VERSION ""

NS_ :

BS_:

BU_: CVC_I MHU TBOX FCAM_I MRR SRR_RL SRR_RR SRR_FL SRR_FR DUMMY_ECU ADCU_I AMP HUD

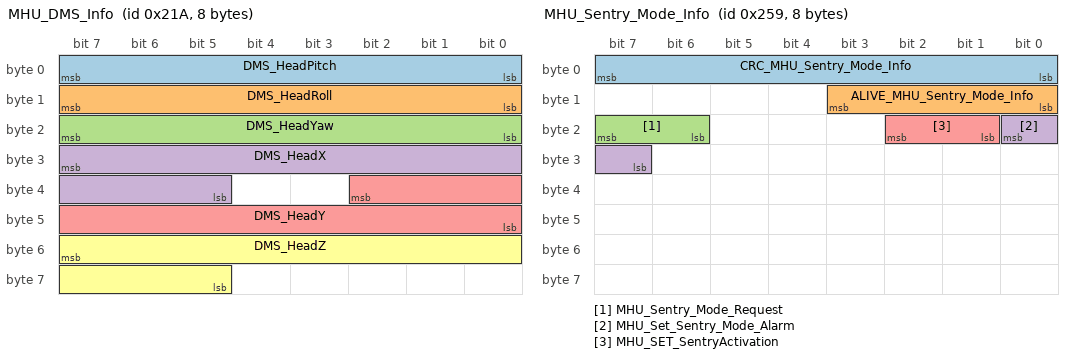
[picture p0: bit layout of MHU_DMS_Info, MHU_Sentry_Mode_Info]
BO_ 538 MHU_DMS_Info: 8 MHU
 SG_ DMS_HeadPitch : 7|8@0+ (1,-45) [-45|45] "degree"  CVC_I
 SG_ DMS_HeadRoll : 15|8@0+ (1,-45) [-45|45] "degree"  CVC_I
 SG_ DMS_HeadYaw : 23|8@0+ (1,-75) [-75|180] "degree"  CVC_I
 SG_ DMS_HeadX : 31|11@0+ (1,-500) [-500|1547] "mm"  CVC_I
 SG_ DMS_HeadY : 34|11@0+ (1,-500) [-500|1547] "mm"  CVC_I
 SG_ DMS_HeadZ : 55|11@0+ (1,-500) [-500|1547] "mm"  CVC_I

BO_ 599 MHU_RVC_Info: 8 MHU
 SG_ MHU_RVC_Request : 23|2@0+ (1,0) [0|3] ""  ADCU_I

BO_ 601 MHU_Sentry_Mode_Info: 8 MHU
 SG_ CRC_MHU_Sentry_Mode_Info : 7|8@0+ (1,0) [0|255] ""  ADCU_I
 SG_ ALIVE_MHU_Sentry_Mode_Info : 11|4@0+ (1,0) [0|15] ""  ADCU_I
 SG_ MHU_Sentry_Mode_Request : 23|2@0+ (1,0) [0|3] ""  ADCU_I
 SG_ MHU_Set_Sentry_Mode_Alarm : 16|2@0+ (1,0) [0|3] ""  ADCU_I
 SG_ MHU_SET_SentryActivation : 18|2@0+ (1,0) [0|3] ""  ADCU_I

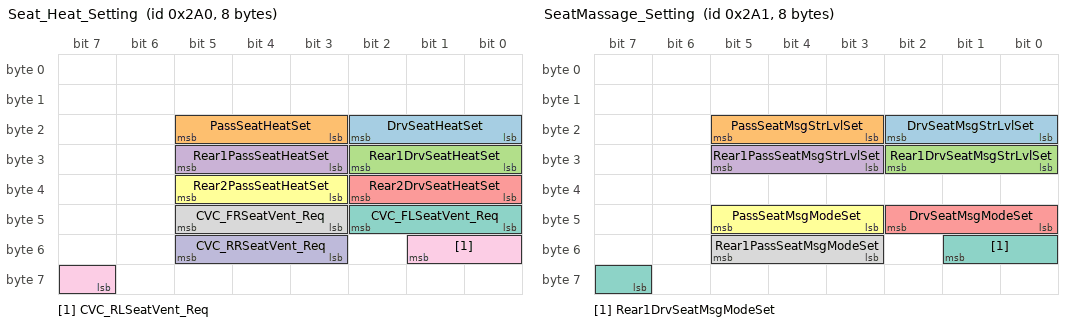
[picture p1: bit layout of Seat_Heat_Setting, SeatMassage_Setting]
BO_ 672 Seat_Heat_Setting: 8 MHU
 SG_ DrvSeatHeatSet : 18|3@0+ (1,0) [0|7] ""  CVC_I
 SG_ PassSeatHeatSet : 21|3@0+ (1,0) [0|7] ""  CVC_I
 SG_ Rear1DrvSeatHeatSet : 26|3@0+ (1,0) [0|7] "-"  CVC_I
 SG_ Rear1PassSeatHeatSet : 29|3@0+ (1,0) [0|7] ""  CVC_I
 SG_ Rear2DrvSeatHeatSet : 34|3@0+ (1,0) [0|7] ""  CVC_I
 SG_ Rear2PassSeatHeatSet : 37|3@0+ (1,0) [0|7] ""  CVC_I
 SG_ CVC_FLSeatVent_Req : 42|3@0+ (1,0) [0|7] ""  CVC_I
 SG_ CVC_FRSeatVent_Req : 45|3@0+ (1,0) [0|7] ""  CVC_I
 SG_ CVC_RLSeatVent_Req : 49|3@0+ (1,0) [0|7] ""  CVC_I
 SG_ CVC_RRSeatVent_Req : 53|3@0+ (1,0) [0|7] ""  CVC_I

BO_ 673 SeatMassage_Setting: 8 MHU
 SG_ DrvSeatMsgStrLvlSet : 18|3@0+ (1,0) [0|7] ""  CVC_I
 SG_ PassSeatMsgStrLvlSet : 21|3@0+ (1,0) [0|7] ""  CVC_I
 SG_ Rear1DrvSeatMsgStrLvlSet : 26|3@0+ (1,0) [0|7] ""  CVC_I
 SG_ Rear1PassSeatMsgStrLvlSet : 29|3@0+ (1,0) [0|7] ""  CVC_I
 SG_ DrvSeatMsgModeSet : 42|3@0+ (1,0) [0|7] ""  CVC_I
 SG_ PassSeatMsgModeSet : 45|3@0+ (1,0) [0|7] ""  CVC_I
 SG_ Rear1DrvSeatMsgModeSet : 49|3@0+ (1,0) [0|7] ""  CVC_I
 SG_ Rear1PassSeatMsgModeSet : 53|3@0+ (1,0) [0|7] ""  CVC_I

BO_ 753 MHU_IC_STAT_AIRBAG: 1 MHU
 SG_ MHU_STAT_AirbagWarnLamp : 1|2@0+ (1,0) [0|3] ""  CVC_I

BO_ 717 MHU_ADASISv2_Message_Container: 8 MHU
 SG_ MHU_ADASISv2_Container : 7|64@0+ (1,0) [0|1.84467440737096E+019] ""  FCAM_I,ADCU_I

BO_ 762 MHU_GPS_Time_UTC: 8 MHU
 SG_ MHU_GPS_Time_UTC : 7|64@0+ (1,0) [0|1.84467440737095E+019] "s"  CVC_I

BO_ 776 MHU_CPD_Confirm: 8 MHU
 SG_ MHU_CPD_Setting : 4|3@0+ (1,0) [0|7] ""  CVC_I
 SG_ MHU_CPD_Confirmation_On_HMI : 7|3@0+ (1,0) [0|7] ""  CVC_I

BO_ 788 MHU_RAEB: 24 MHU
 SG_ CRC_MHU_RAEB : 7|8@0+ (1,0) [0|255] ""  CVC_I,FCAM_I,ADCU_I
 SG_ ALIVE_MHU_RAEB : 11|4@0+ (1,0) [0|15] ""  CVC_I,FCAM_I,ADCU_I
 SG_ MHU_RAEB_check : 15|3@0+ (1,0) [0|7] ""  CVC_I,FCAM_I,ADCU_I
 SG_ MHU_RAEB_Warning : 30|3@0+ (1,0) [0|7] ""  CVC_I,FCAM_I,ADCU_I
 SG_ MHU_RAEB_State : 27|4@0+ (1,0) [0|15] ""  CVC_I,FCAM_I,ADCU_I
 SG_ MHU_RAEB_BrakeCommand : 23|3@0+ (1,0) [0|3] ""  CVC_I,FCAM_I,ADCU_I
 SG_ MHU_RAEB_Available : 17|2@0+ (1,0) [0|3] ""  CVC_I,FCAM_I,ADCU_I
 SG_ MHU_RAEB_FuncActive : 20|1@0+ (1,0) [0|1] ""  CVC_I,FCAM_I,ADCU_I
 SG_ MHU_RAEB_Mode_Feed : 19|2@0+ (1,0) [0|3] ""  CVC_I,FCAM_I,ADCU_I
 SG_ MHU_RAEB_BrakeType : 33|2@0+ (1,0) [0|3] ""  CVC_I,FCAM_I,ADCU_I
 SG_ MHU_RAEB_PullEPBOpt : 31|1@0+ (1,0) [0|1] ""  CVC_I,FCAM_I,ADCU_I
 SG_ Secure_ResetCnt_0x314 : 135|16@0+ (1,0) [0|65535] ""  CVC_I,FCAM_I,ADCU_I
 SG_ Secure_MsgCnt_0x314 : 151|16@0+ (1,0) [0|65535] ""  CVC_I,FCAM_I,ADCU_I
 SG_ Secure_MAC_0x314 : 167|32@0+ (1,0) [0|4294967295] ""  CVC_I,FCAM_I,ADCU_I
 SG_ MHU_RAEB_BrakeReq_Source : 36|3@0+ (1,0) [0|7] ""  CVC_I,FCAM_I

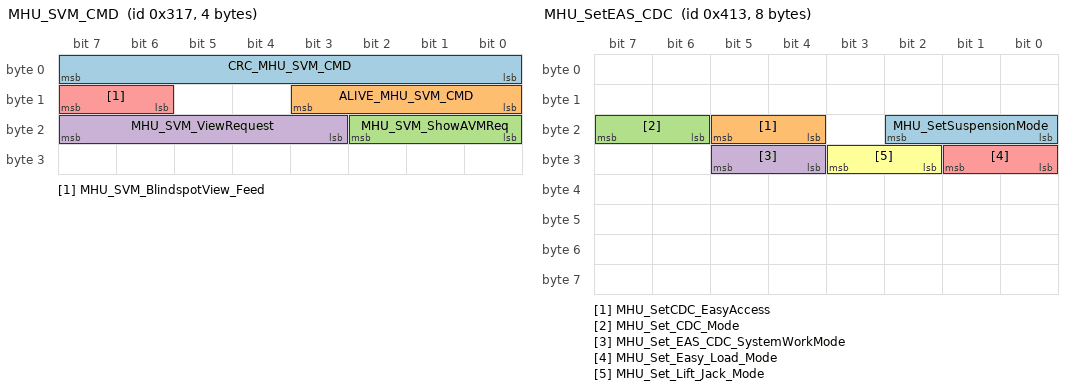
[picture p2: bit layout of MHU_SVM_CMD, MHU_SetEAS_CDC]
BO_ 791 MHU_SVM_CMD: 4 MHU
 SG_ CRC_MHU_SVM_CMD : 7|8@0+ (1,0) [0|255] ""  ADCU_I
 SG_ ALIVE_MHU_SVM_CMD : 11|4@0+ (1,0) [0|15] ""  ADCU_I
 SG_ MHU_SVM_ShowAVMReq : 18|3@0+ (1,0) [0|7] ""  ADCU_I
 SG_ MHU_SVM_ViewRequest : 23|5@0+ (1,0) [0|31] ""  ADCU_I
 SG_ MHU_SVM_BlindspotView_Feed : 15|2@0+ (1,0) [0|3] ""  ADCU_I

BO_ 800 MHU_GPS_Position_Info: 16 MHU
 SG_ Latitude : 7|32@0+ (1E-007,-180) [-180|180] "deg"  ADCU_I
 SG_ Longitude : 39|32@0+ (1E-007,-180) [-180|180] "deg"  ADCU_I
 SG_ Altitude : 71|16@0+ (0.1,-3276.7) [-3276.7|3276.7] "m"  ADCU_I
 SG_ Speed : 87|16@0+ (0.01,0) [0|655.35] "km/h"  ADCU_I
 SG_ Vertical_Speed : 103|16@0+ (0.01,-327.67) [-327.67|327.67] "m/s"  ADCU_I
 SG_ Heading : 119|16@0+ (0.010986,-360) [-180|179.995] "deg"  ADCU_I

BO_ 801 MHU_GPS_Position_DR: 20 MHU
 SG_ Latitude_DR : 7|32@0+ (1E-007,-180) [-180|180] "deg"  ADCU_I
 SG_ Longitude_DR : 39|32@0+ (1E-007,-180) [-180|180] "deg"  ADCU_I
 SG_ Course_DR : 71|16@0+ (0.01,0) [0|360] "deg"  ADCU_I
 SG_ Heading_DR : 87|16@0+ (0.010986,-360) [-180|179.995] "deg"  ADCU_I
 SG_ Heading_Std : 103|16@0+ (0.01,0) [0|655.35] "deg"  ADCU_I
 SG_ Roll : 119|16@0+ (0.010986,-360) [-180|179.995] "deg"  ADCU_I
 SG_ Pitch : 135|16@0+ (0.010986,-360) [-90.0081|89.9975] "deg"  ADCU_I
 SG_ DeadReckoning_Status : 151|8@0+ (1,0) [0|3] ""  ADCU_I

BO_ 802 MHU_GPS_Status: 20 MHU
 SG_ Unix_Timestamp : 7|32@0+ (1,0) [0|4294967295] "s"  ADCU_I
 SG_ GPS_Week : 39|16@0+ (1,0) [0|65535] "week"  ADCU_I
 SG_ Fix_Type : 55|8@0+ (1,0) [0|5] ""  ADCU_I
 SG_ Satellites_Used : 63|8@0+ (1,0) [0|255] ""  ADCU_I
 SG_ Satellites_Visible : 71|8@0+ (1,0) [0|255] ""  ADCU_I
 SG_ Fix_Quality : 79|8@0+ (1,0) [0|9] ""  ADCU_I
 SG_ HDOP : 87|16@0+ (0.01,0) [0|655.35] ""  ADCU_I
 SG_ VDOP : 103|16@0+ (0.01,0) [0|655.35] ""  ADCU_I
 SG_ PDOP : 119|16@0+ (0.01,0) [0|655.35] ""  ADCU_I
 SG_ Satellites_GPS : 135|8@0+ (1,0) [0|255] ""  ADCU_I
 SG_ Satellites_GLONASS : 143|8@0+ (1,0) [0|255] ""  ADCU_I
 SG_ Satellites_Galileo : 151|8@0+ (1,0) [0|255] ""  ADCU_I
 SG_ Satellites_BeiDou : 159|8@0+ (1,0) [0|255] ""  ADCU_I

BO_ 806 MHU_GPS_ECEF_Position: 16 MHU
 SG_ ECEF_X : 7|32@0+ (0.01,-21474836.47) [-21474836.47|21474836.47] "m"  ADCU_I
 SG_ ECEF_Y : 39|32@0+ (0.01,-21474836.47) [-21474836.47|21474836.47] "m"  ADCU_I
 SG_ ECEF_Z : 71|32@0+ (0.01,-21474836.47) [-21474836.47|21474836.47] "m"  ADCU_I
 SG_ ECEF_Std : 103|16@0+ (0.01,0) [0|655.35] "m"  ADCU_I

BO_ 804 MHU_HOD_Heating: 2 MHU
 SG_ Steering_HeatingControl : 7|2@0+ (1,0) [0|3] ""  CVC_I

BO_ 1043 MHU_SetEAS_CDC: 8 MHU
 SG_ MHU_SetSuspensionMode : 18|3@0+ (1,0) [0|7] ""  CVC_I,FCAM_I,ADCU_I
 SG_ MHU_SetCDC_EasyAccess : 21|2@0+ (1,0) [0|3] ""  CVC_I,FCAM_I,ADCU_I
 SG_ MHU_Set_CDC_Mode : 23|2@0+ (1,0) [0|3] ""  CVC_I,FCAM_I,ADCU_I
 SG_ MHU_Set_EAS_CDC_SystemWorkMode : 29|2@0+ (1,0) [0|3] ""  CVC_I,FCAM_I,ADCU_I
 SG_ MHU_Set_Easy_Load_Mode : 25|2@0+ (1,0) [0|3] ""  CVC_I,FCAM_I,ADCU_I
 SG_ MHU_Set_Lift_Jack_Mode : 27|2@0+ (1,0) [0|3] ""  CVC_I,FCAM_I,ADCU_I

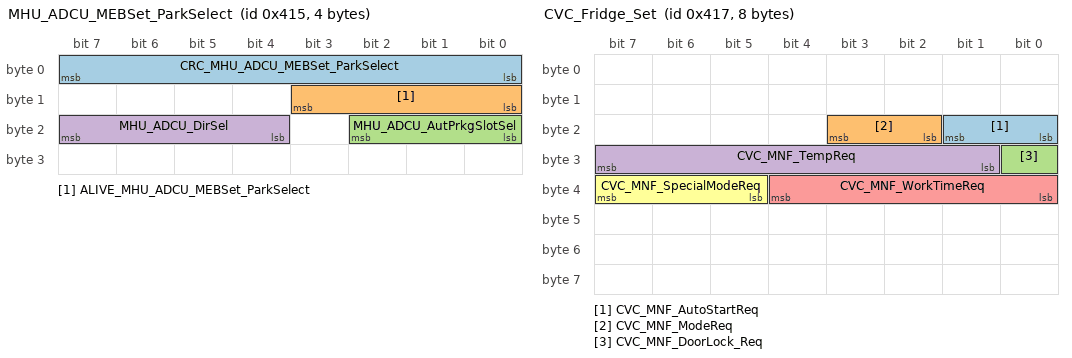
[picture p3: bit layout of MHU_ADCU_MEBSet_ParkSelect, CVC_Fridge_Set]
BO_ 1045 MHU_ADCU_MEBSet_ParkSelect: 4 MHU
 SG_ CRC_MHU_ADCU_MEBSet_ParkSelect : 7|8@0+ (1,0) [0|255] ""  ADCU_I
 SG_ ALIVE_MHU_ADCU_MEBSet_ParkSelect : 11|4@0+ (1,0) [0|15] ""  ADCU_I
 SG_ MHU_ADCU_AutPrkgSlotSel : 18|3@0+ (1,0) [0|7] ""  ADCU_I
 SG_ MHU_ADCU_DirSel : 23|4@0+ (1,0) [0|15] ""  ADCU_I

BO_ 1047 CVC_Fridge_Set: 8 CVC_I
 SG_ CVC_MNF_AutoStartReq : 17|2@0+ (1,0) [0|3] ""  MHU
 SG_ CVC_MNF_ModeReq : 19|2@0+ (1,0) [0|3] ""  MHU
 SG_ CVC_MNF_DoorLock_Req : 24|1@0+ (1,0) [0|1] ""  MHU
 SG_ CVC_MNF_TempReq : 31|7@0+ (1,-10) [-10|116] "Degree C"  MHU
 SG_ CVC_MNF_WorkTimeReq : 36|5@0+ (1,0) [0|24] "h"  MHU
 SG_ CVC_MNF_SpecialModeReq : 39|3@0+ (1,0) [0|7] ""  MHU

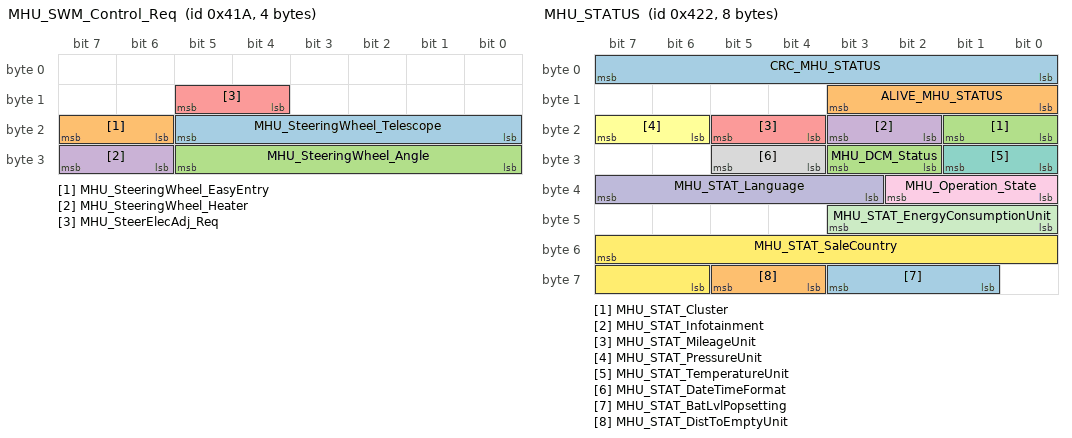
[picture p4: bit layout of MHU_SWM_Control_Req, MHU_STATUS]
BO_ 1050 MHU_SWM_Control_Req: 4 MHU
 SG_ MHU_SteeringWheel_Telescope : 21|6@0+ (1,-20) [-20|20] "mm"  CVC_I
 SG_ MHU_SteeringWheel_EasyEntry : 23|2@0+ (1,0) [0|3] ""  CVC_I
 SG_ MHU_SteeringWheel_Angle : 29|6@0+ (0.1,-2.1) [-2.1|2.1] "Degree"  CVC_I
 SG_ MHU_SteeringWheel_Heater : 31|2@0+ (1,0) [0|3] ""  CVC_I
 SG_ MHU_SteerElecAdj_Req : 13|2@0+ (1,0) [0|3] ""  CVC_I

BO_ 1058 MHU_STATUS: 8 MHU
 SG_ CRC_MHU_STATUS : 7|8@0+ (1,0) [0|255] ""  CVC_I,FCAM_I,SRR_RR,ADCU_I
 SG_ ALIVE_MHU_STATUS : 11|4@0+ (1,0) [0|15] ""  CVC_I,FCAM_I,SRR_RR,ADCU_I
 SG_ MHU_STAT_Cluster : 17|2@0+ (1,0) [0|3] ""  CVC_I,FCAM_I,SRR_RR,ADCU_I
 SG_ MHU_STAT_Infotainment : 19|2@0+ (1,0) [0|3] ""  CVC_I,FCAM_I,SRR_RR,ADCU_I
 SG_ MHU_STAT_MileageUnit : 21|2@0+ (1,0) [0|3] ""  CVC_I,FCAM_I,SRR_RR,ADCU_I
 SG_ MHU_STAT_PressureUnit : 23|2@0+ (1,0) [0|3] ""  CVC_I,ADCU_I
 SG_ MHU_STAT_TemperatureUnit : 25|2@0+ (1,0) [0|3] ""  CVC_I,ADCU_I
 SG_ MHU_STAT_DateTimeFormat : 29|2@0+ (1,0) [0|3] ""  CVC_I,ADCU_I
 SG_ MHU_Operation_State : 34|3@0+ (1,0) [0|7] ""  CVC_I,FCAM_I,SRR_RR,ADCU_I
 SG_ MHU_STAT_Language : 39|5@0+ (1,0) [0|31] ""  CVC_I,ADCU_I
 SG_ MHU_STAT_EnergyConsumptionUnit : 43|4@0+ (1,0) [0|15] ""  CVC_I,FCAM_I,SRR_RR,ADCU_I
 SG_ MHU_STAT_SaleCountry : 55|10@0+ (1,0) [0|1023] ""  CVC_I,FCAM_I,SRR_RR,ADCU_I
 SG_ MHU_STAT_BatLvlPopsetting : 59|3@0+ (1,0) [0|7] ""  CVC_I,ADCU_I
 SG_ MHU_STAT_DistToEmptyUnit : 61|2@0+ (1,0) [0|3] ""  CVC_I,ADCU_I
 SG_ MHU_DCM_Status : 27|2@0+ (1,0) [0|3] ""  CVC_I,ADCU_I

BO_ 1092 MHU_FCAM_RP_Ctrl: 24 MHU
 SG_ CRC_MHU_FCAM_RP_Ctrl : 7|8@0+ (1,0) [0|255] ""  CVC_I,FCAM_I,ADCU_I
 SG_ ALIVE_MHU_FCAM_RP_Ctrl : 11|4@0+ (1,0) [0|15] ""  CVC_I,FCAM_I,ADCU_I
 SG_ MHU_RPParkingstartReq : 15|1@0+ (1,0) [0|1] ""  CVC_I,FCAM_I,ADCU_I
 SG_ MHU_RP_ParkOutModeConfirm : 17|2@0+ (1,0) [0|3] ""  CVC_I,FCAM_I,ADCU_I
 SG_ MHU_RP_ParkOutDircnConfirm : 19|2@0+ (1,0) [0|3] ""  CVC_I,FCAM_I,ADCU_I
 SG_ MHU_RemoteconnectionSts : 23|2@0+ (1,0) [0|3] ""  CVC_I,FCAM_I,ADCU_I
 SG_ MHU_RP_FuncMode : 26|3@0+ (1,0) [0|7] ""  CVC_I,FCAM_I,ADCU_I
 SG_ MHU_SMParkingstartReq : 27|1@0+ (1,0) [0|1] ""  CVC_I,FCAM_I,ADCU_I
 SG_ MHU_SMParkingControlReq : 28|1@0+ (1,0) [0|1] ""  CVC_I,FCAM_I,ADCU_I
 SG_ MHU_RP_RecoverParking : 29|1@0+ (1,0) [0|1] ""  CVC_I,FCAM_I,ADCU_I
 SG_ MHU_RPStraightParkingDir : 31|2@0+ (1,0) [0|3] ""  CVC_I,FCAM_I,ADCU_I
 SG_ MHU_SM_global_path_Status : 33|2@0+ (1,0) [0|3] ""  CVC_I,FCAM_I,ADCU_I
 SG_ MHU_SM_QuitReq : 39|2@0+ (1,0) [0|3] ""  CVC_I,FCAM_I,ADCU_I
 SG_ MHU_RPParkingControlReq : 44|1@0+ (1,0) [0|1] ""  CVC_I,FCAM_I,ADCU_I
 SG_ MHU_RP_QuitReq : 52|2@0+ (1,0) [0|3] ""  CVC_I,FCAM_I,ADCU_I
 SG_ Secure_ResetCnt_0x444 : 135|16@0+ (1,0) [0|65535] ""  CVC_I,FCAM_I,ADCU_I
 SG_ Secure_MsgCnt_0x444 : 151|16@0+ (1,0) [0|65535] ""  CVC_I,FCAM_I,ADCU_I
 SG_ Secure_MAC_0x444 : 167|32@0+ (1,0) [0|4294967295] ""  CVC_I,FCAM_I,ADCU_I

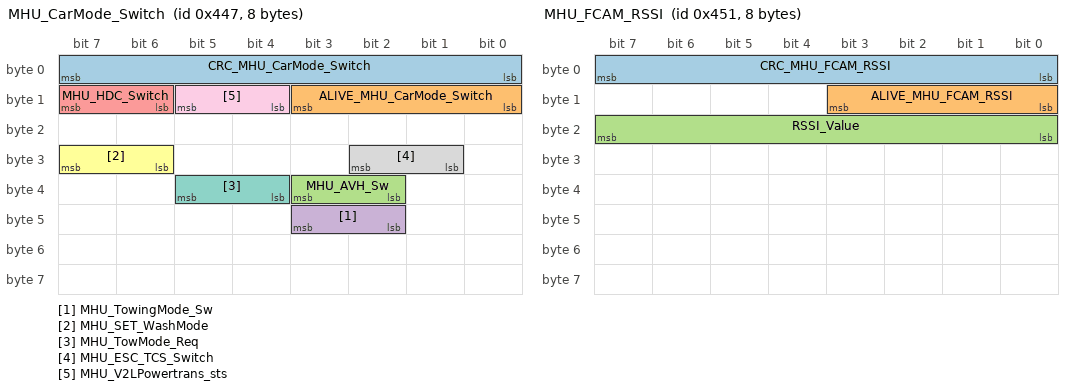
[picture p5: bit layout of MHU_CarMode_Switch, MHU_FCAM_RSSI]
BO_ 1095 MHU_CarMode_Switch: 8 MHU
 SG_ CRC_MHU_CarMode_Switch : 7|8@0+ (1,0) [0|255] ""  CVC_I
 SG_ ALIVE_MHU_CarMode_Switch : 11|4@0+ (1,0) [0|15] ""  CVC_I
 SG_ MHU_AVH_Sw : 35|2@0+ (1,0) [0|3] ""  CVC_I
 SG_ MHU_TowingMode_Sw : 43|2@0+ (1,0) [0|3] ""  CVC_I
 SG_ MHU_HDC_Switch : 15|2@0+ (1,0) [0|3] ""  CVC_I
 SG_ MHU_SET_WashMode : 31|2@0+ (1,0) [0|3] ""  CVC_I
 SG_ MHU_TowMode_Req : 37|2@0+ (1,0) [0|3] ""  CVC_I
 SG_ MHU_ESC_TCS_Switch : 26|2@0+ (1,0) [0|3] ""  CVC_I
 SG_ MHU_V2LPowertrans_sts : 13|2@0+ (1,0) [0|3] ""  CVC_I

BO_ 1105 MHU_FCAM_RSSI: 8 MHU
 SG_ CRC_MHU_FCAM_RSSI : 7|8@0+ (1,0) [0|255] ""  FCAM_I,ADCU_I
 SG_ ALIVE_MHU_FCAM_RSSI : 11|4@0+ (1,0) [0|15] ""  FCAM_I,ADCU_I
 SG_ RSSI_Value : 23|8@0+ (1,0) [0|255] ""  FCAM_I,ADCU_I

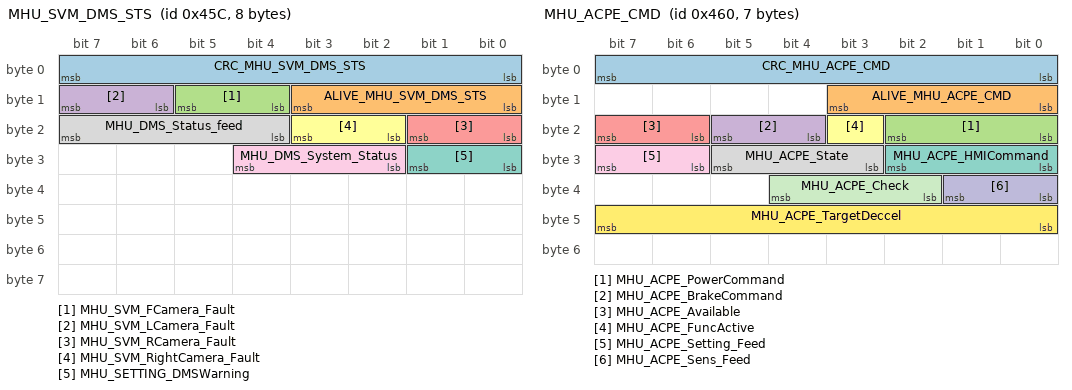
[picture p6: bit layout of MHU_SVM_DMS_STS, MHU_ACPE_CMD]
BO_ 1116 MHU_SVM_DMS_STS: 8 MHU
 SG_ CRC_MHU_SVM_DMS_STS : 7|8@0+ (1,0) [0|255] ""  CVC_I
 SG_ ALIVE_MHU_SVM_DMS_STS : 11|4@0+ (1,0) [0|15] ""  CVC_I
 SG_ MHU_SVM_FCamera_Fault : 13|2@0+ (1,0) [0|3] ""  CVC_I
 SG_ MHU_SVM_LCamera_Fault : 15|2@0+ (1,0) [0|3] ""  CVC_I
 SG_ MHU_SVM_RCamera_Fault : 17|2@0+ (1,0) [0|3] ""  CVC_I
 SG_ MHU_SVM_RightCamera_Fault : 19|2@0+ (1,0) [0|3] ""  CVC_I
 SG_ MHU_SETTING_DMSWarning : 25|2@0+ (1,0) [0|3] ""  CVC_I
 SG_ MHU_DMS_Status_feed : 23|4@0+ (1,0) [0|15] ""  CVC_I
 SG_ MHU_DMS_System_Status : 28|3@0+ (1,0) [0|7] ""  CVC_I

BO_ 1120 MHU_ACPE_CMD: 7 MHU
 SG_ CRC_MHU_ACPE_CMD : 7|8@0+ (1,0) [0|255] ""  CVC_I,FCAM_I
 SG_ ALIVE_MHU_ACPE_CMD : 11|4@0+ (1,0) [0|15] ""  CVC_I,FCAM_I
 SG_ MHU_ACPE_PowerCommand : 18|3@0+ (1,0) [0|7] ""  CVC_I
 SG_ MHU_ACPE_BrakeCommand : 21|2@0+ (1,0) [0|3] ""  CVC_I,FCAM_I
 SG_ MHU_ACPE_Available : 23|2@0+ (1,0) [0|3] ""  CVC_I,FCAM_I
 SG_ MHU_ACPE_FuncActive : 19|1@0+ (1,0) [0|1] ""  CVC_I,FCAM_I
 SG_ MHU_ACPE_HMICommand : 26|3@0+ (1,0) [0|7] ""  CVC_I
 SG_ MHU_ACPE_State : 29|3@0+ (1,0) [0|7] ""  CVC_I,FCAM_I
 SG_ MHU_ACPE_Setting_Feed : 31|2@0+ (1,0) [0|3] ""  CVC_I
 SG_ MHU_ACPE_Sens_Feed : 33|2@0+ (1,0) [0|3] ""  CVC_I
 SG_ MHU_ACPE_Check : 36|3@0+ (1,0) [0|7] ""  CVC_I,FCAM_I
 SG_ MHU_ACPE_TargetDeccel : 47|8@0+ (0.1,-6.5) [-6.5|6.5] "m/s2"  CVC_I,FCAM_I

BO_ 1969 MHU_Synchronization_Req: 8 MHU
 SG_ MHU_Req_RandomData : 7|24@0+ (1,0) [0|16777215] ""  CVC_I
 SG_ MHU_Req_MAC : 31|40@0+ (1,0) [0|1099511627775] ""  CVC_I

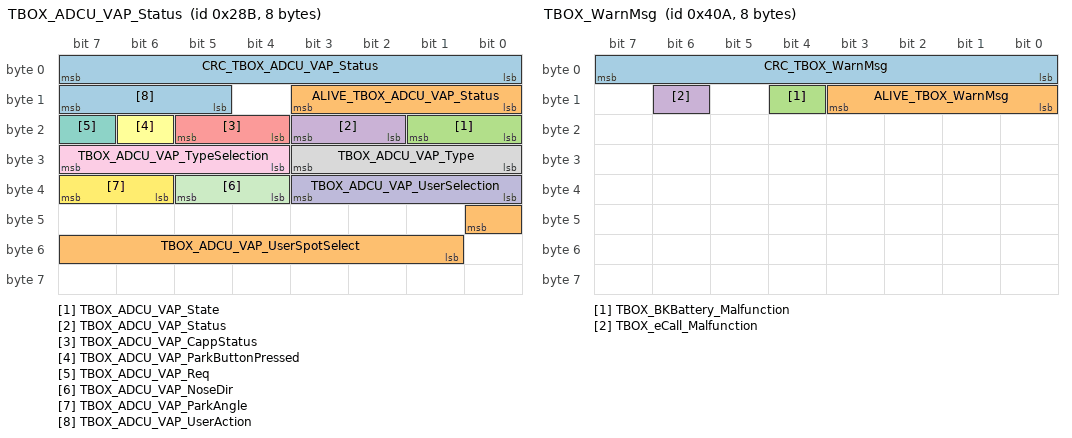
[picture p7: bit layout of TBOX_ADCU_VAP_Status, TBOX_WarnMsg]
BO_ 651 TBOX_ADCU_VAP_Status: 8 TBOX
 SG_ CRC_TBOX_ADCU_VAP_Status : 7|8@0+ (1,0) [0|255] ""  ADCU_I
 SG_ ALIVE_TBOX_ADCU_VAP_Status : 11|4@0+ (1,0) [0|15] ""  ADCU_I
 SG_ TBOX_ADCU_VAP_State : 17|2@0+ (1,0) [0|3] ""  ADCU_I
 SG_ TBOX_ADCU_VAP_Status : 19|2@0+ (1,0) [0|3] ""  ADCU_I
 SG_ TBOX_ADCU_VAP_CappStatus : 21|2@0+ (1,0) [0|3] ""  ADCU_I
 SG_ TBOX_ADCU_VAP_ParkButtonPressed : 22|1@0+ (1,0) [0|1] ""  ADCU_I
 SG_ TBOX_ADCU_VAP_Req : 23|1@0+ (1,0) [0|1] ""  ADCU_I
 SG_ TBOX_ADCU_VAP_Type : 27|4@0+ (1,0) [0|15] ""  ADCU_I
 SG_ TBOX_ADCU_VAP_TypeSelection : 31|4@0+ (1,0) [0|15] ""  ADCU_I
 SG_ TBOX_ADCU_VAP_UserSelection : 35|4@0+ (1,0) [0|15] ""  ADCU_I
 SG_ TBOX_ADCU_VAP_NoseDir : 37|2@0+ (1,0) [0|3] ""  ADCU_I
 SG_ TBOX_ADCU_VAP_ParkAngle : 39|2@0+ (1,0) [0|3] ""  ADCU_I
 SG_ TBOX_ADCU_VAP_UserAction : 15|3@0+ (1,0) [0|7] ""  ADCU_I
 SG_ TBOX_ADCU_VAP_UserSpotSelect : 40|8@0+ (1,0) [0|255] ""  ADCU_I

BO_ 761 TBOX_GPS_Time_UTC: 8 TBOX
 SG_ TBOX_GPS_Time_UTC : 7|64@0+ (1,0) [0|1.84467440737095E+019] "s"  CVC_I,MHU

BO_ 1033 TBOX_IntrusionAlertStatus: 8 TBOX
 SG_ TBOX_IntrusionAlertStatus : 31|2@0+ (1,0) [0|3] ""  CVC_I

BO_ 1034 TBOX_WarnMsg: 8 TBOX
 SG_ CRC_TBOX_WarnMsg : 7|8@0+ (1,0) [0|255] ""  MHU
 SG_ ALIVE_TBOX_WarnMsg : 11|4@0+ (1,0) [0|15] ""  MHU
 SG_ TBOX_BKBattery_Malfunction : 12|1@0+ (1,0) [0|1] ""  MHU
 SG_ TBOX_eCall_Malfunction : 14|1@0+ (1,0) [0|1] ""  MHU

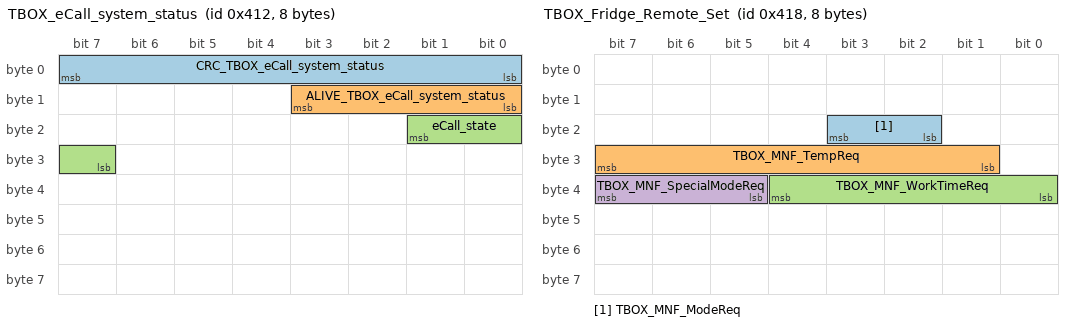
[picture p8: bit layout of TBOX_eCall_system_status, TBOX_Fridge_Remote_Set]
BO_ 1042 TBOX_eCall_system_status: 8 TBOX
 SG_ CRC_TBOX_eCall_system_status : 7|8@0+ (1,0) [0|255] ""  CVC_I,MHU,FCAM_I,SRR_RR,ADCU_I
 SG_ ALIVE_TBOX_eCall_system_status : 11|4@0+ (1,0) [0|15] ""  CVC_I,MHU,FCAM_I,SRR_RR,ADCU_I
 SG_ eCall_state : 17|3@0+ (1,0) [0|7] ""  CVC_I,MHU,FCAM_I,SRR_RR,ADCU_I

BO_ 1046 TBOX_GPS_ALTITUDE: 8 TBOX
 SG_ TBOX_GPS_ALTITUDE : 23|17@0+ (0.1,-4000) [-4000|9000] "m"  CVC_I,MHU,FCAM_I

BO_ 1048 TBOX_Fridge_Remote_Set: 8 TBOX
 SG_ TBOX_MNF_ModeReq : 19|2@0+ (1,0) [0|3] ""  CVC_I
 SG_ TBOX_MNF_TempReq : 31|7@0+ (1,-10) [-10|116] "Degree C"  CVC_I
 SG_ TBOX_MNF_WorkTimeReq : 36|5@0+ (1,0) [0|24] "h"  CVC_I
 SG_ TBOX_MNF_SpecialModeReq : 39|3@0+ (1,0) [0|7] ""  CVC_I

BO_ 128 FCAM_TSR_STATUS: 12 FCAM_I
 SG_ CRC_FCAM_TSR_STATUS : 7|8@0+ (1,0) [0|255] ""  CVC_I,MHU,ADCU_I
 SG_ ALIVE_FCAM_TSR_STATUS : 11|4@0+ (1,0) [0|15] ""  CVC_I,MHU,ADCU_I
 SG_ FCAM_TSR_PopUp_Feed : 15|4@0+ (1,0) [0|15] ""  CVC_I,MHU,ADCU_I
 SG_ FCAM_TSR_SLAert_Feed : 18|2@0+ (1,0) [0|3] ""  CVC_I,MHU,ADCU_I
 SG_ FCAM_TSR_Typ2_value : 23|5@0+ (1,0) [0|31] ""  CVC_I,MHU,ADCU_I
 SG_ FCAM_TSR_Typ1 : 26|3@0+ (1,0) [0|7] ""  CVC_I,MHU,ADCU_I
 SG_ FCAM_TSR_Typ1_value : 31|5@0+ (1,0) [0|31] ""  CVC_I,MHU,ADCU_I
 SG_ FCAM_TSR_Warning_audible : 16|1@0+ (1,0) [0|1] ""  CVC_I,MHU,ADCU_I
 SG_ FCAM_TSR_Typ2_Flashing_Warning : 34|1@0+ (1,0) [0|1] ""  CVC_I,MHU,ADCU_I
 SG_ FCAM_TSR_Mode_Feed : 36|2@0+ (1,0) [0|3] ""  CVC_I,MHU,ADCU_I
 SG_ FCAM_TSR_AudWarning_Feed : 39|3@0+ (1,0) [0|1] ""  CVC_I,MHU,ADCU_I
 SG_ FCAM_TSR_Typ1_Flashing_Warning : 33|1@0+ (1,0) [0|1] ""  CVC_I,MHU,ADCU_I
 SG_ FCAM_TSR_Typ3 : 52|9@0+ (1,0) [0|511] ""  CVC_I,MHU,ADCU_I
 SG_ FCAM_TSR_Typ2 : 45|9@0+ (1,0) [0|511] ""  CVC_I,MHU,ADCU_I
 SG_ FCAM_TSR_State : 32|3@0+ (1,0) [0|7] ""  CVC_I,MHU,ADCU_I
 SG_ FCAM_TSR_Haptic_Mode_Feed : 59|1@0+ (1,0) [0|1] ""  CVC_I,MHU,ADCU_I
 SG_ FCAM_SLW_Mode_Feed : 58|1@0+ (1,0) [0|1] ""  CVC_I,MHU,ADCU_I
 SG_ FCAM_DNS_Popup_Feed : 57|2@0+ (1,0) [0|3] ""  CVC_I,MHU,ADCU_I
 SG_ FCAM_TSR_Typ1_Distance : 71|20@0+ (1,0) [0|1048575] "m"  ADCU_I

BO_ 295 FCAM_LDW_LKA_ELK: 8 FCAM_I
 SG_ CRC_FCAM_LDW_LKA_ELK : 7|8@0+ (1,0) [0|255] ""  CVC_I,MHU,ADCU_I
 SG_ ALIVE_FCAM_LDW_LKA_ELK : 11|4@0+ (1,0) [0|15] ""  CVC_I,MHU,ADCU_I
 SG_ FCAM_ELKA_ON_feed : 12|1@0+ (1,0) [0|1] ""  CVC_I,MHU
 SG_ FCAM_LKA_HOD_state : 32|1@0+ (1,0) [0|1] ""  CVC_I,MHU
 SG_ FCAM_ECU_check : 19|2@0+ (1,0) [0|3] ""  CVC_I,MHU,ADCU_I
 SG_ FCAM_LA_sens_Feed : 21|2@0+ (1,0) [0|3] ""  CVC_I,MHU
 SG_ FCAM_LKA_ICON_Feed : 29|3@0+ (1,0) [0|7] ""  CVC_I,MHU
 SG_ FCAM_LDW_check : 17|2@0+ (1,0) [0|3] ""  CVC_I,MHU,ADCU_I
 SG_ FCAM_LKA_check : 31|2@0+ (1,0) [0|3] ""  CVC_I,MHU,ADCU_I
 SG_ FCAM_LA_popup : 39|3@0+ (1,0) [0|7] ""  CVC_I,MHU
 SG_ FCAM_LA_Mode_Feed : 44|3@0+ (1,0) [0|7] ""  CVC_I,MHU
 SG_ FCAM_LA_LeftLaneColor_Feed : 26|3@0+ (1,0) [0|7] ""  CVC_I,MHU
 SG_ FCAM_LA_RightLaneColor_Feed : 15|3@0+ (1,0) [0|7] ""  CVC_I,MHU
 SG_ FCAM_ELK_check : 23|2@0+ (1,0) [0|3] ""  CVC_I,MHU,ADCU_I
 SG_ FCAM_ELK_State : 47|3@0+ (1,0) [0|7] ""  CVC_I,MHU
 SG_ FCAM_LKA_State : 60|3@0+ (1,0) [0|7] ""  CVC_I,MHU
 SG_ FCAM_LDW_State : 51|3@0+ (1,0) [0|7] ""  CVC_I,MHU
 SG_ FCAM_ELK_Warning : 55|4@0+ (1,0) [0|15] ""  CVC_I,MHU
 SG_ FCAM_LDW_Warning : 41|2@0+ (1,0) [0|3] ""  CVC_I,MHU
 SG_ FCAM_handsoff_Warning_Mode_2 : 63|3@0+ (1,0) [0|7] ""  CVC_I,MHU
 SG_ FCAM_LKA_LDW_Haptic_Mode_Feed : 34|1@0+ (1,0) [0|3] ""  CVC_I,MHU
 SG_ FCAM_ELK_Haptic_Mode_Feed : 33|1@0+ (1,0) [0|3] ""  CVC_I,MHU
 SG_ FCAM_LKA_Warning : 36|2@0+ (1,0) [0|3] ""  CVC_I,MHU

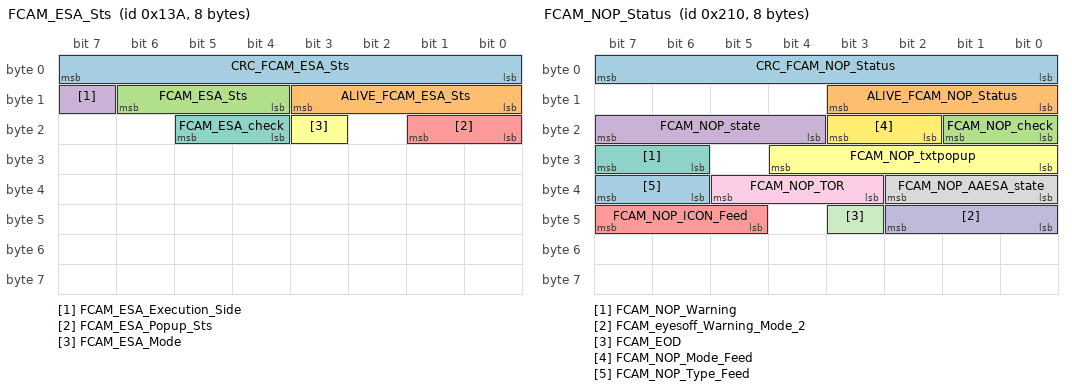
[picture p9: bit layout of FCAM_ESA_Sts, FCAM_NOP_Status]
BO_ 314 FCAM_ESA_Sts: 8 FCAM_I
 SG_ CRC_FCAM_ESA_Sts : 7|8@0+ (1,0) [0|255] ""  CVC_I,MHU,ADCU_I
 SG_ ALIVE_FCAM_ESA_Sts : 11|4@0+ (1,0) [0|15] ""  CVC_I,MHU,ADCU_I
 SG_ FCAM_ESA_Sts : 14|3@0+ (1,0) [0|7] ""  CVC_I,MHU
 SG_ FCAM_ESA_Execution_Side : 15|1@0+ (1,0) [0|1] ""  CVC_I,MHU
 SG_ FCAM_ESA_Popup_Sts : 17|2@0+ (1,0) [0|3] ""  CVC_I,MHU
 SG_ FCAM_ESA_Mode : 19|1@0+ (1,0) [0|1] ""  CVC_I,MHU
 SG_ FCAM_ESA_check : 21|2@0+ (1,0) [0|3] ""  CVC_I,MHU,ADCU_I

BO_ 515 FCAM_Display_Info: 16 FCAM_I
 SG_ CRC_FCAM_Display_Info : 7|8@0+ (1,0) [0|255] ""  CVC_I,MHU,ADCU_I
 SG_ ALIVE_FCAM_Display_Info : 11|4@0+ (1,0) [0|15] ""  CVC_I,MHU,ADCU_I
 SG_ R1_LINE_TYPE : 13|2@0+ (1,0) [0|3] ""  CVC_I,MHU
 SG_ R0_LINE_TYPE : 15|2@0+ (1,0) [0|3] ""  CVC_I,MHU
 SG_ FCAM_CIPV_RelLgtVel : 23|16@0+ (1,-32768) [-32768|32767] "MPS"  CVC_I,MHU
 SG_ FCAM_CIPV_OffsetEgoLane : 39|16@0+ (1,-32768) [-32768|32767] "M"  CVC_I,MHU
 SG_ FCAM_CIPV_OffseLaneLine : 55|16@0+ (1,-32768) [-32768|32767] "M"  CVC_I,MHU
 SG_ FCAM_Camera_R1_Line_Type : 71|2@0+ (1,0) [0|3] ""  CVC_I,MHU
 SG_ FCAM_Camera_L1_Line_Type : 69|2@0+ (1,0) [0|3] ""  CVC_I,MHU
 SG_ FCAM_R0_ExistProbability : 67|4@0+ (0.1,0) [0|1] ""  CVC_I,MHU
 SG_ FCAM_L0_ExistProbability : 79|4@0+ (0.1,0) [0|1] ""  CVC_I,MHU
 SG_ FCAM_L1_ExistProbability : 75|4@0+ (0.1,0) [0|1] ""  CVC_I,MHU
 SG_ FCAM_R1_ExistProbability : 87|4@0+ (0.1,0) [0|1] ""  CVC_I,MHU
 SG_ FCAM_ISA_SpeedLimitCnt_Spd_Feed : 83|4@0+ (1,0) [0|15] ""  CVC_I,MHU
 SG_ FCAM_ISA_SpeedLimitCnt_Per_Feed : 95|3@0+ (1,0) [0|7] ""  CVC_I,MHU
 SG_ L1_LINE_TYPE : 90|2@0+ (1,0) [0|3] ""  CVC_I,MHU
 SG_ L0_LINE_TYPE : 103|2@0+ (1,0) [0|3] ""  CVC_I,MHU
 SG_ FCAM_SCAM_Fault : 101|2@0+ (1,0) [0|3] ""  CVC_I,MHU,ADCU_I
 SG_ FCAM_MRR_Fault : 99|2@0+ (1,0) [0|3] ""  CVC_I,MHU,ADCU_I
 SG_ FCAM_Collision_Obj_ID : 111|8@0+ (1,0) [0|255] ""  MHU

BO_ 518 FCAM_HWA_ALC: 12 FCAM_I
 SG_ CRC_FCAM_HWA_ALC : 7|8@0+ (1,0) [0|255] ""  CVC_I,MHU,ADCU_I
 SG_ ALIVE_FCAM_HWA_ALC : 11|4@0+ (1,0) [0|15] ""  CVC_I,MHU,ADCU_I
 SG_ FCAM_HWA_Fautlstate : 13|2@0+ (1,0) [0|3] ""  CVC_I,MHU,ADCU_I
 SG_ FCAM_ALC_Mode_feed : 15|2@0+ (1,0) [0|3] ""  CVC_I,MHU,ADCU_I
 SG_ FCAM_HWA_txtpopup : 23|4@0+ (1,0) [0|15] ""  CVC_I,MHU,ADCU_I
 SG_ FCAM_HWA_state : 19|4@0+ (1,0) [0|15] ""  CVC_I,MHU,ADCU_I
 SG_ FCAM_ALC_txtpopup : 39|4@0+ (1,0) [0|15] ""  CVC_I,MHU,ADCU_I
 SG_ FCAM_ALC_state : 26|3@0+ (1,0) [0|7] ""  CVC_I,MHU,ADCU_I
 SG_ FCAM_AESA_DoorUnlock_Req : 32|1@0+ (1,0) [0|1] ""  CVC_I,MHU,ADCU_I
 SG_ FCAM_AESA_ECALL_Req : 33|1@0+ (1,0) [0|1] ""  CVC_I,MHU,TBOX,ADCU_I
 SG_ FCAM_AESA_Status : 35|2@0+ (1,0) [0|3] ""  CVC_I,MHU,ADCU_I
 SG_ FCAM_AESA_popup : 55|8@0+ (1,0) [0|6] ""  CVC_I,MHU,ADCU_I
 SG_ FCAM_TakeOver_Request : 31|5@0+ (1,0) [0|31] ""  CVC_I,MHU,ADCU_I
 SG_ FCAM_Sounds_Feed : 47|5@0+ (1,0) [0|31] ""  CVC_I,MHU,ADCU_I
 SG_ FCAM_ALC_ICON_Feed : 59|4@0+ (1,0) [0|15] ""  CVC_I,MHU,ADCU_I
 SG_ FCAM_HWA_ICON_Feed : 42|3@0+ (1,0) [0|7] ""  CVC_I,MHU,ADCU_I
 SG_ FCAM_ALC_Mode_Gaze_Feed : 63|2@0+ (1,0) [0|3] ""  CVC_I,MHU,ADCU_I
 SG_ FCAM_ALC_Mode_Recommend_Feed : 61|2@0+ (1,0) [0|3] ""  CVC_I,MHU,ADCU_I
 SG_ FCAM_HWA_check : 65|2@0+ (1,0) [0|3] ""  CVC_I,MHU,ADCU_I
 SG_ FCAM_MHU_ALC_Option_feed : 67|2@0+ (1,0) [0|3] ""  CVC_I,MHU,ADCU_I
 SG_ FCAM_EOR_warning : 70|3@0+ (1,0) [0|7] ""  CVC_I,MHU,ADCU_I
 SG_ FCAM_HWA_Mode_Feed : 71|1@0+ (1,0) [0|1] ""  CVC_I,MHU,ADCU_I

BO_ 527 FCAM_LKA_ELK: 24 FCAM_I
 SG_ CRC_FCAM_LKA_ELK : 7|8@0+ (1,0) [0|255] ""  CVC_I,MHU
 SG_ ALIVE_FCAM_LKA_ELK : 11|4@0+ (1,0) [0|15] ""  CVC_I,MHU
 SG_ FCAM_ELK_ONCM_VEH : 14|1@0+ (1,0) [0|1] ""  CVC_I,MHU
 SG_ FCAM_ELK_ONCM_TTC : 71|16@0+ (1,0) [0|65535] ""  CVC_I,MHU
 SG_ FCAM_ELK_OVTVEH_L : 13|1@0+ (1,0) [0|1] ""  CVC_I,MHU
 SG_ FCAM_ELK_OVTVEH_R : 12|1@0+ (1,0) [0|1] ""  CVC_I,MHU
 SG_ FCAM_ELK_OVTVEHLEFT_TTC : 55|16@0+ (1,0) [0|65535] ""  CVC_I,MHU
 SG_ FCAM_ELK_OVTVEHRIGHT_TTC : 167|16@0+ (1,0) [0|65535] ""  CVC_I,MHU
 SG_ FCAM_LKA_LATDIS_LEFT : 143|8@0+ (0.1,-12.7) [-12.7|12.8] ""  CVC_I,MHU
 SG_ FCAM_LKA_LATDIS_RIGHT : 119|8@0+ (0.1,-12.7) [-12.7|12.8] ""  CVC_I,MHU
 SG_ FCAM_LKA_LATVEL_LEFT : 87|16@0+ (1,-32768) [-32768|32767] ""  CVC_I,MHU
 SG_ FCAM_LKA_LATVEL_RIGHT : 39|16@0+ (1,-32768) [-32768|32767] ""  CVC_I,MHU
 SG_ FCAM_ALCA_REAROBJLEFT_TTC : 183|16@0+ (1,0) [0|65535] ""  CVC_I,MHU
 SG_ FCAM_ALCA_REAROBJRIGHT_TTC : 151|16@0+ (1,0) [0|65535] ""  CVC_I,MHU
 SG_ FCAM_LATERACC_Filtered : 127|16@0+ (0.002,-65.532) [-65.532|65.532] ""  CVC_I,MHU
 SG_ FCAM_ADAS_HOD : 23|8@0+ (1,0) [0|7] ""  CVC_I,MHU

BO_ 528 FCAM_NOP_Status: 8 FCAM_I
 SG_ CRC_FCAM_NOP_Status : 7|8@0+ (1,0) [0|255] ""  CVC_I,MHU,ADCU_I
 SG_ ALIVE_FCAM_NOP_Status : 11|4@0+ (1,0) [0|15] ""  CVC_I,MHU,ADCU_I
 SG_ FCAM_NOP_check : 17|2@0+ (1,0) [0|3] ""  CVC_I,MHU,ADCU_I
 SG_ FCAM_NOP_state : 23|4@0+ (1,0) [0|15] ""  CVC_I,MHU,ADCU_I
 SG_ FCAM_NOP_ICON_Feed : 47|3@0+ (1,0) [0|7] ""  CVC_I,MHU,ADCU_I
 SG_ FCAM_NOP_txtpopup : 28|5@0+ (1,0) [0|31] ""  CVC_I,MHU,ADCU_I
 SG_ FCAM_NOP_Warning : 31|2@0+ (1,0) [0|3] ""  CVC_I,MHU,ADCU_I
 SG_ FCAM_NOP_AAESA_state : 34|3@0+ (1,0) [0|7] ""  CVC_I,MHU,ADCU_I
 SG_ FCAM_NOP_TOR : 37|3@0+ (1,0) [0|7] ""  CVC_I,MHU,ADCU_I
 SG_ FCAM_eyesoff_Warning_Mode_2 : 42|3@0+ (1,0) [0|7] ""  CVC_I,MHU,ADCU_I
 SG_ FCAM_EOD : 43|1@0+ (1,0) [0|1] ""  CVC_I,MHU,ADCU_I
 SG_ FCAM_NOP_Mode_Feed : 19|2@0+ (1,0) [0|3] ""  CVC_I,MHU,ADCU_I
 SG_ FCAM_NOP_Type_Feed : 39|2@0+ (1,0) [0|3] ""  CVC_I,MHU,ADCU_I

BO_ 540 FCAM_AEB_FCW: 12 FCAM_I
 SG_ CRC_FCAM_AEB_FCW : 7|8@0+ (1,0) [0|255] ""  CVC_I,MHU,ADCU_I
 SG_ ALIVE_FCAM_AEB_FCW : 11|4@0+ (1,0) [0|15] ""  CVC_I,MHU,ADCU_I
 SG_ FCAM_AEB_Warning : 13|2@0+ (1,0) [0|3] ""  CVC_I,MHU,ADCU_I
 SG_ FCAM_AEB_State : 16|3@0+ (1,0) [0|7] ""  CVC_I,MHU,ADCU_I
 SG_ FCAM_AEB_Mode_Feed : 23|2@0+ (1,0) [0|3] ""  CVC_I,MHU,ADCU_I
 SG_ FCAM_AEB_check : 15|2@0+ (1,0) [0|3] ""  CVC_I,MHU,ADCU_I
 SG_ FCAM_FCW_Mode_Feed : 21|1@0+ (1,0) [0|1] ""  CVC_I,MHU,ADCU_I
 SG_ FCAM_FCW_Sens_Feed : 20|2@0+ (1,0) [0|3] ""  CVC_I,MHU,ADCU_I
 SG_ FCAM_FCW_state : 18|2@0+ (1,0) [0|3] ""  CVC_I,MHU,ADCU_I
 SG_ FCAM_FCW_check : 41|2@0+ (1,0) [0|3] ""  CVC_I,MHU,ADCU_I
 SG_ FCAM_FCW_warning : 43|2@0+ (1,0) [0|3] ""  CVC_I,MHU,ADCU_I
 SG_ FCAM_CV_AEB_Alert : 28|1@0+ (1,0) [0|1] ""  CVC_I,MHU,ADCU_I
 SG_ FCAM_CV_FCW_Alert : 27|1@0+ (1,0) [0|1] ""  CVC_I,MHU,ADCU_I
 SG_ FCAM_CV_PartialAEB_Alert : 26|1@0+ (1,0) [0|1] ""  CVC_I,MHU,ADCU_I
 SG_ FCAM_CV_PreFill_Alert : 25|1@0+ (1,0) [0|1] ""  CVC_I,MHU,ADCU_I
 SG_ FCAM_VD_AEB_Alert : 32|1@0+ (1,0) [0|1] ""  CVC_I,MHU,ADCU_I
 SG_ FCAM_VD_DBS_Alert : 33|1@0+ (1,0) [0|1] ""  CVC_I,MHU,ADCU_I
 SG_ FCAM_VD_EGOTAP_AEB_Alert : 34|1@0+ (1,0) [0|1] ""  CVC_I,MHU,ADCU_I
 SG_ FCAM_VD_FCW_Alert : 35|1@0+ (1,0) [0|1] ""  CVC_I,MHU,ADCU_I
 SG_ FCAM_VD_HeadOn_AEB_Alert : 36|1@0+ (1,0) [0|1] ""  CVC_I,MHU,ADCU_I
 SG_ FCAM_VD_PartialAEB_Alert : 37|1@0+ (1,0) [0|1] ""  CVC_I,MHU,ADCU_I
 SG_ FCAM_VD_Prefill_Alert : 38|1@0+ (1,0) [0|1] ""  CVC_I,MHU,ADCU_I
 SG_ FCAM_VRU_AEB_Alert : 24|1@0+ (1,0) [0|1] ""  CVC_I,MHU,ADCU_I
 SG_ FCAM_VRU_FCW_Alert : 39|1@0+ (1,0) [0|1] ""  CVC_I,MHU,ADCU_I
 SG_ FCAM_VRU_PreFill_Alert : 29|1@0+ (1,0) [0|1] ""  CVC_I,MHU,ADCU_I
 SG_ FCAM_Fusion_TTC : 55|16@0+ (1,0) [0|65535] "ms"  CVC_I,MHU,ADCU_I
 SG_ FCAM_AB_TTC : 71|16@0+ (1,0) [0|65535] "ms"  CVC_I,MHU,ADCU_I
 SG_ FCAM_AEB_Trigger_Source : 45|2@0+ (1,0) [0|3] ""  CVC_I,MHU,ADCU_I
 SG_ FCAM_FCW_Trigger_Source : 47|2@0+ (1,0) [0|3] ""  CVC_I,MHU,ADCU_I
 SG_ FCAM_AEB_BrakeReq_Source : 87|3@0+ (1,0) [0|7] ""  CVC_I,MHU,ADCU_I

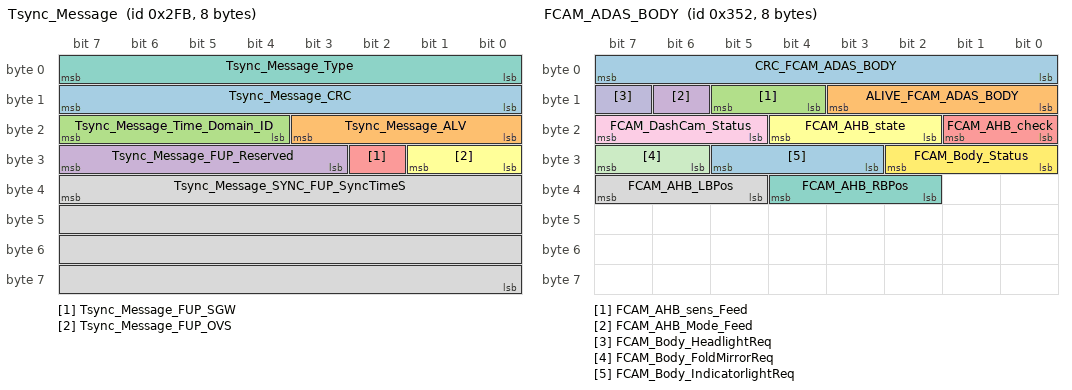
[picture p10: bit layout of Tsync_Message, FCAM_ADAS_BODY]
BO_ 763 Tsync_Message: 8 FCAM_I
 SG_ Tsync_Message_CRC : 15|8@0+ (1,0) [0|255] ""  MRR,SRR_RL,SRR_RR,SRR_FL,SRR_FR,ADCU_I
 SG_ Tsync_Message_ALV : 19|4@0+ (1,0) [0|15] ""  MRR,SRR_RL,SRR_RR,SRR_FL,SRR_FR,ADCU_I
 SG_ Tsync_Message_Time_Domain_ID : 23|4@0+ (1,0) [0|15] ""  MRR,SRR_RL,SRR_RR,SRR_FL,SRR_FR,ADCU_I
 SG_ Tsync_Message_FUP_Reserved : 31|5@0+ (1,0) [0|32] ""  MRR,SRR_RL,SRR_RR,SRR_FL,SRR_FR,ADCU_I
 SG_ Tsync_Message_FUP_SGW : 26|1@0+ (1,0) [0|1] ""  MRR,SRR_RL,SRR_RR,SRR_FL,SRR_FR,ADCU_I
 SG_ Tsync_Message_FUP_OVS : 25|2@0+ (1,0) [0|3] ""  MRR,SRR_RL,SRR_RR,SRR_FL,SRR_FR,ADCU_I
 SG_ Tsync_Message_Type : 7|8@0+ (1,0) [0|255] ""  MRR,SRR_RL,SRR_RR,SRR_FL,SRR_FR,ADCU_I
 SG_ Tsync_Message_SYNC_FUP_SyncTimeS : 39|32@0+ (1,0) [0|4290000000] "s"  MRR,SRR_RL,SRR_RR,SRR_FL,SRR_FR,ADCU_I

BO_ 833 FCAM_Camera_Perception: 64 FCAM_I
 SG_ CRC_FCAM_Camera_Perception : 7|8@0+ (1,0) [0|255] ""  MHU
 SG_ ALIVE_FCAM_Camera_Perception : 11|4@0+ (1,0) [0|15] ""  MHU
 SG_ FCAM_OBJ01_Class : 23|4@0+ (1,0) [0|12] ""  MHU
 SG_ FCAM_OBJ01_LgtDis : 107|14@0+ (0.025,-10) [-10|399.575] ""  MHU
 SG_ FCAM_OBJ01_ID : 199|8@0+ (1,0) [0|255] ""  MHU
 SG_ FCAM_OBJ01_LatDis : 55|10@0+ (0.0293,-15.0146) [-15.0146|14.9593] ""  MHU
 SG_ FCAM_OBJ01_ClosestSurface : 390|3@0+ (1,0) [0|7] ""  MHU
 SG_ FCAM_OBJ02_Class : 19|4@0+ (1,0) [0|12] ""  MHU
 SG_ FCAM_OBJ02_LgtDis : 125|14@0+ (0.025,-10) [-10|399.575] ""  MHU
 SG_ FCAM_OBJ02_ID : 207|8@0+ (1,0) [0|255] ""  MHU
 SG_ FCAM_OBJ02_LatDis : 61|10@0+ (0.0293,-15.0146) [-15.0146|14.9593] ""  MHU
 SG_ FCAM_OBJ02_ClosestSurface : 387|3@0+ (1,0) [0|7] ""  MHU
 SG_ FCAM_OBJ03_Class : 31|4@0+ (1,0) [0|12] ""  MHU
 SG_ FCAM_OBJ03_LgtDis : 143|14@0+ (0.025,-10) [-10|399.575] ""  MHU
 SG_ FCAM_OBJ03_ID : 215|8@0+ (1,0) [0|255] ""  MHU
 SG_ FCAM_OBJ03_LatDis : 67|10@0+ (0.0293,-15.0146) [-15.0146|14.9593] ""  MHU
 SG_ FCAM_OBJ03_ClosestSurface : 384|3@0+ (1,0) [0|7] ""  MHU
 SG_ FCAM_OBJ04_Class : 35|4@0+ (1,0) [0|12] ""  MHU
 SG_ FCAM_OBJ04_LgtDis : 145|14@0+ (0.025,-10) [-10|399.575] ""  MHU
 SG_ FCAM_OBJ04_ID : 223|8@0+ (1,0) [0|255] ""  MHU
 SG_ FCAM_OBJ04_LatDis : 73|10@0+ (0.0293,-15.0146) [-15.0146|14.9593] ""  MHU
 SG_ FCAM_OBJ04_ClosestSurface : 397|3@0+ (1,0) [0|7] ""  MHU
 SG_ FCAM_OBJ05_Class : 27|4@0+ (1,0) [0|12] ""  MHU
 SG_ FCAM_OBJ05_LgtDis : 163|14@0+ (0.025,-10) [-10|399.575] ""  MHU
 SG_ FCAM_OBJ05_ID : 231|8@0+ (1,0) [0|255] ""  MHU
 SG_ FCAM_OBJ05_LatDis : 95|10@0+ (0.0293,-15.0146) [-15.0146|14.9593] ""  MHU
 SG_ FCAM_OBJ05_ClosestSurface : 394|3@0+ (1,0) [0|7] ""  MHU
 SG_ FCAM_OBJ06_Class : 39|4@0+ (1,0) [0|12] ""  MHU
 SG_ FCAM_OBJ06_LgtDis : 181|14@0+ (0.025,-10) [-10|399.575] ""  MHU
 SG_ FCAM_OBJ06_ID : 239|8@0+ (1,0) [0|255] ""  MHU
 SG_ FCAM_OBJ06_LatDis : 101|10@0+ (0.0293,-15.0146) [-15.0146|14.9593] ""  MHU
 SG_ FCAM_OBJ05_ExistProbability : 381|4@0+ (0.1,0) [0|1] ""  MHU
 SG_ FCAM_OBJ05_TurnSignal : 383|2@0+ (1,0) [0|3] ""  MHU
 SG_ FCAM_OBJ05_Heading : 362|11@0+ (0.001,-1) [-1|1] "rad"  MHU
 SG_ FCAM_OBJ05_BrakeLight : 363|1@0+ (1,0) [0|1] ""  MHU
 SG_ FCAM_OBJ06_ExistProbability : 367|4@0+ (0.1,0) [0|1] ""  MHU
 SG_ FCAM_OBJ06_TurnSignal : 353|2@0+ (1,0) [0|3] ""  MHU
 SG_ FCAM_OBJ06_Heading : 348|11@0+ (0.001,-1) [-1|1] "rad"  MHU
 SG_ FCAM_OBJ06_BrakeLight : 349|1@0+ (1,0) [0|1] ""  MHU
 SG_ FCAM_OBJ06_ClosestSurface : 407|3@0+ (1,0) [0|7] ""  MHU
 SG_ FCAM_OBJ07_Class : 47|4@0+ (1,0) [0|12] ""  MHU
 SG_ FCAM_OBJ07_LgtDis : 332|14@0+ (0.025,-30) [-30|370] "m"  MHU
 SG_ FCAM_OBJ07_ID : 247|8@0+ (1,0) [0|255] ""  MHU
 SG_ FCAM_OBJ07_LatDis : 313|13@0+ (0.025,-100) [-100|100] "m"  MHU
 SG_ FCAM_OBJ07_ExistProbability : 317|4@0+ (0.1,0) [0|1] ""  MHU
 SG_ FCAM_OBJ07_TurnSignal : 319|2@0+ (1,0) [0|3] ""  MHU
 SG_ FCAM_OBJ07_Heading : 298|11@0+ (0.001,-1) [-1|1] "rad"  MHU
 SG_ FCAM_OBJ07_BrakeLight : 299|1@0+ (1,0) [0|1] ""  MHU
 SG_ FCAM_OBJ07_ClosestSurface : 404|3@0+ (1,0) [0|7] ""  MHU
 SG_ FCAM_OBJ08_ClosestSurface : 377|3@0+ (1,0) [0|7] ""  MHU
 SG_ FCAM_OBJ08_Class : 43|4@0+ (1,0) [0|12] ""  MHU
 SG_ FCAM_OBJ08_LgtDis : 281|14@0+ (0.025,-30) [-30|370] "m"  MHU
 SG_ FCAM_OBJ08_ID : 255|8@0+ (1,0) [0|255] ""  MHU
 SG_ FCAM_OBJ08_LatDis : 278|13@0+ (0.025,-100) [-100|100] "m"  MHU
 SG_ FCAM_OBJ08_ExistProbability : 266|4@0+ (0.1,0) [0|1] ""  MHU
 SG_ FCAM_OBJ08_TurnSignal : 268|2@0+ (1,0) [0|3] ""  MHU
 SG_ FCAM_OBJ08_Heading : 263|11@0+ (0.001,-1) [-1|1] "rad"  MHU
 SG_ FCAM_OBJ08_BrakeLight : 350|1@0+ (1,0) [0|1] ""  MHU

BO_ 834 FCAM_Camera_Perception_1: 64 FCAM_I
 SG_ CRC_FCAM_Camera_Perception_1 : 7|8@0+ (1,0) [0|255] ""  MHU
 SG_ ALIVE_FCAM_Camera_Perception_1 : 11|4@0+ (1,0) [0|15] ""  MHU
 SG_ FCAM_StopLine0_Start_Lgt : 39|13@0+ (0.01,-10) [-10|70] "m"  MHU
 SG_ FCAM_StopLine0_Start_Lat : 42|13@0+ (0.01,-10) [-10|70] "m"  MHU
 SG_ FCAM_StopLine0_End_Lgt : 61|13@0+ (0.01,-10) [-10|70] "m"  MHU
 SG_ FCAM_StopLine0_End_Lat : 64|13@0+ (0.01,-10) [-10|70] "m"  MHU
 SG_ FCAM_PedCross0_Start_Lgt : 83|13@0+ (0.01,-10) [-10|70] "m"  MHU
 SG_ FCAM_PedCross0_Start_Lat : 102|13@0+ (0.01,-10) [-10|70] "m"  MHU
 SG_ FCAM_PedCross0_End_Lgt : 105|13@0+ (0.01,-10) [-10|70] "m"  MHU
 SG_ FCAM_PedCross0_End_Lat : 124|13@0+ (0.01,-10) [-10|70] "m"  MHU
 SG_ FCAM_PedCross1_Start_Lgt : 143|13@0+ (0.01,-10) [-10|70] "m"  MHU
 SG_ FCAM_PedCross1_Start_Lat : 146|13@0+ (0.01,-10) [-10|70] "m"  MHU
 SG_ FCAM_PedCross1_End_Lgt : 165|13@0+ (0.01,-10) [-10|70] "m"  MHU
 SG_ FCAM_PedCross1_End_Lat : 168|13@0+ (0.01,-10) [-10|70] "m"  MHU
 SG_ FCAM_Ego_Lane_Width : 187|9@0+ (0.01,0) [0|5] "m"  MHU
 SG_ FCAM_Ego_Lane_RadiusCurvature : 23|16@0+ (1,-32768) [-32768|32767] "m"  MHU
 SG_ FCAM_Ego_Lane_Status : 487|4@0+ (0.1,0) [0|1] ""  MHU
 SG_ FCAM_R0_Line_C0 : 194|11@0+ (0.01,-10) [-10|10] "m"  MHU
 SG_ FCAM_R0_Line_C1 : 215|11@0+ (0.001,-1) [-1|1] "rad"  MHU
 SG_ FCAM_R0_Line_C2 : 220|16@0+ (0.001,-32) [-32|32] "mm"  MHU
 SG_ FCAM_R0_Line_C3 : 236|17@0+ (0.005,-250) [-250|250] "mm^2"  MHU
 SG_ FCAM_R0_Line_Start_Lgt : 251|16@0+ (0.025,-30) [-30|370] "m"  MHU
 SG_ FCAM_R0_Line_End_Lgt : 267|14@0+ (0.025,-30) [-30|370] "m"  MHU
 SG_ FCAM_R0_Line_ExistProbability : 495|4@0+ (0.1,0) [0|1] ""  MHU
 SG_ FCAM_R0_Line_Class : 491|4@0+ (1,0) [0|15] ""  MHU
 SG_ FCAM_R1_Line_C0 : 285|11@0+ (0.01,-10) [-10|10] "m"  MHU
 SG_ FCAM_R1_Line_C1 : 290|11@0+ (0.001,-1) [-1|1] "rad"  MHU
 SG_ FCAM_R1_Line_C2 : 311|16@0+ (0.001,-32) [-32|32] "mm"  MHU
 SG_ FCAM_R1_Line_C3 : 327|17@0+ (0.005,-250) [-250|250] "mm^2"  MHU
 SG_ FCAM_R1_Line_Start_Lgt : 342|16@0+ (0.025,-30) [-30|370] "m"  MHU
 SG_ FCAM_R1_Line_End_Lgt : 358|14@0+ (0.025,-30) [-30|370] "m"  MHU
 SG_ FCAM_R1_Line_ExistProbability : 503|4@0+ (0.1,0) [0|1] ""  MHU
 SG_ FCAM_R1_Line_Class : 499|4@0+ (1,0) [0|15] ""  MHU
 SG_ FCAM_R2_Line_C0 : 360|11@0+ (0.01,-10) [-10|10] "m"  MHU
 SG_ FCAM_R2_Line_C1 : 381|11@0+ (0.001,-1) [-1|1] "rad"  MHU
 SG_ FCAM_R2_Line_C2 : 386|16@0+ (0.001,-32) [-32|32] "mm"  MHU
 SG_ FCAM_R2_Line_C3 : 402|17@0+ (0.005,-250) [-250|250] "mm^2"  MHU
 SG_ FCAM_R2_Line_Start_Lgt : 417|16@0+ (0.025,-30) [-30|370] "m"  MHU
 SG_ FCAM_R2_Line_End_Lgt : 433|14@0+ (0.025,-30) [-30|370] "m"  MHU
 SG_ FCAM_R2_Line_ExistProbability : 511|4@0+ (0.1,0) [0|1] ""  MHU
 SG_ FCAM_R2_Line_Class : 507|4@0+ (1,0) [0|15] ""  MHU
 SG_ FCAM_LA_veh_pos_right : 463|8@0+ (0.1,-12.8) [-12.8|12.7] "m"  MHU
 SG_ FCAM_LA_veh_pos_left : 471|8@0+ (0.1,-12.8) [-12.8|12.7] "m"  MHU

BO_ 835 FCAM_Camera_Perception_2: 64 FCAM_I
 SG_ CRC_FCAM_Camera_Perception_2 : 7|8@0+ (1,0) [0|255] ""  MHU
 SG_ ALIVE_FCAM_Camera_Perception_2 : 11|4@0+ (1,0) [0|15] ""  MHU
 SG_ FCAM_L0_Line_C0 : 31|11@0+ (0.01,-10) [-10|10] "m"  MHU
 SG_ FCAM_L0_Line_C1 : 36|11@0+ (0.001,-1) [-1|1] "rad"  MHU
 SG_ FCAM_L0_Line_C2 : 41|16@0+ (0.001,-32) [-32|32] "mm"  MHU
 SG_ FCAM_L0_Line_C3 : 57|17@0+ (0.005,-250) [-250|250] "mm^2"  MHU
 SG_ FCAM_L0_Line_Start_Lgt : 72|14@0+ (0.025,-30) [-30|370] "m"  MHU
 SG_ FCAM_L0_Line_End_Lgt : 90|14@0+ (0.025,-30) [-30|370] "m"  MHU
 SG_ FCAM_L0_Line_ExistProbability : 134|4@0+ (0.1,0) [0|1] ""  MHU
 SG_ FCAM_L0_Line_Class : 130|4@0+ (1,0) [0|15] ""  MHU
 SG_ FCAM_L1_Line_C0 : 108|11@0+ (0.01,-10) [-10|10] "m"  MHU
 SG_ FCAM_L1_Line_C1 : 113|11@0+ (0.001,-1) [-1|1] "rad"  MHU
 SG_ FCAM_L1_Line_C2 : 142|16@0+ (0.001,-32) [-32|32] "mm"  MHU
 SG_ FCAM_L1_Line_C3 : 158|17@0+ (0.005,-250) [-250|250] "mm^2"  MHU
 SG_ FCAM_L1_Line_Start_Lgt : 173|14@0+ (0.025,-30) [-30|370] "m"  MHU
 SG_ FCAM_L1_Line_End_Lgt : 191|14@0+ (0.025,-30) [-30|370] "m"  MHU
 SG_ FCAM_L1_Line_ExistProbability : 193|4@0+ (0.1,0) [0|1] ""  MHU
 SG_ FCAM_L1_Line_Class : 205|4@0+ (1,0) [0|15] ""  MHU
 SG_ FCAM_L2_Line_C0 : 201|11@0+ (0.01,-10) [-10|10] "m"  MHU
 SG_ FCAM_L2_Line_C1 : 222|11@0+ (0.001,-1) [-1|1] "rad"  MHU
 SG_ FCAM_L2_Line_C2 : 227|16@0+ (0.001,-32) [-32|32] "mm"  MHU
 SG_ FCAM_L2_Line_C3 : 243|17@0+ (0.005,-250) [-250|250] "mm^2"  MHU
 SG_ FCAM_L2_Line_Start_Lgt : 258|14@0+ (0.025,-30) [-30|370] "m"  MHU
 SG_ FCAM_L2_Line_End_Lgt : 276|14@0+ (0.025,-30) [-30|370] "m"  MHU
 SG_ FCAM_L2_Line_ExistProbability : 19|4@0+ (0.1,0) [0|1] ""  MHU
 SG_ FCAM_L2_Line_Class : 23|4@0+ (1,0) [0|15] ""  MHU
 SG_ FCAM_OBJ01_ExistProbability : 354|4@0+ (0.1,0) [0|1] ""  MHU
 SG_ FCAM_OBJ01_TurnSignal : 336|2@0+ (1,0) [0|3] ""  MHU
 SG_ FCAM_OBJ01_Heading : 350|11@0+ (0.001,-1) [-1|1] "rad"  MHU
 SG_ FCAM_OBJ01_BrakeLight : 355|1@0+ (1,0) [0|1] ""  MHU
 SG_ FCAM_OBJ02_ExistProbability : 340|4@0+ (0.1,0) [0|1] ""  MHU
 SG_ FCAM_OBJ02_TurnSignal : 342|2@0+ (1,0) [0|3] ""  MHU
 SG_ FCAM_OBJ02_Heading : 321|11@0+ (0.001,-1) [-1|1] "rad"  MHU
 SG_ FCAM_OBJ02_BrakeLight : 322|1@0+ (1,0) [0|1] ""  MHU
 SG_ FCAM_OBJ03_ExistProbability : 312|4@0+ (0.1,0) [0|1] ""  MHU
 SG_ FCAM_OBJ03_TurnSignal : 324|2@0+ (1,0) [0|3] ""  MHU
 SG_ FCAM_OBJ03_Heading : 308|11@0+ (0.001,-1) [-1|1] "rad"  MHU
 SG_ FCAM_OBJ03_BrakeLight : 313|1@0+ (1,0) [0|1] ""  MHU
 SG_ FCAM_OBJ04_ExistProbability : 296|4@0+ (0.1,0) [0|1] ""  MHU
 SG_ FCAM_OBJ04_TurnSignal : 293|2@0+ (1,0) [0|3] ""  MHU
 SG_ FCAM_OBJ04_Heading : 291|11@0+ (0.001,-1) [-1|1] "rad"  MHU
 SG_ FCAM_OBJ04_BrakeLight : 294|1@0+ (1,0) [0|1] ""  MHU

BO_ 836 FCAM_Camera_Perception_3: 64 FCAM_I
 SG_ CRC_FCAM_Camera_Perception_3 : 7|8@0+ (1,0) [0|255] ""  MHU
 SG_ ALIVE_FCAM_Camera_Perception_3 : 11|4@0+ (1,0) [0|15] ""  MHU
 SG_ FCAM_OBJ09_Class : 225|4@0+ (1,0) [0|12] ""  MHU
 SG_ FCAM_OBJ09_LgtDis : 501|14@0+ (0.025,-30) [-30|370] "m"  MHU
 SG_ FCAM_OBJ09_ID : 451|8@0+ (1,0) [0|255] ""  MHU
 SG_ FCAM_OBJ09_ClosestSurface : 219|3@0+ (1,0) [0|7] ""  MHU
 SG_ FCAM_OBJ09_LatDis : 482|13@0+ (0.025,-100) [-100|100] "m"  MHU
 SG_ FCAM_OBJ09_ExistProbability : 216|4@0+ (0.1,0) [0|1] ""  MHU
 SG_ FCAM_OBJ09_TurnSignal : 228|2@0+ (1,0) [0|3] ""  MHU
 SG_ FCAM_OBJ09_Heading : 459|11@0+ (0.001,-1) [-1|1] "rad"  MHU
 SG_ FCAM_OBJ09_BrakeLight : 226|1@0+ (1,0) [0|1] ""  MHU
 SG_ FCAM_OBJ10_Class : 215|4@0+ (1,0) [0|12] ""  MHU
 SG_ FCAM_OBJ10_LgtDis : 464|14@0+ (0.025,-30) [-30|370] "m"  MHU
 SG_ FCAM_OBJ10_ID : 443|8@0+ (1,0) [0|255] ""  MHU
 SG_ FCAM_OBJ10_ClosestSurface : 222|3@0+ (1,0) [0|7] ""  MHU
 SG_ FCAM_OBJ10_LatDis : 424|13@0+ (0.025,-100) [-100|100] "m"  MHU
 SG_ FCAM_OBJ10_ExistProbability : 203|4@0+ (0.1,0) [0|1] ""  MHU
 SG_ FCAM_OBJ10_TurnSignal : 211|2@0+ (1,0) [0|3] ""  MHU
 SG_ FCAM_OBJ10_Heading : 419|11@0+ (0.001,-1) [-1|1] "rad"  MHU
 SG_ FCAM_OBJ10_BrakeLight : 223|1@0+ (1,0) [0|1] ""  MHU
 SG_ FCAM_OBJ11_Class : 207|4@0+ (1,0) [0|12] ""  MHU
 SG_ FCAM_OBJ11_LgtDis : 401|14@0+ (0.025,-30) [-30|370] "m"  MHU
 SG_ FCAM_OBJ11_ID : 393|8@0+ (1,0) [0|255] ""  MHU
 SG_ FCAM_OBJ11_ClosestSurface : 191|3@0+ (1,0) [0|7] ""  MHU
 SG_ FCAM_OBJ11_LatDis : 390|13@0+ (0.025,-100) [-100|100] "m"  MHU
 SG_ FCAM_OBJ11_ExistProbability : 199|4@0+ (0.1,0) [0|1] ""  MHU
 SG_ FCAM_OBJ11_TurnSignal : 188|2@0+ (1,0) [0|3] ""  MHU
 SG_ FCAM_OBJ11_Heading : 369|11@0+ (0.001,-1) [-1|1] "rad"  MHU
 SG_ FCAM_OBJ11_BrakeLight : 209|1@0+ (1,0) [0|1] ""  MHU
 SG_ FCAM_OBJ12_Class : 183|4@0+ (1,0) [0|12] ""  MHU
 SG_ FCAM_OBJ12_LgtDis : 367|14@0+ (0.025,-30) [-30|370] "m"  MHU
 SG_ FCAM_OBJ12_ID : 359|8@0+ (1,0) [0|255] ""  MHU
 SG_ FCAM_OBJ12_ClosestSurface : 186|3@0+ (1,0) [0|7] ""  MHU
 SG_ FCAM_OBJ12_LatDis : 340|13@0+ (0.025,-100) [-100|100] "m"  MHU
 SG_ FCAM_OBJ12_ExistProbability : 195|4@0+ (0.1,0) [0|1] ""  MHU
 SG_ FCAM_OBJ12_TurnSignal : 242|2@0+ (1,0) [0|3] ""  MHU
 SG_ FCAM_OBJ12_Heading : 335|11@0+ (0.001,-1) [-1|1] "rad"  MHU
 SG_ FCAM_OBJ12_BrakeLight : 208|1@0+ (1,0) [0|1] ""  MHU
 SG_ FCAM_OBJ13_Class : 179|4@0+ (1,0) [0|12] ""  MHU
 SG_ FCAM_OBJ13_LgtDis : 317|14@0+ (0.025,-30) [-30|370] "m"  MHU
 SG_ FCAM_OBJ13_ID : 291|8@0+ (1,0) [0|255] ""  MHU
 SG_ FCAM_OBJ13_ClosestSurface : 172|3@0+ (1,0) [0|7] ""  MHU
 SG_ FCAM_OBJ13_LatDis : 272|13@0+ (0.025,-100) [-100|100] "m"  MHU
 SG_ FCAM_OBJ13_ExistProbability : 167|4@0+ (0.1,0) [0|1] ""  MHU
 SG_ FCAM_OBJ13_TurnSignal : 169|2@0+ (1,0) [0|3] ""  MHU
 SG_ FCAM_OBJ13_Heading : 267|11@0+ (0.001,-1) [-1|1] "rad"  MHU
 SG_ FCAM_OBJ13_BrakeLight : 152|1@0+ (1,0) [0|1] ""  MHU
 SG_ FCAM_OBJ14_Class : 163|4@0+ (1,0) [0|12] ""  MHU
 SG_ FCAM_OBJ14_LgtDis : 299|14@0+ (0.025,-30) [-30|370] "m"  MHU
 SG_ FCAM_OBJ14_ID : 259|8@0+ (1,0) [0|255] ""  MHU
 SG_ FCAM_OBJ14_ClosestSurface : 175|3@0+ (1,0) [0|7] ""  MHU
 SG_ FCAM_OBJ14_LatDis : 240|13@0+ (0.025,-100) [-100|100] "m"  MHU
 SG_ FCAM_OBJ14_ExistProbability : 159|4@0+ (0.1,0) [0|1] ""  MHU
 SG_ FCAM_OBJ14_TurnSignal : 155|2@0+ (1,0) [0|3] ""  MHU
 SG_ FCAM_OBJ14_Heading : 237|11@0+ (0.001,-1) [-1|1] "rad"  MHU
 SG_ FCAM_OBJ14_BrakeLight : 153|1@0+ (1,0) [0|1] ""  MHU

BO_ 837 FCAM_Camera_Perception_4: 64 FCAM_I
 SG_ CRC_FCAM_Camera_Perception_4 : 7|8@0+ (1,0) [0|255] ""  MHU
 SG_ ALIVE_FCAM_Camera_Perception_4 : 11|4@0+ (1,0) [0|15] ""  MHU
 SG_ FCAM_OBJ15_Class : 199|4@0+ (1,0) [0|12] ""  MHU
 SG_ FCAM_OBJ15_LgtDis : 501|14@0+ (0.025,-30) [-30|370] "m"  MHU
 SG_ FCAM_OBJ15_ID : 443|8@0+ (1,0) [0|255] ""  MHU
 SG_ FCAM_OBJ15_ClosestSurface : 188|3@0+ (1,0) [0|7] ""  MHU
 SG_ FCAM_OBJ15_LatDis : 482|13@0+ (0.025,-100) [-100|100] "m"  MHU
 SG_ FCAM_OBJ15_ExistProbability : 195|4@0+ (0.1,0) [0|1] ""  MHU
 SG_ FCAM_OBJ15_TurnSignal : 185|2@0+ (1,0) [0|3] ""  MHU
 SG_ FCAM_OBJ15_Heading : 459|11@0+ (0.001,-1) [-1|1] "rad"  MHU
 SG_ FCAM_OBJ15_BrakeLight : 207|1@0+ (1,0) [0|1] ""  MHU
 SG_ FCAM_OBJ16_Class : 175|4@0+ (1,0) [0|12] ""  MHU
 SG_ FCAM_OBJ16_LgtDis : 464|14@0+ (0.025,-30) [-30|370] "m"  MHU
 SG_ FCAM_OBJ16_ID : 451|8@0+ (1,0) [0|255] ""  MHU
 SG_ FCAM_OBJ16_ClosestSurface : 164|3@0+ (1,0) [0|7] ""  MHU
 SG_ FCAM_OBJ16_LatDis : 424|13@0+ (0.025,-100) [-100|100] "m"  MHU
 SG_ FCAM_OBJ16_ExistProbability : 183|4@0+ (0.1,0) [0|1] ""  MHU
 SG_ FCAM_OBJ16_TurnSignal : 161|2@0+ (1,0) [0|3] ""  MHU
 SG_ FCAM_OBJ16_Heading : 419|11@0+ (0.001,-1) [-1|1] "rad"  MHU
 SG_ FCAM_OBJ16_BrakeLight : 271|1@0+ (1,0) [0|1] ""  MHU
 SG_ FCAM_OBJ17_Class : 179|4@0+ (1,0) [0|12] ""  MHU
 SG_ FCAM_OBJ17_LgtDis : 401|14@0+ (0.025,-30) [-30|370] "m"  MHU
 SG_ FCAM_OBJ17_ID : 393|8@0+ (1,0) [0|255] ""  MHU
 SG_ FCAM_OBJ17_ClosestSurface : 167|3@0+ (1,0) [0|7] ""  MHU
 SG_ FCAM_OBJ17_LatDis : 390|13@0+ (0.025,-100) [-100|100] "m"  MHU
 SG_ FCAM_OBJ17_ExistProbability : 171|4@0+ (0.1,0) [0|1] ""  MHU
 SG_ FCAM_OBJ17_TurnSignal : 190|2@0+ (1,0) [0|3] ""  MHU
 SG_ FCAM_OBJ17_Heading : 369|11@0+ (0.001,-1) [-1|1] "rad"  MHU
 SG_ FCAM_OBJ17_BrakeLight : 191|1@0+ (1,0) [0|1] ""  MHU
 SG_ FCAM_OBJ18_Class : 323|4@0+ (1,0) [0|12] ""  MHU
 SG_ FCAM_OBJ18_LgtDis : 367|14@0+ (0.025,-30) [-30|370] "m"  MHU
 SG_ FCAM_OBJ18_ID : 359|8@0+ (1,0) [0|255] ""  MHU
 SG_ FCAM_OBJ18_ClosestSurface : 247|3@0+ (1,0) [0|7] ""  MHU
 SG_ FCAM_OBJ18_LatDis : 340|13@0+ (0.025,-100) [-100|100] "m"  MHU
 SG_ FCAM_OBJ18_ExistProbability : 327|4@0+ (0.1,0) [0|1] ""  MHU
 SG_ FCAM_OBJ18_TurnSignal : 244|2@0+ (1,0) [0|3] ""  MHU
 SG_ FCAM_OBJ18_Heading : 335|11@0+ (0.001,-1) [-1|1] "rad"  MHU
 SG_ FCAM_OBJ18_BrakeLight : 256|1@0+ (1,0) [0|1] ""  MHU
 SG_ FCAM_OBJ19_Class : 268|4@0+ (1,0) [0|12] ""  MHU
 SG_ FCAM_OBJ19_LgtDis : 309|14@0+ (0.025,-30) [-30|370] "m"  MHU
 SG_ FCAM_OBJ19_ID : 283|8@0+ (1,0) [0|255] ""  MHU
 SG_ FCAM_OBJ19_ClosestSurface : 223|3@0+ (1,0) [0|7] ""  MHU
 SG_ FCAM_OBJ19_LatDis : 264|13@0+ (0.025,-100) [-100|100] "m"  MHU
 SG_ FCAM_OBJ19_ExistProbability : 211|4@0+ (0.1,0) [0|1] ""  MHU
 SG_ FCAM_OBJ19_TurnSignal : 270|2@0+ (1,0) [0|3] ""  MHU
 SG_ FCAM_OBJ19_Heading : 242|11@0+ (0.001,-1) [-1|1] "rad"  MHU
 SG_ FCAM_OBJ19_BrakeLight : 257|1@0+ (1,0) [0|1] ""  MHU
 SG_ FCAM_OBJ20_Class : 155|4@0+ (1,0) [0|12] ""  MHU
 SG_ FCAM_OBJ20_LgtDis : 291|14@0+ (0.025,-30) [-30|370] "m"  MHU
 SG_ FCAM_OBJ20_ID : 239|8@0+ (1,0) [0|255] ""  MHU
 SG_ FCAM_OBJ20_ClosestSurface : 262|3@0+ (1,0) [0|7] ""  MHU
 SG_ FCAM_OBJ20_LatDis : 220|13@0+ (0.025,-100) [-100|100] "m"  MHU
 SG_ FCAM_OBJ20_ExistProbability : 159|4@0+ (0.1,0) [0|1] ""  MHU
 SG_ FCAM_OBJ20_TurnSignal : 259|2@0+ (1,0) [0|3] ""  MHU
 SG_ FCAM_OBJ20_Heading : 206|11@0+ (0.001,-1) [-1|1] "rad"  MHU
 SG_ FCAM_OBJ20_BrakeLight : 263|1@0+ (1,0) [0|1] ""  MHU

BO_ 839 FCAM_Camera_Perception_5: 64 FCAM_I
 SG_ CRC_FCAM_Camera_Perception_5 : 7|8@0+ (1,0) [0|255] ""  MHU
 SG_ ALIVE_FCAM_Camera_Perception_5 : 11|4@0+ (1,0) [0|15] ""  MHU
 SG_ FCAM_OBJ21_Class : 239|4@0+ (1,0) [0|12] ""  MHU
 SG_ FCAM_OBJ21_LgtDis : 501|14@0+ (0.025,-30) [-30|370] "m"  MHU
 SG_ FCAM_OBJ21_ID : 451|8@0+ (1,0) [0|255] ""  MHU
 SG_ FCAM_OBJ21_ClosestSurface : 231|3@0+ (1,0) [0|7] ""  MHU
 SG_ FCAM_OBJ21_LatDis : 482|13@0+ (0.025,-100) [-100|100] "m"  MHU
 SG_ FCAM_OBJ21_ExistProbability : 228|4@0+ (0.1,0) [0|1] ""  MHU
 SG_ FCAM_OBJ21_TurnSignal : 217|2@0+ (1,0) [0|3] ""  MHU
 SG_ FCAM_OBJ21_Heading : 459|11@0+ (0.001,-1) [-1|1] "rad"  MHU
 SG_ FCAM_OBJ21_BrakeLight : 168|1@0+ (1,0) [0|1] ""  MHU
 SG_ FCAM_OBJ22_Class : 213|4@0+ (1,0) [0|12] ""  MHU
 SG_ FCAM_OBJ22_LgtDis : 464|14@0+ (0.025,-30) [-30|370] "m"  MHU
 SG_ FCAM_OBJ22_ID : 443|8@0+ (1,0) [0|255] ""  MHU
 SG_ FCAM_OBJ22_ClosestSurface : 223|3@0+ (1,0) [0|7] ""  MHU
 SG_ FCAM_OBJ22_LatDis : 424|13@0+ (0.025,-100) [-100|100] "m"  MHU
 SG_ FCAM_OBJ22_ExistProbability : 207|4@0+ (0.1,0) [0|1] ""  MHU
 SG_ FCAM_OBJ22_TurnSignal : 209|2@0+ (1,0) [0|3] ""  MHU
 SG_ FCAM_OBJ22_Heading : 419|11@0+ (0.001,-1) [-1|1] "rad"  MHU
 SG_ FCAM_OBJ22_BrakeLight : 224|1@0+ (1,0) [0|1] ""  MHU
 SG_ FCAM_OBJ23_Class : 203|4@0+ (1,0) [0|12] ""  MHU
 SG_ FCAM_OBJ23_LgtDis : 401|14@0+ (0.025,-30) [-30|370] "m"  MHU
 SG_ FCAM_OBJ23_ID : 393|8@0+ (1,0) [0|255] ""  MHU
 SG_ FCAM_OBJ23_ClosestSurface : 167|3@0+ (1,0) [0|7] ""  MHU
 SG_ FCAM_OBJ23_LatDis : 390|13@0+ (0.025,-100) [-100|100] "m"  MHU
 SG_ FCAM_OBJ23_ExistProbability : 199|4@0+ (0.1,0) [0|1] ""  MHU
 SG_ FCAM_OBJ23_TurnSignal : 215|2@0+ (1,0) [0|3] ""  MHU
 SG_ FCAM_OBJ23_Heading : 369|11@0+ (0.001,-1) [-1|1] "rad"  MHU
 SG_ FCAM_OBJ23_BrakeLight : 162|1@0+ (1,0) [0|1] ""  MHU
 SG_ FCAM_OBJ24_Class : 191|4@0+ (1,0) [0|12] ""  MHU
 SG_ FCAM_OBJ24_LgtDis : 367|14@0+ (0.025,-30) [-30|370] "m"  MHU
 SG_ FCAM_OBJ24_ID : 359|8@0+ (1,0) [0|255] ""  MHU
 SG_ FCAM_OBJ24_ClosestSurface : 220|3@0+ (1,0) [0|7] ""  MHU
 SG_ FCAM_OBJ24_LatDis : 340|13@0+ (0.025,-100) [-100|100] "m"  MHU
 SG_ FCAM_OBJ24_ExistProbability : 195|4@0+ (0.1,0) [0|1] ""  MHU
 SG_ FCAM_OBJ24_TurnSignal : 161|2@0+ (1,0) [0|3] ""  MHU
 SG_ FCAM_OBJ24_Heading : 335|11@0+ (0.001,-1) [-1|1] "rad"  MHU
 SG_ FCAM_OBJ24_BrakeLight : 163|1@0+ (1,0) [0|1] ""  MHU
 SG_ FCAM_OBJ25_Class : 187|4@0+ (1,0) [0|12] ""  MHU
 SG_ FCAM_OBJ25_LgtDis : 317|14@0+ (0.025,-30) [-30|370] "m"  MHU
 SG_ FCAM_OBJ25_ID : 291|8@0+ (1,0) [0|255] ""  MHU
 SG_ FCAM_OBJ25_ClosestSurface : 159|3@0+ (1,0) [0|7] ""  MHU
 SG_ FCAM_OBJ25_LatDis : 272|13@0+ (0.025,-100) [-100|100] "m"  MHU
 SG_ FCAM_OBJ25_ExistProbability : 183|4@0+ (0.1,0) [0|1] ""  MHU
 SG_ FCAM_OBJ25_TurnSignal : 173|2@0+ (1,0) [0|3] ""  MHU
 SG_ FCAM_OBJ25_Heading : 267|11@0+ (0.001,-1) [-1|1] "rad"  MHU
 SG_ FCAM_OBJ25_BrakeLight : 156|1@0+ (1,0) [0|1] ""  MHU
 SG_ FCAM_OBJ26_Class : 179|4@0+ (1,0) [0|12] ""  MHU
 SG_ FCAM_OBJ26_LgtDis : 299|14@0+ (0.025,-30) [-30|370] "m"  MHU
 SG_ FCAM_OBJ26_ID : 259|8@0+ (1,0) [0|255] ""  MHU
 SG_ FCAM_OBJ26_ClosestSurface : 171|3@0+ (1,0) [0|7] ""  MHU
 SG_ FCAM_OBJ26_LatDis : 240|13@0+ (0.025,-100) [-100|100] "m"  MHU
 SG_ FCAM_OBJ26_ExistProbability : 155|4@0+ (0.1,0) [0|1] ""  MHU
 SG_ FCAM_OBJ26_TurnSignal : 175|2@0+ (1,0) [0|3] ""  MHU
 SG_ FCAM_OBJ26_Heading : 235|11@0+ (0.001,-1) [-1|1] "rad"  MHU
 SG_ FCAM_OBJ26_BrakeLight : 164|1@0+ (1,0) [0|1] ""  MHU

BO_ 840 FCAM_Camera_Perception_6: 64 FCAM_I
 SG_ CRC_FCAM_Camera_Perception_6 : 7|8@0+ (1,0) [0|255] ""  MHU
 SG_ ALIVE_FCAM_Camera_Perception_6 : 11|4@0+ (1,0) [0|15] ""  MHU
 SG_ FCAM_OBJ27_Class : 239|4@0+ (1,0) [0|12] ""  MHU
 SG_ FCAM_OBJ27_LgtDis : 501|14@0+ (0.025,-30) [-30|370] "m"  MHU
 SG_ FCAM_OBJ27_ID : 451|8@0+ (1,0) [0|255] ""  MHU
 SG_ FCAM_OBJ27_ClosestSurface : 210|3@0+ (1,0) [0|7] ""  MHU
 SG_ FCAM_OBJ27_LatDis : 482|13@0+ (0.025,-100) [-100|100] "m"  MHU
 SG_ FCAM_OBJ27_ExistProbability : 229|4@0+ (0.1,0) [0|1] ""  MHU
 SG_ FCAM_OBJ27_TurnSignal : 225|2@0+ (1,0) [0|3] ""  MHU
 SG_ FCAM_OBJ27_Heading : 459|11@0+ (0.001,-1) [-1|1] "rad"  MHU
 SG_ FCAM_OBJ27_BrakeLight : 215|1@0+ (1,0) [0|1] ""  MHU
 SG_ FCAM_OBJ28_Class : 222|4@0+ (1,0) [0|12] ""  MHU
 SG_ FCAM_OBJ28_LgtDis : 464|14@0+ (0.025,-30) [-30|370] "m"  MHU
 SG_ FCAM_OBJ28_ID : 443|8@0+ (1,0) [0|255] ""  MHU
 SG_ FCAM_OBJ28_ClosestSurface : 218|3@0+ (1,0) [0|7] ""  MHU
 SG_ FCAM_OBJ28_LatDis : 424|13@0+ (0.025,-100) [-100|100] "m"  MHU
 SG_ FCAM_OBJ28_ExistProbability : 214|4@0+ (0.1,0) [0|1] ""  MHU
 SG_ FCAM_OBJ28_TurnSignal : 231|2@0+ (1,0) [0|3] ""  MHU
 SG_ FCAM_OBJ28_Heading : 419|11@0+ (0.001,-1) [-1|1] "rad"  MHU
 SG_ FCAM_OBJ28_BrakeLight : 223|1@0+ (1,0) [0|1] ""  MHU
 SG_ FCAM_OBJ29_Class : 203|4@0+ (1,0) [0|12] ""  MHU
 SG_ FCAM_OBJ29_LgtDis : 401|14@0+ (0.025,-30) [-30|370] "m"  MHU
 SG_ FCAM_OBJ29_ID : 393|8@0+ (1,0) [0|255] ""  MHU
 SG_ FCAM_OBJ29_ClosestSurface : 164|3@0+ (1,0) [0|7] ""  MHU
 SG_ FCAM_OBJ29_LatDis : 390|13@0+ (0.025,-100) [-100|100] "m"  MHU
 SG_ FCAM_OBJ29_ExistProbability : 195|4@0+ (0.1,0) [0|1] ""  MHU
 SG_ FCAM_OBJ29_TurnSignal : 161|2@0+ (1,0) [0|3] ""  MHU
 SG_ FCAM_OBJ29_Heading : 369|11@0+ (0.001,-1) [-1|1] "rad"  MHU
 SG_ FCAM_OBJ29_BrakeLight : 153|1@0+ (1,0) [0|1] ""  MHU
 SG_ FCAM_OBJ30_Class : 199|4@0+ (1,0) [0|12] ""  MHU
 SG_ FCAM_OBJ30_LgtDis : 367|14@0+ (0.025,-30) [-30|370] "m"  MHU
 SG_ FCAM_OBJ30_ID : 359|8@0+ (1,0) [0|255] ""  MHU
 SG_ FCAM_OBJ30_ClosestSurface : 173|3@0+ (1,0) [0|7] ""  MHU
 SG_ FCAM_OBJ30_LatDis : 340|13@0+ (0.025,-100) [-100|100] "m"  MHU
 SG_ FCAM_OBJ30_ExistProbability : 187|4@0+ (0.1,0) [0|1] ""  MHU
 SG_ FCAM_OBJ30_TurnSignal : 156|2@0+ (1,0) [0|3] ""  MHU
 SG_ FCAM_OBJ30_Heading : 335|11@0+ (0.001,-1) [-1|1] "rad"  MHU
 SG_ FCAM_OBJ30_BrakeLight : 154|1@0+ (1,0) [0|1] ""  MHU
 SG_ FCAM_OBJ31_Class : 191|4@0+ (1,0) [0|12] ""  MHU
 SG_ FCAM_OBJ31_LgtDis : 317|14@0+ (0.025,-30) [-30|370] "m"  MHU
 SG_ FCAM_OBJ31_ID : 291|8@0+ (1,0) [0|255] ""  MHU
 SG_ FCAM_OBJ31_ClosestSurface : 159|3@0+ (1,0) [0|7] ""  MHU
 SG_ FCAM_OBJ31_LatDis : 272|13@0+ (0.025,-100) [-100|100] "m"  MHU
 SG_ FCAM_OBJ31_ExistProbability : 207|4@0+ (0.1,0) [0|1] ""  MHU
 SG_ FCAM_OBJ31_TurnSignal : 166|2@0+ (1,0) [0|3] ""  MHU
 SG_ FCAM_OBJ31_Heading : 267|11@0+ (0.001,-1) [-1|1] "rad"  MHU
 SG_ FCAM_OBJ31_BrakeLight : 152|1@0+ (1,0) [0|1] ""  MHU
 SG_ FCAM_OBJ32_Class : 179|4@0+ (1,0) [0|12] ""  MHU
 SG_ FCAM_OBJ32_LgtDis : 299|14@0+ (0.025,-30) [-30|370] "m"  MHU
 SG_ FCAM_OBJ32_ID : 259|8@0+ (1,0) [0|255] ""  MHU
 SG_ FCAM_OBJ32_ClosestSurface : 170|3@0+ (1,0) [0|7] ""  MHU
 SG_ FCAM_OBJ32_LatDis : 240|13@0+ (0.025,-100) [-100|100] "m"  MHU
 SG_ FCAM_OBJ32_ExistProbability : 183|4@0+ (0.1,0) [0|1] ""  MHU
 SG_ FCAM_OBJ32_TurnSignal : 175|2@0+ (1,0) [0|3] ""  MHU
 SG_ FCAM_OBJ32_Heading : 235|11@0+ (0.001,-1) [-1|1] "rad"  MHU
 SG_ FCAM_OBJ32_BrakeLight : 167|1@0+ (1,0) [0|1] ""  MHU

BO_ 850 FCAM_ADAS_BODY: 8 FCAM_I
 SG_ CRC_FCAM_ADAS_BODY : 7|8@0+ (1,0) [0|255] ""  CVC_I,MHU,ADCU_I
 SG_ ALIVE_FCAM_ADAS_BODY : 11|4@0+ (1,0) [0|15] ""  CVC_I,MHU,ADCU_I
 SG_ FCAM_AHB_sens_Feed : 13|2@0+ (1,0) [0|3] ""  CVC_I,MHU
 SG_ FCAM_AHB_Mode_Feed : 14|1@0+ (1,0) [0|1] ""  CVC_I,MHU
 SG_ FCAM_AHB_check : 17|2@0+ (1,0) [0|3] ""  CVC_I,MHU,ADCU_I
 SG_ FCAM_AHB_state : 20|3@0+ (1,0) [0|7] ""  CVC_I,MHU,ADCU_I
 SG_ FCAM_AHB_RBPos : 36|3@0+ (1,0) [0|7] ""  CVC_I,MHU
 SG_ FCAM_AHB_LBPos : 39|3@0+ (1,0) [0|7] ""  CVC_I,MHU
 SG_ FCAM_DashCam_Status : 23|3@0+ (1,0) [0|7] ""  CVC_I,MHU,ADCU_I
 SG_ FCAM_Body_HeadlightReq : 15|1@0+ (1,0) [0|1] ""  CVC_I,MHU
 SG_ FCAM_Body_FoldMirrorReq : 31|2@0+ (1,0) [0|3] ""  CVC_I,MHU
 SG_ FCAM_Body_Status : 26|3@0+ (1,0) [0|7] ""  CVC_I,MHU
 SG_ FCAM_Body_IndicatorlightReq : 29|3@0+ (1,0) [0|7] ""  CVC_I,MHU

BO_ 851 FCAM_CMP_ACC: 8 FCAM_I
 SG_ CRC_FCAM_CMP_ACC : 7|8@0+ (1,0) [0|255] ""  CVC_I,MHU,ADCU_I
 SG_ ALIVE_FCAM_CMP_ACC : 11|4@0+ (1,0) [0|15] ""  CVC_I,MHU,ADCU_I
 SG_ FCAM_ACC_ObjDetec : 29|1@0+ (1,0) [0|1] ""  CVC_I,MHU,ADCU_I
 SG_ FCAM_ISA_check : 13|2@0+ (1,0) [0|3] ""  CVC_I,MHU,ADCU_I
 SG_ FCAM_ISA_Mode_SW_Feed : 15|2@0+ (1,0) [0|3] ""  CVC_I,MHU,ADCU_I
 SG_ FCAM_TagSpeed_ICON_Feed : 18|3@0+ (1,0) [0|7] ""  CVC_I,MHU,ADCU_I
 SG_ FCAM_ISA_PopUp_Feed : 23|4@0+ (1,0) [0|15] ""  CVC_I,MHU
 SG_ FCAM_ISA_Btn_Feed : 24|1@0+ (1,0) [0|1] ""  CVC_I,MHU,ADCU_I
 SG_ FCAM_ACC_DistSet_upper_Feed : 25|1@0+ (1,0) [0|1] ""  CVC_I,MHU,ADCU_I
 SG_ FCAM_ACC_TimeGapSet : 28|3@0+ (1,0) [0|7] ""  CVC_I,MHU,ADCU_I
 SG_ FCAM_ACC_State : 47|4@0+ (1,0) [0|15] ""  CVC_I,MHU,ADCU_I
 SG_ FCAM_ACC_TagSpeed : 39|8@0+ (1,0) [0|255] "km/h"  CVC_I,MHU,ADCU_I
 SG_ FCAM_ACC_PopUp_Feed : 43|4@0+ (1,0) [0|15] ""  CVC_I,MHU,ADCU_I
 SG_ FCAM_ACC_check : 31|2@0+ (1,0) [0|3] ""  CVC_I,MHU,ADCU_I
 SG_ FCAM_ISA_ICON_Feed : 50|3@0+ (1,0) [0|7] ""  CVC_I,MHU,ADCU_I
 SG_ FCAM_ACC_DistSet_lower_Feed : 51|1@0+ (1,0) [0|1] ""  CVC_I,MHU,ADCU_I
 SG_ FCAM_ACC_SpdSet_upper_Feed : 52|1@0+ (1,0) [0|1] ""  CVC_I,MHU,ADCU_I
 SG_ FCAM_ACC_SpdSet_lower_Feed : 53|1@0+ (1,0) [0|1] ""  CVC_I,MHU,ADCU_I
 SG_ FCAM_ACC_On_Feed : 54|1@0+ (1,0) [0|1] ""  CVC_I,MHU,ADCU_I
 SG_ FCAM_ACC_Set_Feed : 55|1@0+ (1,0) [0|1] ""  CVC_I,MHU,ADCU_I
 SG_ FCAM_ACC_CnlBtn_Feed : 56|1@0+ (1,0) [0|1] ""  CVC_I,MHU,ADCU_I
 SG_ FCAM_ACC_Res_Feed : 57|1@0+ (1,0) [0|1] ""  CVC_I,MHU,ADCU_I
 SG_ FCAM_ACC_ICON_Feed : 60|3@0+ (1,0) [0|7] ""  CVC_I,MHU,ADCU_I
 SG_ FCAM_ISA_Status : 63|3@0+ (1,0) [0|7] ""  CVC_I,MHU,ADCU_I
 SG_ FCAM_ACC_DriveOff : 19|1@0+ (1,0) [0|1] ""  CVC_I,MHU,ADCU_I

BO_ 1115 FCAM_HOD: 8 FCAM_I
 SG_ FCAM_HOD_state_requesting : 57|2@0+ (1,0) [0|3] ""  CVC_I

CM_ SG_ 538 DMS_HeadPitch "Head pitch angle.";
CM_ SG_ 538 DMS_HeadRoll "Head roll angle.";
CM_ SG_ 538 DMS_HeadYaw "Head yaw angle.";
CM_ SG_ 538 DMS_HeadX "Distance of X axis between head and camera.";
CM_ SG_ 538 DMS_HeadY "Distance of Y axis between head and camera.";
CM_ SG_ 538 DMS_HeadZ "Distance of Z axis between head and camera.";
CM_ SG_ 601 MHU_Set_Sentry_Mode_Alarm "On/Off Alarm Sound​";
CM_ SG_ 601 MHU_SET_SentryActivation "On/Off Sentry Mode setting";
CM_ SG_ 672 DrvSeatHeatSet "Driver's seat heating setting(Reserved)";
CM_ SG_ 672 PassSeatHeatSet "Passenger seat heating setting(Reserved)";
CM_ SG_ 672 Rear1DrvSeatHeatSet "Second row driver's seat heating setting(Reserved)";
CM_ SG_ 672 Rear1PassSeatHeatSet "Heating setting for the second row passenger seat(Reserved)";
CM_ SG_ 672 Rear2DrvSeatHeatSet "Third row driver's seat heating setting(Reserved)";
CM_ SG_ 672 Rear2PassSeatHeatSet "Third row passenger seat heating setting(Reserved)";
CM_ SG_ 672 CVC_FLSeatVent_Req "Driver's seat ventilation setting";
CM_ SG_ 672 CVC_FRSeatVent_Req "Passenger seat ventilation settings";
CM_ SG_ 672 CVC_RLSeatVent_Req "Ventilation setting for the driver's side seat in the second row";
CM_ SG_ 672 CVC_RRSeatVent_Req "Ventilation setting for the second row passenger seat";
CM_ SG_ 673 DrvSeatMsgStrLvlSet "Driver's seat massage intensity level setting";
CM_ SG_ 673 PassSeatMsgStrLvlSet "Passenger seat massage intensity level setting";
CM_ SG_ 673 Rear1DrvSeatMsgStrLvlSet "Second row driver's side seat massage intensity level setting";
CM_ SG_ 673 Rear1PassSeatMsgStrLvlSet "Second row passenger seat massage intensity level setting";
CM_ SG_ 673 DrvSeatMsgModeSet "Driver's seat massage mode setting";
CM_ SG_ 673 PassSeatMsgModeSet "Passenger seat massage mode setting";
CM_ SG_ 673 Rear1DrvSeatMsgModeSet "Second row driver's side seat massage mode setting";
CM_ SG_ 673 Rear1PassSeatMsgModeSet "Second row passenger seat massage mode setting";
CM_ SG_ 753 MHU_STAT_AirbagWarnLamp "Status of Airbag telltale warning";
CM_ SG_ 717 MHU_ADASISv2_Container "ADASIS v2 container from (eHorizon inside MHU) to Reconstructor (FCAM) ADAS system";
CM_ SG_ 762 MHU_GPS_Time_UTC "64bit as Linux timestamp";
CM_ SG_ 776 MHU_CPD_Setting "Setting for CPD";
CM_ SG_ 776 MHU_CPD_Confirmation_On_HMI "Input signal for user confirmation or timeout from HMI.";
CM_ SG_ 788 CRC_MHU_RAEB "Checksum";
CM_ SG_ 788 ALIVE_MHU_RAEB "Alive Counter";
CM_ SG_ 788 MHU_RAEB_check "Rear Automatic Emergency Brake Check from MHU";
CM_ SG_ 788 MHU_RAEB_Warning "Rear Automatic Emergency Brake warning from MHU";
CM_ SG_ 788 MHU_RAEB_State "Rear Automatic Emergency Brake State MHU";
CM_ SG_ 788 MHU_RAEB_BrakeCommand "Deceleration command value of Rear AEB  function";
CM_ SG_ 788 MHU_RAEB_Available "RAEB Function avaiblity in MHU ECU";
CM_ SG_ 788 MHU_RAEB_FuncActive "RAEB function activation status from MHU ECU";
CM_ SG_ 788 MHU_RAEB_BrakeType "Low Speed Brake type";
CM_ SG_ 788 MHU_RAEB_PullEPBOpt "Pull EPB option for Post RAEB";
CM_ SG_ 788 MHU_RAEB_BrakeReq_Source "Function request to trigger Brake request to FAEB ( Front ACPE, FCTB, FAEB)";
CM_ SG_ 791 CRC_MHU_SVM_CMD "Checksum";
CM_ SG_ 791 ALIVE_MHU_SVM_CMD "Alive Counter";
CM_ SG_ 791 MHU_SVM_ShowAVMReq "RVC/SVM Showing status from MHU";
CM_ SG_ 791 MHU_SVM_ViewRequest "Request display SVM View";
CM_ SG_ 791 MHU_SVM_BlindspotView_Feed "SVM Blindspot View Status Feedback";
CM_ SG_ 800 Latitude "Geodetic latitude in decimal degrees";
CM_ SG_ 800 Longitude "Geodetic longitude in decimal degrees";
CM_ SG_ 800 Altitude "Height above WGS84 ellipsoid";
CM_ SG_ 800 Speed "Ground speed over earth surface";
CM_ SG_ 800 Vertical_Speed "Vertical velocity (climb/descent rate)";
CM_ SG_ 800 Heading "heading from GNSS";
CM_ SG_ 801 Latitude_DR "Geodetic latitude in decimal degrees Dead Reckoning";
CM_ SG_ 801 Longitude_DR "Geodetic longitude in decimal degrees Dead Reckoning";
CM_ SG_ 801 Course_DR "Course over ground (track angle)";
CM_ SG_ 801 Heading_DR "True heading from north (DR-enhanced)";
CM_ SG_ 801 Heading_Std "Heading standard deviation";
CM_ SG_ 801 Roll "Vehicle roll angle (DR)";
CM_ SG_ 801 Pitch "Vehicle pitch angle (DR)";
CM_ SG_ 801 DeadReckoning_Status "DeadReckoning solution status (DR)";
CM_ SG_ 802 Unix_Timestamp "Seconds since January 1, 1970 UTC";
CM_ SG_ 802 GPS_Week "GPS week number since Jan 6, 1980";
CM_ SG_ 802 Fix_Type "GPS fix type indicator";
CM_ SG_ 802 Satellites_Used "Number of satellites in solution";
CM_ SG_ 802 Satellites_Visible "Total satellites in view";
CM_ SG_ 802 Fix_Quality "GPS fix quality indicator";
CM_ SG_ 802 HDOP "Horizontal Dilution of Precision";
CM_ SG_ 802 VDOP "Vertical Dilution of Precision";
CM_ SG_ 802 PDOP "Position Dilution of Precision";
CM_ SG_ 802 Satellites_GPS "Number of GPS satellites";
CM_ SG_ 802 Satellites_GLONASS "Number of GLONASS satellites";
CM_ SG_ 802 Satellites_Galileo "Number of Galileo satellites";
CM_ SG_ 802 Satellites_BeiDou "Number of BeiDou satellites";
CM_ SG_ 806 ECEF_X "ECEF X coordinate (Earth-centered)";
CM_ SG_ 806 ECEF_Y "ECEF Y coordinate (Earth-centered)";
CM_ SG_ 806 ECEF_Z "ECEF Z coordinate (Earth-centered)";
CM_ SG_ 806 ECEF_Std "ECEF position standard deviation";
CM_ SG_ 804 Steering_HeatingControl "Steering Heating Control";
CM_ SG_ 1043 MHU_SetSuspensionMode "Set suspension mode";
CM_ SG_ 1043 MHU_SetCDC_EasyAccess "Set up CDC for easy access";
CM_ SG_ 1043 MHU_Set_CDC_Mode "Set CDC mode";
CM_ SG_ 1043 MHU_Set_EAS_CDC_SystemWorkMode "Set EAS CDC system work mode";
CM_ SG_ 1043 MHU_Set_Easy_Load_Mode "Set Easy Load Mode";
CM_ SG_ 1043 MHU_Set_Lift_Jack_Mode "Set automatic lift/jack mode";
CM_ SG_ 1045 CRC_MHU_ADCU_MEBSet_ParkSelect "Checksum";
CM_ SG_ 1045 ALIVE_MHU_ADCU_MEBSet_ParkSelect "Alive Counter";
CM_ SG_ 1045 MHU_ADCU_AutPrkgSlotSel "Automatic parking space selection";
CM_ SG_ 1045 MHU_ADCU_DirSel "Parking assist direction selection";
CM_ SG_ 1047 CVC_MNF_AutoStartReq "Mini fridge auto-on setting when boarding the vehicle";
CM_ SG_ 1047 CVC_MNF_ModeReq "Mini fridge operation mode setting";
CM_ SG_ 1047 CVC_MNF_DoorLock_Req "Mini fridge door switch";
CM_ SG_ 1047 CVC_MNF_TempReq "Mini fridge temperature setting";
CM_ SG_ 1047 CVC_MNF_WorkTimeReq "Mini fridge continuous working duration setting when leaving the vehicle";
CM_ SG_ 1047 CVC_MNF_SpecialModeReq "Mini fridge special mode request";
CM_ SG_ 1050 MHU_SteeringWheel_Telescope "MHU sets the steering wheel telescopic";
CM_ SG_ 1050 MHU_SteeringWheel_EasyEntry "MHU sets the steering wheel for easy access";
CM_ SG_ 1050 MHU_SteeringWheel_Angle "MHU sets steering wheel angle";
CM_ SG_ 1050 MHU_SteeringWheel_Heater "MHU sets steering wheel heating function on/off";
CM_ SG_ 1050 MHU_SteerElecAdj_Req "MHU sets the steering wheel for electric adjustment";
CM_ SG_ 1058 CRC_MHU_STATUS "Checksum";
CM_ SG_ 1058 ALIVE_MHU_STATUS "Alive Counter";
CM_ SG_ 1058 MHU_STAT_Cluster "State of Cluster screen for serving Fail-save mode";
CM_ SG_ 1058 MHU_STAT_Infotainment "State of Infotainment screen for serving Fail-save mode";
CM_ SG_ 1058 MHU_STAT_MileageUnit "Indicate current unit of mileage display in Screen (Km or Miles)";
CM_ SG_ 1058 MHU_STAT_PressureUnit "Indicate current unit of Pressure(psi, Bar, kPa)";
CM_ SG_ 1058 MHU_STAT_TemperatureUnit "Indicate current unit of Temperature (C, F)";
CM_ SG_ 1058 MHU_STAT_DateTimeFormat "Indicate current date time format (12H and 24H)";
CM_ SG_ 1058 MHU_Operation_State "Operation state of MHU";
CM_ SG_ 1058 MHU_STAT_Language "Indicate current Language";
CM_ SG_ 1058 MHU_STAT_EnergyConsumptionUnit "Indicate current unit of Enery Consumption (KWH per 100Km)";
CM_ SG_ 1058 MHU_STAT_SaleCountry "Current Sale Country by Map engine - encode by ISO 3166-1 numeric";
CM_ SG_ 1058 MHU_STAT_BatLvlPopsetting "MHU_STAT_BatLvlPopsetting";
CM_ SG_ 1058 MHU_STAT_DistToEmptyUnit "Battery unit";
CM_ SG_ 1058 MHU_DCM_Status "Indicate if there is any fault related to DCM  from MHU";
CM_ SG_ 1092 CRC_MHU_FCAM_RP_Ctrl "Checksum";
CM_ SG_ 1092 ALIVE_MHU_FCAM_RP_Ctrl "Roling counter";
CM_ SG_ 1092 MHU_RPParkingstartReq "APP remote start auto parking";
CM_ SG_ 1092 MHU_RP_ParkOutModeConfirm "RP park out mode confirmation";
CM_ SG_ 1092 MHU_RP_ParkOutDircnConfirm "park out direction is confirmed";
CM_ SG_ 1092 MHU_RemoteconnectionSts "MHU remote connection status";
CM_ SG_ 1092 MHU_RP_FuncMode "Functional mode request";
CM_ SG_ 1092 MHU_SMParkingstartReq "APP remote start SM";
CM_ SG_ 1092 MHU_SMParkingControlReq "APP SM request(handshake)";
CM_ SG_ 1092 MHU_RP_RecoverParking "RP Parking Recovery Request";
CM_ SG_ 1092 MHU_RPStraightParkingDir "Straight in and straight out of the form direction";
CM_ SG_ 1092 MHU_SM_global_path_Status "Reserved for SM (current not use)";
CM_ SG_ 1092 MHU_SM_QuitReq "SM exit request";
CM_ SG_ 1092 MHU_RPParkingControlReq "APP remote control parking request(handshake)";
CM_ SG_ 1092 MHU_RP_QuitReq "RP exit request";
CM_ SG_ 1095 CRC_MHU_CarMode_Switch "Checksum";
CM_ SG_ 1095 ALIVE_MHU_CarMode_Switch "Alive counter";
CM_ SG_ 1095 MHU_AVH_Sw "Set Car Auto vehicle hold (AVH) mode";
CM_ SG_ 1095 MHU_TowingMode_Sw "Set Car towing mode";
CM_ SG_ 1095 MHU_HDC_Switch "HDC switch feedback status";
CM_ SG_ 1095 MHU_SET_WashMode "Set Car in Wash mode";
CM_ SG_ 1095 MHU_TowMode_Req "Tow Mode Set";
CM_ SG_ 1095 MHU_ESC_TCS_Switch "Select mode for WCBS";
CM_ SG_ 1095 MHU_V2LPowertrans_sts "MHU V2L Power transfer status";
CM_ SG_ 1105 CRC_MHU_FCAM_RSSI "Checksum";
CM_ SG_ 1105 ALIVE_MHU_FCAM_RSSI "Roling counter";
CM_ SG_ 1105 RSSI_Value "RSSI value";
CM_ SG_ 1116 CRC_MHU_SVM_DMS_STS "DMS status alive counter";
CM_ SG_ 1116 ALIVE_MHU_SVM_DMS_STS "DMS status check sum";
CM_ SG_ 1116 MHU_SVM_FCamera_Fault "This signal to indicate Front SVM Camera error.";
CM_ SG_ 1116 MHU_SVM_LCamera_Fault "This signal to indicate Left SVM Camera error.";
CM_ SG_ 1116 MHU_SVM_RCamera_Fault "This signal to indicate Rear SVM Camera error.";
CM_ SG_ 1116 MHU_SVM_RightCamera_Fault "This signal to indicate Right SVM Camera error.";
CM_ SG_ 1116 MHU_SETTING_DMSWarning "This signal is used to set DMS warning";
CM_ SG_ 1116 MHU_DMS_Status_feed "This signal indicates DMS current status";
CM_ SG_ 1116 MHU_DMS_System_Status "This signal indicates DMS failure status";
CM_ SG_ 1120 CRC_MHU_ACPE_CMD "Checksum";
CM_ SG_ 1120 ALIVE_MHU_ACPE_CMD "Alive counter";
CM_ SG_ 1120 MHU_ACPE_PowerCommand "ACPE Power control intervence command";
CM_ SG_ 1120 MHU_ACPE_BrakeCommand "ACPE Brake flag intervence to FAEB/Rear AEB ECU";
CM_ SG_ 1120 MHU_ACPE_Available "ACPE function avaibility in ADCU";
CM_ SG_ 1120 MHU_ACPE_FuncActive "ACPE function active state";
CM_ SG_ 1120 MHU_ACPE_HMICommand "ACPE HMI command request to display HMI alert to driver";
CM_ SG_ 1120 MHU_ACPE_State "ACPE State";
CM_ SG_ 1120 MHU_ACPE_Setting_Feed "ACPE Setting feedback from Vehicle ACPE setting request";
CM_ SG_ 1120 MHU_ACPE_Sens_Feed "ACPE Setting Sensitivsity feedback from Vehicle ACPE sensitivsity setting request";
CM_ SG_ 1120 MHU_ACPE_Check "ACPE function heath status";
CM_ SG_ 1120 MHU_ACPE_TargetDeccel "Target Deccel for the ACPE demand";
CM_ SG_ 651 CRC_TBOX_ADCU_VAP_Status "Checksum";
CM_ SG_ 651 ALIVE_TBOX_ADCU_VAP_Status "Alive Counter";
CM_ SG_ 651 TBOX_ADCU_VAP_UserSpotSelect "Parking User Spot selection feedback from TBOX";
CM_ SG_ 761 TBOX_GPS_Time_UTC "64bit as Linux timestamp";
CM_ SG_ 1033 TBOX_IntrusionAlertStatus "Detection of Intrusion Alert in the CVC_B";
CM_ SG_ 1034 TBOX_BKBattery_Malfunction "Indicate failure in Backup Battery include Backup Battery State Of Health (SOH) below 70%, Bub absent,OVP,OTP,OCP";
CM_ SG_ 1034 TBOX_eCall_Malfunction "Indicate Malfunction occurred";
CM_ SG_ 1042 CRC_TBOX_eCall_system_status "Checksum";
CM_ SG_ 1042 ALIVE_TBOX_eCall_system_status "Alive Counter";
CM_ SG_ 1042 eCall_state "eCall Status.";
CM_ SG_ 1046 TBOX_GPS_ALTITUDE "The altitude of the current location";
CM_ SG_ 1048 TBOX_MNF_ModeReq "Mini fridge operation mode setting";
CM_ SG_ 1048 TBOX_MNF_TempReq "Mini fridge temperature setting";
CM_ SG_ 1048 TBOX_MNF_WorkTimeReq "Mini fridge continuous working duration setting when leaving the vehicle";
CM_ SG_ 1048 TBOX_MNF_SpecialModeReq "Mini fridge special mode request";
CM_ SG_ 128 CRC_FCAM_TSR_STATUS "Checksum";
CM_ SG_ 128 ALIVE_FCAM_TSR_STATUS "Alive Counter";
CM_ SG_ 128 FCAM_TSR_PopUp_Feed "PopUP Messaging for TSR function";
CM_ SG_ 128 FCAM_TSR_SLAert_Feed "Feedback of TSR Speed Limit Alert select";
CM_ SG_ 128 FCAM_TSR_Typ2_value "Traffic Sign conditional speed limit value";
CM_ SG_ 128 FCAM_TSR_Typ1 "Traffic Sign Speed Type";
CM_ SG_ 128 FCAM_TSR_Typ1_value "Traffic Sign Speed value";
CM_ SG_ 128 FCAM_TSR_Warning_audible "Speed limit warning";
CM_ SG_ 128 FCAM_TSR_Typ2_Flashing_Warning "Traffic Sign Type 2 warning";
CM_ SG_ 128 FCAM_TSR_Mode_Feed "Traffic Sign Recognition Mode Feedback";
CM_ SG_ 128 FCAM_TSR_AudWarning_Feed "Feedback of TSR Audible Warning On Off";
CM_ SG_ 128 FCAM_TSR_Typ1_Flashing_Warning "Speed limit warning";
CM_ SG_ 128 FCAM_TSR_Typ3 "Traffic Sign Type detected";
CM_ SG_ 128 FCAM_TSR_Typ2 "Traffic Sign minimun Speed Type";
CM_ SG_ 128 FCAM_TSR_State "Traffic Sign Recognition Mode Feedback";
CM_ SG_ 128 FCAM_TSR_Haptic_Mode_Feed "TSR Haptic Settings Feedback";
CM_ SG_ 128 FCAM_SLW_Mode_Feed "TSR Haptic Settings Feedback";
CM_ SG_ 128 FCAM_TSR_Typ1_Distance "distance of the TSR Type1 from current position";
CM_ SG_ 295 CRC_FCAM_LDW_LKA_ELK "Checksum";
CM_ SG_ 295 ALIVE_FCAM_LDW_LKA_ELK "Alive Counter";
CM_ SG_ 295 FCAM_ELKA_ON_feed "Feedback of MHU_ELKA_ON";
CM_ SG_ 295 FCAM_LKA_HOD_state "Hands On and Off status";
CM_ SG_ 295 FCAM_ECU_check "Front camera ECU fault";
CM_ SG_ 295 FCAM_LA_sens_Feed "Sensitivity Feedback";
CM_ SG_ 295 FCAM_LKA_ICON_Feed "ICON Feedback Request for LKA function";
CM_ SG_ 295 FCAM_LDW_check "Lane Departure Warning Check";
CM_ SG_ 295 FCAM_LKA_check "Lans Keeping Assist Check";
CM_ SG_ 295 FCAM_LA_popup "Lane assist function popup message";
CM_ SG_ 295 FCAM_LA_Mode_Feed "Feedback of LA mode select (From MHU setting)";
CM_ SG_ 295 FCAM_LA_LeftLaneColor_Feed "Color of LEFT lane for Lane Assist function";
CM_ SG_ 295 FCAM_LA_RightLaneColor_Feed "Color of RIGHT lane for Lane Assist function";
CM_ SG_ 295 FCAM_ELK_check "Emergency Lane Keeping check";
CM_ SG_ 295 FCAM_ELK_State "ELK status";
CM_ SG_ 295 FCAM_LKA_State "LKA status";
CM_ SG_ 295 FCAM_LDW_State "LDW status";
CM_ SG_ 295 FCAM_ELK_Warning "Types of warning of ELK";
CM_ SG_ 295 FCAM_LDW_Warning "Warning indication for Lane Departure";
CM_ SG_ 295 FCAM_handsoff_Warning_Mode_2 "Hands off warning level";
CM_ SG_ 295 FCAM_LKA_LDW_Haptic_Mode_Feed "LKA Haptic Settings Feedback";
CM_ SG_ 295 FCAM_ELK_Haptic_Mode_Feed "ELK Haptic Settings Feedback";
CM_ SG_ 295 FCAM_LKA_Warning "LKA intervention warning";
CM_ SG_ 314 FCAM_ESA_Sts "The signal indicates the status of ESA function Off  passive, standby,active etc.";
CM_ SG_ 314 FCAM_ESA_Mode "ESA Setting";
CM_ SG_ 314 FCAM_ESA_check "ESA check";
CM_ BO_ 515 "Camera right lane signals";
CM_ SG_ 515 CRC_FCAM_Display_Info "Checksum";
CM_ SG_ 515 ALIVE_FCAM_Display_Info "Alive Counter";
CM_ SG_ 515 R1_LINE_TYPE "Right right lane line type";
CM_ SG_ 515 R0_LINE_TYPE "Right lane line type";
CM_ SG_ 515 FCAM_CIPV_RelLgtVel "Longitudinal relative velocity of CIPV";
CM_ SG_ 515 FCAM_CIPV_OffsetEgoLane "CIPV offset from center of Ego lane";
CM_ SG_ 515 FCAM_CIPV_OffseLaneLine "CIPV offset from center of actual lane line";
CM_ SG_ 515 FCAM_Camera_R1_Line_Type "L1 right line type";
CM_ SG_ 515 FCAM_Camera_L1_Line_Type "ICON Feedback Request for LKA/ELK function";
CM_ SG_ 515 FCAM_R0_ExistProbability "Host Lane right line exist probability";
CM_ SG_ 515 FCAM_L0_ExistProbability "Host Lane left line exist probability";
CM_ SG_ 515 FCAM_L1_ExistProbability "far right line exist probability";
CM_ SG_ 515 FCAM_R1_ExistProbability "far right line exist probability";
CM_ SG_ 515 FCAM_ISA_SpeedLimitCnt_Spd_Feed "Speed Limit Control Offset setting KPH or MPH Feedback";
CM_ SG_ 515 FCAM_ISA_SpeedLimitCnt_Per_Feed "Speed Limit Control Off Setting Percentage Feedback";
CM_ SG_ 515 L1_LINE_TYPE "Left letf lane line type";
CM_ SG_ 515 L0_LINE_TYPE "Left lane line type";
CM_ SG_ 515 FCAM_SCAM_Fault "This signal to indicate SCAM/FCAM error";
CM_ SG_ 515 FCAM_MRR_Fault "This signal to indicate MRR error";
CM_ SG_ 515 FCAM_Collision_Obj_ID "The ID of the potential collided object";
CM_ BO_ 518 "FCAM_HWA_ALC";
CM_ SG_ 518 CRC_FCAM_HWA_ALC "Checksum";
CM_ SG_ 518 ALIVE_FCAM_HWA_ALC "Alive Counter";
CM_ SG_ 518 FCAM_HWA_Fautlstate "HWA fault status";
CM_ SG_ 518 FCAM_ALC_Mode_feed "ALCA feedback status";
CM_ SG_ 518 FCAM_HWA_txtpopup "HWA Text Popups Based on system states- functional cases";
CM_ SG_ 518 FCAM_HWA_state "HWA state";
CM_ SG_ 518 FCAM_ALC_txtpopup "ALC Text Popups Based on system states- functional cases";
CM_ SG_ 518 FCAM_ALC_state "ALC state";
CM_ SG_ 518 FCAM_AESA_DoorUnlock_Req "The signal will be used to unlock the doors once the AESA control is done and the vehicle is brough to stop";
CM_ SG_ 518 FCAM_AESA_ECALL_Req "The signal will be used to triggered the ECALL functionality once the AESA control is done and the vehicle is brough to stop";
CM_ SG_ 518 FCAM_AESA_Status "The signal will be used to indicate the MRM status";
CM_ SG_ 518 FCAM_AESA_popup "AESA Popup";
CM_ SG_ 518 FCAM_TakeOver_Request "Request Driver Take Over Request for ADAS Function";
CM_ SG_ 518 FCAM_Sounds_Feed "Sounds Feedback Request for ADAS function";
CM_ SG_ 518 FCAM_ALC_ICON_Feed "ICON Feedback Request for ALC function";
CM_ SG_ 518 FCAM_HWA_ICON_Feed "ICON Feedback Request for HWA function";
CM_ SG_ 518 FCAM_ALC_Mode_Gaze_Feed "ALC subsetting activation via gaze to mirror";
CM_ SG_ 518 FCAM_ALC_Mode_Recommend_Feed "ALC subsetting activation system recommendation";
CM_ SG_ 518 FCAM_HWA_check "HWA error check";
CM_ SG_ 518 FCAM_EOR_warning "Driver Eyes on Request";
CM_ SG_ 518 FCAM_HWA_Mode_Feed "HWA setting feedback";
CM_ SG_ 527 FCAM_ELK_ONCM_VEH "Detect oncoming vehicle in adjacent lane";
CM_ SG_ 527 FCAM_ELK_ONCM_TTC "Oncoming vehicle ttc";
CM_ SG_ 527 FCAM_ELK_OVTVEH_L "Detect Overtaking vehicle in adjacent lane";
CM_ SG_ 527 FCAM_ELK_OVTVEH_R "Detect Overtaking vehicle in adjacent lane";
CM_ SG_ 527 FCAM_ELK_OVTVEHLEFT_TTC "Overtaking vehicle ttc_Left";
CM_ SG_ 527 FCAM_ELK_OVTVEHRIGHT_TTC "Overtaking vehicle ttc_Right";
CM_ SG_ 527 FCAM_LKA_LATDIS_LEFT "Distance to lane marking when LDW/LKA/ELK Intervnetion start_Left";
CM_ SG_ 527 FCAM_LKA_LATDIS_RIGHT "Distance to lane marking when LDW/LKA/ELK Intervnetion start_Right";
CM_ SG_ 527 FCAM_LKA_LATVEL_LEFT "lateral vel_Left";
CM_ SG_ 527 FCAM_LKA_LATVEL_RIGHT "lateral vel_Right";
CM_ SG_ 527 FCAM_ALCA_REAROBJLEFT_TTC "Left rear collision ttc";
CM_ SG_ 527 FCAM_ALCA_REAROBJRIGHT_TTC "Right rear collision ttc";
CM_ SG_ 527 FCAM_LATERACC_Filtered "Lateral acceleration for LSS intervnetion";
CM_ SG_ 527 FCAM_ADAS_HOD "Arbitrate Steering torque and HOD signal to output HandsON/OFF status";
CM_ SG_ 528 FCAM_NOP_check "NOP error check";
CM_ SG_ 528 FCAM_NOP_state "NOP state";
CM_ SG_ 528 FCAM_NOP_ICON_Feed "NOP ICON";
CM_ SG_ 528 FCAM_NOP_txtpopup "NOP popup message";
CM_ SG_ 528 FCAM_NOP_Warning "NOP hauptic warning request";
CM_ SG_ 528 FCAM_NOP_AAESA_state "AESA state";
CM_ SG_ 528 FCAM_NOP_TOR "NOP take over request";
CM_ SG_ 540 CRC_FCAM_AEB_FCW "Checksum";
CM_ SG_ 540 ALIVE_FCAM_AEB_FCW "Alive Counter";
CM_ SG_ 540 FCAM_AEB_Warning "Automatic Emergency Brake Warning Mode";
CM_ SG_ 540 FCAM_AEB_State "Automatic Emergency Brake State";
CM_ SG_ 540 FCAM_AEB_Mode_Feed "AEB Mode feedback";
CM_ SG_ 540 FCAM_AEB_check "Automatic Emergency Brake Check";
CM_ SG_ 540 FCAM_FCW_Mode_Feed "FCW mode feedback";
CM_ SG_ 540 FCAM_FCW_Sens_Feed "FCW sensitivity feedback";
CM_ SG_ 540 FCAM_FCW_state "FCW status";
CM_ SG_ 540 FCAM_FCW_check "Forward Collision Warning Check";
CM_ SG_ 540 FCAM_FCW_warning "Forward Collision Warning Warning popup";
CM_ SG_ 540 FCAM_CV_AEB_Alert "Full AEB braking flag from Vision for crossing usecase";
CM_ SG_ 540 FCAM_CV_FCW_Alert "FCW flag from Visionfor crossing usecase";
CM_ SG_ 540 FCAM_CV_PartialAEB_Alert "Partial AEB braking flag from Visionfor crossing usecase";
CM_ SG_ 540 FCAM_CV_PreFill_Alert "Prefill flag from Visionfor crossing usecase";
CM_ SG_ 540 FCAM_VD_AEB_Alert "Full AEB braking flag from Visionfor preceding usecase";
CM_ SG_ 540 FCAM_VD_DBS_Alert "DBS/EBA flag from Visionforfor preceding usecase";
CM_ SG_ 540 FCAM_VD_EGOTAP_AEB_Alert "AEB flag from Visionfor turn across path use case";
CM_ SG_ 540 FCAM_VD_FCW_Alert "FCW flag from Visionfor for preceding usecase";
CM_ SG_ 540 FCAM_VD_HeadOn_AEB_Alert "Full AEB braking flag from Visionfor headon usecase";
CM_ SG_ 540 FCAM_VD_PartialAEB_Alert "Partial AEB braking flag from Visionfor preceding usecase";
CM_ SG_ 540 FCAM_VD_Prefill_Alert "Prefill flag from Visionfor preceding usecase";
CM_ SG_ 540 FCAM_VRU_AEB_Alert "AEB braking flag from Visionfor VRU usecase";
CM_ SG_ 540 FCAM_VRU_FCW_Alert "FCW flag from Vision for VRU usecase";
CM_ SG_ 540 FCAM_VRU_PreFill_Alert "Prefill flag from Vision for VRU usecase";
CM_ SG_ 540 FCAM_Fusion_TTC "Time to collision from Fusion";
CM_ SG_ 540 FCAM_AB_TTC "Time to collision from AB";
CM_ SG_ 540 FCAM_AEB_Trigger_Source "AEB trigger source (Vision or Fusion)";
CM_ SG_ 540 FCAM_FCW_Trigger_Source "FCW trigger source (Vision or Fusion)";
CM_ SG_ 540 FCAM_AEB_BrakeReq_Source "Function request to trigger Brake request to FAEB ( Front ACPE, FCTB, FAEB)";
CM_ SG_ 763 Tsync_Message_CRC "CRC";
CM_ SG_ 763 Tsync_Message_ALV "Sequence counter";
CM_ SG_ 763 Tsync_Message_Time_Domain_ID "Time domain ID";
CM_ SG_ 763 Tsync_Message_FUP_Reserved "Reserved";
CM_ SG_ 763 Tsync_Message_FUP_SGW "Synchronized to Gateway state";
CM_ SG_ 763 Tsync_Message_FUP_OVS "Overflow of seconds";
CM_ SG_ 763 Tsync_Message_Type "CAN Tsync message type";
CM_ SG_ 763 Tsync_Message_SYNC_FUP_SyncTimeS "32 bit LSB of the 48 bits seconds part of the time";
CM_ BO_ 833 "FCAM_Camera Object 1 signals";
CM_ SG_ 833 FCAM_OBJ01_Class "The class of object 01";
CM_ SG_ 833 FCAM_OBJ01_LgtDis "Longitudinal distance of object 01";
CM_ SG_ 833 FCAM_OBJ01_ID "The ID of object 01";
CM_ SG_ 833 FCAM_OBJ01_LatDis "Lateral distance of object 01(left minus right positive)";
CM_ SG_ 833 FCAM_OBJ02_Class "The class of object 02";
CM_ SG_ 833 FCAM_OBJ02_LgtDis "Longitudinal distance of object 02";
CM_ SG_ 833 FCAM_OBJ02_ID "The ID of object 02";
CM_ SG_ 833 FCAM_OBJ02_LatDis "Lateral distance of object 02(left minus right positive)";
CM_ SG_ 833 FCAM_OBJ03_Class "The class of object 03";
CM_ SG_ 833 FCAM_OBJ03_LgtDis "Longitudinal distance of object 03";
CM_ SG_ 833 FCAM_OBJ03_ID "The ID of object 03";
CM_ SG_ 833 FCAM_OBJ03_LatDis "Lateral distance of object 03(left minus right positive)";
CM_ SG_ 833 FCAM_OBJ04_Class "The class of object 04";
CM_ SG_ 833 FCAM_OBJ04_LgtDis "Longitudinal distance of object 04";
CM_ SG_ 833 FCAM_OBJ04_ID "The ID of object 04";
CM_ SG_ 833 FCAM_OBJ04_LatDis "Lateral distance of object 04(left minus right positive)";
CM_ SG_ 833 FCAM_OBJ05_Class "The class of object 05";
CM_ SG_ 833 FCAM_OBJ05_LgtDis "Longitudinal distance of object 05";
CM_ SG_ 833 FCAM_OBJ05_ID "The ID of object 05";
CM_ SG_ 833 FCAM_OBJ05_LatDis "Lateral distance of object 05(left minus right positive)";
CM_ SG_ 833 FCAM_OBJ06_Class "The class of object 06";
CM_ SG_ 833 FCAM_OBJ06_LgtDis "Longitudinal distance of object 06";
CM_ SG_ 833 FCAM_OBJ06_ID "The ID of object 06";
CM_ SG_ 833 FCAM_OBJ06_LatDis "Lateral distance of object 06(left minus right positive)";
CM_ SG_ 834 FCAM_LA_veh_pos_right "Vehicle position? to right lane";
CM_ SG_ 834 FCAM_LA_veh_pos_left "Vehicle position? to left lane";
CM_ BO_ 850 "FCAM Auto headlight high beam control and Door Open Warning";
CM_ SG_ 850 CRC_FCAM_ADAS_BODY "Checksum";
CM_ SG_ 850 ALIVE_FCAM_ADAS_BODY "Alive Counter";
CM_ SG_ 850 FCAM_AHB_sens_Feed "Auto headlight high beam sensitivity Feedback";
CM_ SG_ 850 FCAM_AHB_Mode_Feed "Auto headlight high beam On off Feedback";
CM_ SG_ 850 FCAM_AHB_check "Auto headlight high beam control Check";
CM_ SG_ 850 FCAM_AHB_state "Auto headlight high beam control State";
CM_ SG_ 850 FCAM_AHB_RBPos "Right High Beam Position Request Signal";
CM_ SG_ 850 FCAM_AHB_LBPos "Left High Beam Position Request Signal";
CM_ SG_ 850 FCAM_DashCam_Status "Vehicle dash cam status";
CM_ SG_ 850 FCAM_Body_HeadlightReq "FCAM_request BCM to light up headlight lowbeam";
CM_ SG_ 850 FCAM_Body_FoldMirrorReq "FCAM_request BCM to fold rearview mirror";
CM_ SG_ 850 FCAM_Body_Status "FCAM_Status";
CM_ SG_ 850 FCAM_Body_IndicatorlightReq "FCAM_request BCM to light up these light";
CM_ BO_ 851 "ADAS Adaptive Cruise Control";
CM_ SG_ 851 CRC_FCAM_CMP_ACC "Checksum";
CM_ SG_ 851 ALIVE_FCAM_CMP_ACC "Alive Counter";
CM_ SG_ 851 FCAM_ACC_ObjDetec "Lead Object Detected or not";
CM_ SG_ 851 FCAM_ISA_check "Inteligent Speed adaptation Check";
CM_ SG_ 851 FCAM_ISA_Mode_SW_Feed "Feedback of ISA On off(From Steering wheel button)";
CM_ SG_ 851 FCAM_TagSpeed_ICON_Feed "ICON Feedback Request for Target Speed Feedback Display";
CM_ SG_ 851 FCAM_ISA_PopUp_Feed "PopUP Messaging for ISA function";
CM_ SG_ 851 FCAM_ISA_Btn_Feed "Feedback of ISA On Off Button";
CM_ SG_ 851 FCAM_ACC_DistSet_upper_Feed "Feedback of Object Vehicle Gap Distance Adjustment (Increase Button)";
CM_ SG_ 851 FCAM_ACC_TimeGapSet "Adaptive Cruise Control time gap setting";
CM_ SG_ 851 FCAM_ACC_State "The signal indicates the status of the Adaptive Cruise Control function";
CM_ SG_ 851 FCAM_ACC_TagSpeed "Adaptive Cruise Control speed setting";
CM_ SG_ 851 FCAM_ACC_PopUp_Feed "PopUP Messaging for ACC function";
CM_ SG_ 851 FCAM_ACC_check "Adaptive Cruise Control Check";
CM_ SG_ 851 FCAM_ISA_ICON_Feed "ICON Feedback Request for ISA function";
CM_ SG_ 851 FCAM_ACC_DistSet_lower_Feed "Feedback of Object Vehicle Gap Distance Adjustment ( Reduction Button)";
CM_ SG_ 851 FCAM_ACC_SpdSet_upper_Feed "Feedback of Subject Vehicle Speed Setting (Increase Button)";
CM_ SG_ 851 FCAM_ACC_SpdSet_lower_Feed "Feedback of Subject Vehicle Speed Setting ( Reduction Button)";
CM_ SG_ 851 FCAM_ACC_On_Feed "Feedback of ACC On Off Button";
CM_ SG_ 851 FCAM_ACC_Set_Feed "Feedback of ACC Set Button";
CM_ SG_ 851 FCAM_ACC_CnlBtn_Feed "Feedback of ACC Cancel Button";
CM_ SG_ 851 FCAM_ACC_Res_Feed "Feedback of ACC Resume Button";
CM_ SG_ 851 FCAM_ACC_ICON_Feed "ICON Feedback Request for ACC function";
CM_ SG_ 851 FCAM_ISA_Status "The signal indicates the status of the ISA function";
CM_ SG_ 851 FCAM_ACC_DriveOff "DriveOff request flag";
CM_ BO_ 1115 "FCAM_HOD_state_requesting";
CM_ SG_ 1115 FCAM_HOD_state_requesting "Adas requesting HOD state";
BA_DEF_ BO_  "DiagRequest" ENUM  "No","Yes";
BA_DEF_ BO_  "DiagResponse" ENUM  "No","Yes";
BA_DEF_ BO_  "DiagState" ENUM  "No","Yes";
BA_DEF_ BO_  "GenMsgCycleTime" INT 0 65535;
BA_DEF_ BO_  "GenMsgCycleTimeFast" INT 0 65535;
BA_DEF_ BO_  "GenMsgDelayTime" INT 0 65535;
BA_DEF_ BO_  "GenMsgILSupport" ENUM  "No","Yes";
BA_DEF_ BO_  "GenMsgNrOfRepetition" INT 0 65535;
BA_DEF_ BO_  "GenMsgSendType" ENUM  "Cyclic","NoMsgSendType","NotUsed","NotUsed","NotUsed","NotUsed","NotUsed","IfActive","NoMsgSendType","NotUsed";
BA_DEF_ BO_  "NmAsrMessage" ENUM  "No","Yes";
BA_DEF_ BO_  "NmMessage" ENUM  "No","Yes";
BA_DEF_ SG_  "GenSigSendType" ENUM  "Cyclic","NoSigSendType","OnWriteWithRepetition","OnChange","OnChangeWithRepetition","IfActive","IfActiveWithRepetition","OnWrite","NotUsed","NotUsed","NotUsed","NotUsed","NotUsed";
BA_DEF_ SG_  "GenSigStartValue" INT 0 2147483647;
BA_DEF_ SG_  "GenSigTimeoutTime_ALL" INT 0 65535;
BA_DEF_ SG_  "InvalidValue" STRING ;
BA_DEF_ SG_  "GenSigInactiveValue" INT 0 2147483647;
BA_DEF_ BO_  "VFrameFormat" ENUM  "StandardCAN","ExtendedCAN","reserved","J1939PG","reserved","reserved","reserved","reserved","reserved","reserved","reserved","reserved","reserved","reserved","StandardCAN_FD","ExtendedCAN_FD";
BA_DEF_ BO_  "CANFD_BRS" ENUM  "0","1";
BA_DEF_ SG_  "SystemSignalLongSymbol" STRING ;
BA_DEF_ BO_  "SystemMessageLongSymbol" STRING ;
BA_DEF_DEF_  "DiagRequest" "No";
BA_DEF_DEF_  "DiagResponse" "No";
BA_DEF_DEF_  "DiagState" "No";
BA_DEF_DEF_  "GenMsgCycleTime" 0;
BA_DEF_DEF_  "GenMsgCycleTimeFast" 0;
BA_DEF_DEF_  "GenMsgDelayTime" 0;
BA_DEF_DEF_  "GenMsgILSupport" "Yes";
BA_DEF_DEF_  "GenMsgNrOfRepetition" 0;
BA_DEF_DEF_  "GenMsgSendType" "Cyclic";
BA_DEF_DEF_  "NmAsrMessage" "No";
BA_DEF_DEF_  "NmMessage" "No";
BA_DEF_DEF_  "GenSigSendType" "Cyclic";
BA_DEF_DEF_  "GenSigStartValue" 0;
BA_DEF_DEF_  "GenSigTimeoutTime_ALL" 0;
BA_DEF_DEF_  "InvalidValue" "";
BA_DEF_DEF_  "GenSigInactiveValue" 0;
BA_DEF_DEF_  "VFrameFormat" "StandardCAN_FD";
BA_DEF_DEF_  "CANFD_BRS" "1";
BA_DEF_DEF_  "SystemSignalLongSymbol" "";
BA_DEF_DEF_  "SystemMessageLongSymbol" "";
BA_ "GenMsgCycleTime" BO_ 538 100;
BA_ "GenMsgCycleTime" BO_ 599 50;
BA_ "GenMsgCycleTime" BO_ 601 50;
BA_ "GenMsgCycleTime" BO_ 672 80;
BA_ "GenMsgCycleTime" BO_ 673 80;
BA_ "GenMsgCycleTime" BO_ 753 100;
BA_ "GenMsgDelayTime" BO_ 717 50;
BA_ "GenMsgSendType" BO_ 717 1;
BA_ "GenMsgCycleTime" BO_ 762 1000;
BA_ "GenMsgSendType" BO_ 776 1;
BA_ "GenMsgCycleTime" BO_ 788 20;
BA_ "GenMsgCycleTime" BO_ 791 500;
BA_ "GenMsgCycleTime" BO_ 800 100;
BA_ "GenMsgCycleTimeFast" BO_ 800 50;
BA_ "GenMsgCycleTime" BO_ 801 100;
BA_ "GenMsgCycleTimeFast" BO_ 801 50;
BA_ "GenMsgCycleTime" BO_ 802 1000;
BA_ "GenMsgCycleTimeFast" BO_ 802 500;
BA_ "GenMsgCycleTime" BO_ 806 100;
BA_ "GenMsgCycleTimeFast" BO_ 806 50;
BA_ "GenMsgCycleTime" BO_ 804 100;
BA_ "GenMsgCycleTime" BO_ 1043 500;
BA_ "GenMsgCycleTime" BO_ 1045 100;
BA_ "GenMsgCycleTime" BO_ 1047 100;
BA_ "GenMsgCycleTime" BO_ 1050 500;
BA_ "GenMsgCycleTimeFast" BO_ 1050 100;
BA_ "GenMsgNrOfRepetition" BO_ 1050 3;
BA_ "GenMsgCycleTime" BO_ 1058 100;
BA_ "GenMsgCycleTime" BO_ 1092 100;
BA_ "GenMsgCycleTime" BO_ 1095 200;
BA_ "GenMsgCycleTime" BO_ 1105 100;
BA_ "GenMsgCycleTime" BO_ 1116 200;
BA_ "GenMsgCycleTime" BO_ 1120 200;
BA_ "GenMsgCycleTimeFast" BO_ 1120 30;
BA_ "GenMsgNrOfRepetition" BO_ 1120 2;
BA_ "GenMsgCycleTimeFast" BO_ 1969 50;
BA_ "GenMsgNrOfRepetition" BO_ 1969 2;
BA_ "GenMsgSendType" BO_ 1969 1;
BA_ "GenMsgCycleTime" BO_ 651 20;
BA_ "GenMsgCycleTime" BO_ 761 1000;
BA_ "GenMsgSendType" BO_ 1033 1;
BA_ "GenMsgCycleTime" BO_ 1034 1000;
BA_ "GenMsgCycleTimeFast" BO_ 1034 100;
BA_ "GenMsgNrOfRepetition" BO_ 1034 2;
BA_ "GenMsgCycleTime" BO_ 1042 100;
BA_ "GenMsgCycleTime" BO_ 1046 500;
BA_ "GenMsgSendType" BO_ 1048 1;
BA_ "GenMsgCycleTime" BO_ 128 50;
BA_ "GenMsgCycleTimeFast" BO_ 128 15;
BA_ "GenMsgNrOfRepetition" BO_ 128 3;
BA_ "GenMsgCycleTime" BO_ 295 80;
BA_ "GenMsgCycleTimeFast" BO_ 295 15;
BA_ "GenMsgNrOfRepetition" BO_ 295 3;
BA_ "GenMsgCycleTime" BO_ 314 20;
BA_ "GenMsgCycleTime" BO_ 515 50;
BA_ "GenMsgCycleTime" BO_ 518 50;
BA_ "GenMsgCycleTimeFast" BO_ 518 15;
BA_ "GenMsgNrOfRepetition" BO_ 518 3;
BA_ "GenMsgCycleTime" BO_ 527 50;
BA_ "GenMsgCycleTimeFast" BO_ 527 15;
BA_ "GenMsgNrOfRepetition" BO_ 527 3;
BA_ "GenMsgCycleTime" BO_ 528 50;
BA_ "GenMsgCycleTime" BO_ 540 50;
BA_ "GenMsgCycleTime" BO_ 763 1000;
BA_ "GenMsgCycleTime" BO_ 833 100;
BA_ "GenMsgCycleTime" BO_ 834 100;
BA_ "GenMsgCycleTime" BO_ 835 100;
BA_ "GenMsgCycleTime" BO_ 836 100;
BA_ "GenMsgCycleTime" BO_ 837 100;
BA_ "GenMsgCycleTime" BO_ 839 100;
BA_ "GenMsgCycleTime" BO_ 840 100;
BA_ "GenMsgCycleTime" BO_ 850 50;
BA_ "GenMsgCycleTimeFast" BO_ 850 15;
BA_ "GenMsgNrOfRepetition" BO_ 850 3;
BA_ "GenMsgCycleTime" BO_ 851 50;
BA_ "GenMsgCycleTimeFast" BO_ 851 15;
BA_ "GenMsgNrOfRepetition" BO_ 851 3;
BA_ "GenMsgCycleTime" BO_ 1115 500;
BA_ "GenSigStartValue" SG_ 538 DMS_HeadPitch 45;
BA_ "GenSigStartValue" SG_ 538 DMS_HeadRoll 45;
BA_ "GenSigStartValue" SG_ 538 DMS_HeadYaw 255;
BA_ "GenSigStartValue" SG_ 538 DMS_HeadX 2047;
BA_ "GenSigStartValue" SG_ 538 DMS_HeadY 2047;
BA_ "GenSigStartValue" SG_ 538 DMS_HeadZ 2047;
BA_ "InvalidValue" SG_ 599 MHU_RVC_Request "3h";
BA_ "GenSigTimeoutTime_ALL" SG_ 601 CRC_MHU_Sentry_Mode_Info 100;
BA_ "InvalidValue" SG_ 601 ALIVE_MHU_Sentry_Mode_Info "Fh";
BA_ "GenSigTimeoutTime_ALL" SG_ 601 ALIVE_MHU_Sentry_Mode_Info 100;
BA_ "InvalidValue" SG_ 601 MHU_Sentry_Mode_Request "3h";
BA_ "InvalidValue" SG_ 601 MHU_Set_Sentry_Mode_Alarm "3h";
BA_ "GenSigTimeoutTime_ALL" SG_ 601 MHU_Set_Sentry_Mode_Alarm 250;
BA_ "InvalidValue" SG_ 601 MHU_SET_SentryActivation "3h";
BA_ "GenSigTimeoutTime_ALL" SG_ 601 MHU_SET_SentryActivation 250;
BA_ "GenSigStartValue" SG_ 672 DrvSeatHeatSet 1;
BA_ "GenSigStartValue" SG_ 672 PassSeatHeatSet 1;
BA_ "GenSigStartValue" SG_ 672 Rear1DrvSeatHeatSet 1;
BA_ "GenSigStartValue" SG_ 672 Rear1PassSeatHeatSet 1;
BA_ "GenSigStartValue" SG_ 672 Rear2DrvSeatHeatSet 1;
BA_ "GenSigStartValue" SG_ 672 Rear2PassSeatHeatSet 1;
BA_ "GenSigStartValue" SG_ 673 DrvSeatMsgStrLvlSet 1;
BA_ "GenSigStartValue" SG_ 673 PassSeatMsgStrLvlSet 1;
BA_ "GenSigStartValue" SG_ 673 Rear1DrvSeatMsgStrLvlSet 1;
BA_ "GenSigStartValue" SG_ 673 Rear1PassSeatMsgStrLvlSet 1;
BA_ "GenSigSendType" SG_ 717 MHU_ADASISv2_Container 7;
BA_ "GenSigTimeoutTime_ALL" SG_ 762 MHU_GPS_Time_UTC 5000;
BA_ "GenSigSendType" SG_ 776 MHU_CPD_Setting 1;
BA_ "GenSigSendType" SG_ 776 MHU_CPD_Confirmation_On_HMI 1;
BA_ "InvalidValue" SG_ 788 ALIVE_MHU_RAEB "Fh";
BA_ "InvalidValue" SG_ 788 MHU_RAEB_check "7h";
BA_ "InvalidValue" SG_ 788 MHU_RAEB_Warning "7h";
BA_ "InvalidValue" SG_ 788 MHU_RAEB_State "7h";
BA_ "GenSigStartValue" SG_ 788 MHU_RAEB_State 1;
BA_ "InvalidValue" SG_ 788 MHU_RAEB_BrakeCommand "3h";
BA_ "InvalidValue" SG_ 788 MHU_RAEB_Available "3h";
BA_ "GenSigStartValue" SG_ 788 MHU_RAEB_Available 3;
BA_ "InvalidValue" SG_ 788 MHU_RAEB_FuncActive "0h";
BA_ "InvalidValue" SG_ 788 MHU_RAEB_Mode_Feed "3h";
BA_ "GenSigStartValue" SG_ 788 MHU_RAEB_Mode_Feed 3;
BA_ "InvalidValue" SG_ 788 MHU_RAEB_BrakeType "0h";
BA_ "InvalidValue" SG_ 788 MHU_RAEB_PullEPBOpt "0h";
BA_ "InvalidValue" SG_ 788 MHU_RAEB_BrakeReq_Source "7h";
BA_ "GenSigTimeoutTime_ALL" SG_ 788 MHU_RAEB_BrakeReq_Source 1000;
BA_ "GenSigSendType" SG_ 788 MHU_RAEB_BrakeReq_Source 2;
BA_ "GenSigTimeoutTime_ALL" SG_ 791 CRC_MHU_SVM_CMD 2500;
BA_ "InvalidValue" SG_ 791 ALIVE_MHU_SVM_CMD "Fh";
BA_ "GenSigTimeoutTime_ALL" SG_ 791 ALIVE_MHU_SVM_CMD 2500;
BA_ "InvalidValue" SG_ 791 MHU_SVM_ShowAVMReq "7h";
BA_ "GenSigStartValue" SG_ 791 MHU_SVM_ShowAVMReq 7;
BA_ "GenSigTimeoutTime_ALL" SG_ 791 MHU_SVM_ShowAVMReq 2500;
BA_ "GenSigSendType" SG_ 791 MHU_SVM_ShowAVMReq 2;
BA_ "InvalidValue" SG_ 791 MHU_SVM_ViewRequest "1Fh";
BA_ "GenSigStartValue" SG_ 791 MHU_SVM_ViewRequest 31;
BA_ "GenSigTimeoutTime_ALL" SG_ 791 MHU_SVM_ViewRequest 2500;
BA_ "GenSigSendType" SG_ 791 MHU_SVM_ViewRequest 2;
BA_ "InvalidValue" SG_ 791 MHU_SVM_BlindspotView_Feed "3h";
BA_ "GenSigStartValue" SG_ 791 MHU_SVM_BlindspotView_Feed 3;
BA_ "GenSigTimeoutTime_ALL" SG_ 791 MHU_SVM_BlindspotView_Feed 2500;
BA_ "GenSigSendType" SG_ 791 MHU_SVM_BlindspotView_Feed 2;
BA_ "InvalidValue" SG_ 800 Latitude "0h";
BA_ "GenSigTimeoutTime_ALL" SG_ 800 Latitude 300;
BA_ "InvalidValue" SG_ 800 Longitude "0h";
BA_ "GenSigTimeoutTime_ALL" SG_ 800 Longitude 300;
BA_ "InvalidValue" SG_ 800 Altitude "0h";
BA_ "GenSigTimeoutTime_ALL" SG_ 800 Altitude 300;
BA_ "InvalidValue" SG_ 800 Speed "0h";
BA_ "GenSigTimeoutTime_ALL" SG_ 800 Speed 300;
BA_ "InvalidValue" SG_ 800 Vertical_Speed "0h";
BA_ "GenSigTimeoutTime_ALL" SG_ 800 Vertical_Speed 300;
BA_ "InvalidValue" SG_ 800 Heading "0h";
BA_ "GenSigStartValue" SG_ 800 Heading 32768;
BA_ "GenSigTimeoutTime_ALL" SG_ 800 Heading 300;
BA_ "InvalidValue" SG_ 801 Latitude_DR "0h";
BA_ "GenSigTimeoutTime_ALL" SG_ 801 Latitude_DR 300;
BA_ "InvalidValue" SG_ 801 Longitude_DR "0h";
BA_ "GenSigTimeoutTime_ALL" SG_ 801 Longitude_DR 300;
BA_ "InvalidValue" SG_ 801 Course_DR "0h";
BA_ "GenSigTimeoutTime_ALL" SG_ 801 Course_DR 300;
BA_ "InvalidValue" SG_ 801 Heading_DR "0h";
BA_ "GenSigStartValue" SG_ 801 Heading_DR 32768;
BA_ "GenSigTimeoutTime_ALL" SG_ 801 Heading_DR 300;
BA_ "InvalidValue" SG_ 801 Heading_Std "0h";
BA_ "GenSigTimeoutTime_ALL" SG_ 801 Heading_Std 300;
BA_ "InvalidValue" SG_ 801 Roll "0h";
BA_ "GenSigStartValue" SG_ 801 Roll 32768;
BA_ "GenSigTimeoutTime_ALL" SG_ 801 Roll 300;
BA_ "InvalidValue" SG_ 801 Pitch "0h";
BA_ "GenSigStartValue" SG_ 801 Pitch 32768;
BA_ "GenSigTimeoutTime_ALL" SG_ 801 Pitch 300;
BA_ "InvalidValue" SG_ 801 DeadReckoning_Status "0h";
BA_ "GenSigTimeoutTime_ALL" SG_ 801 DeadReckoning_Status 300;
BA_ "InvalidValue" SG_ 802 Unix_Timestamp "0h";
BA_ "GenSigTimeoutTime_ALL" SG_ 802 Unix_Timestamp 3000;
BA_ "InvalidValue" SG_ 802 GPS_Week "0h";
BA_ "GenSigTimeoutTime_ALL" SG_ 802 GPS_Week 3000;
BA_ "InvalidValue" SG_ 802 Fix_Type "0h";
BA_ "GenSigTimeoutTime_ALL" SG_ 802 Fix_Type 3000;
BA_ "InvalidValue" SG_ 802 Satellites_Used "0h";
BA_ "GenSigTimeoutTime_ALL" SG_ 802 Satellites_Used 3000;
BA_ "InvalidValue" SG_ 802 Satellites_Visible "0h";
BA_ "GenSigTimeoutTime_ALL" SG_ 802 Satellites_Visible 3000;
BA_ "InvalidValue" SG_ 802 Fix_Quality "0h";
BA_ "GenSigTimeoutTime_ALL" SG_ 802 Fix_Quality 3000;
BA_ "InvalidValue" SG_ 802 HDOP "64h";
BA_ "GenSigStartValue" SG_ 802 HDOP 100;
BA_ "GenSigTimeoutTime_ALL" SG_ 802 HDOP 3000;
BA_ "InvalidValue" SG_ 802 VDOP "64h";
BA_ "GenSigStartValue" SG_ 802 VDOP 100;
BA_ "GenSigTimeoutTime_ALL" SG_ 802 VDOP 3000;
BA_ "InvalidValue" SG_ 802 PDOP "64h";
BA_ "GenSigStartValue" SG_ 802 PDOP 100;
BA_ "GenSigTimeoutTime_ALL" SG_ 802 PDOP 3000;
BA_ "InvalidValue" SG_ 802 Satellites_GPS "0h";
BA_ "GenSigTimeoutTime_ALL" SG_ 802 Satellites_GPS 3000;
BA_ "InvalidValue" SG_ 802 Satellites_GLONASS "0h";
BA_ "GenSigTimeoutTime_ALL" SG_ 802 Satellites_GLONASS 3000;
BA_ "InvalidValue" SG_ 802 Satellites_Galileo "0h";
BA_ "GenSigTimeoutTime_ALL" SG_ 802 Satellites_Galileo 3000;
BA_ "InvalidValue" SG_ 802 Satellites_BeiDou "0h";
BA_ "GenSigTimeoutTime_ALL" SG_ 802 Satellites_BeiDou 3000;
BA_ "InvalidValue" SG_ 806 ECEF_X "0h";
BA_ "GenSigTimeoutTime_ALL" SG_ 806 ECEF_X 300;
BA_ "InvalidValue" SG_ 806 ECEF_Y "0h";
BA_ "GenSigTimeoutTime_ALL" SG_ 806 ECEF_Y 300;
BA_ "InvalidValue" SG_ 806 ECEF_Z "0h";
BA_ "GenSigTimeoutTime_ALL" SG_ 806 ECEF_Z 300;
BA_ "InvalidValue" SG_ 806 ECEF_Std "0h";
BA_ "GenSigTimeoutTime_ALL" SG_ 806 ECEF_Std 300;
BA_ "GenSigStartValue" SG_ 1043 MHU_SetSuspensionMode 7;
BA_ "InvalidValue" SG_ 1043 MHU_Set_Lift_Jack_Mode "3h";
BA_ "GenSigTimeoutTime_ALL" SG_ 1045 CRC_MHU_ADCU_MEBSet_ParkSelect 500;
BA_ "InvalidValue" SG_ 1045 ALIVE_MHU_ADCU_MEBSet_ParkSelect "Fh";
BA_ "GenSigTimeoutTime_ALL" SG_ 1045 ALIVE_MHU_ADCU_MEBSet_ParkSelect 500;
BA_ "GenSigTimeoutTime_ALL" SG_ 1045 MHU_ADCU_AutPrkgSlotSel 500;
BA_ "GenSigTimeoutTime_ALL" SG_ 1045 MHU_ADCU_DirSel 500;
BA_ "GenSigSendType" SG_ 1047 CVC_MNF_AutoStartReq 4;
BA_ "GenSigSendType" SG_ 1047 CVC_MNF_ModeReq 4;
BA_ "GenSigSendType" SG_ 1047 CVC_MNF_DoorLock_Req 4;
BA_ "GenSigStartValue" SG_ 1047 CVC_MNF_TempReq 20;
BA_ "GenSigSendType" SG_ 1047 CVC_MNF_TempReq 4;
BA_ "GenSigSendType" SG_ 1047 CVC_MNF_WorkTimeReq 4;
BA_ "GenSigSendType" SG_ 1047 CVC_MNF_SpecialModeReq 4;
BA_ "GenSigStartValue" SG_ 1050 MHU_SteeringWheel_Telescope 20;
BA_ "GenSigSendType" SG_ 1050 MHU_SteeringWheel_Telescope 2;
BA_ "GenSigSendType" SG_ 1050 MHU_SteeringWheel_EasyEntry 2;
BA_ "GenSigStartValue" SG_ 1050 MHU_SteeringWheel_Angle 21;
BA_ "GenSigSendType" SG_ 1050 MHU_SteeringWheel_Angle 2;
BA_ "GenSigSendType" SG_ 1050 MHU_SteeringWheel_Heater 2;
BA_ "GenSigSendType" SG_ 1050 MHU_SteerElecAdj_Req 2;
BA_ "InvalidValue" SG_ 1058 ALIVE_MHU_STATUS "Fh";
BA_ "InvalidValue" SG_ 1058 MHU_STAT_MileageUnit "3h";
BA_ "GenSigStartValue" SG_ 1058 MHU_STAT_MileageUnit 3;
BA_ "GenSigStartValue" SG_ 1058 MHU_STAT_PressureUnit 3;
BA_ "GenSigStartValue" SG_ 1058 MHU_STAT_TemperatureUnit 3;
BA_ "GenSigStartValue" SG_ 1058 MHU_STAT_DateTimeFormat 3;
BA_ "GenSigStartValue" SG_ 1058 MHU_STAT_Language 31;
BA_ "GenSigStartValue" SG_ 1058 MHU_STAT_EnergyConsumptionUnit 7;
BA_ "GenSigStartValue" SG_ 1058 MHU_STAT_SaleCountry 1023;
BA_ "InvalidValue" SG_ 1058 MHU_DCM_Status "0h";
BA_ "InvalidValue" SG_ 1092 ALIVE_MHU_FCAM_RP_Ctrl "Fh";
BA_ "GenSigTimeoutTime_ALL" SG_ 1095 CRC_MHU_CarMode_Switch 400;
BA_ "InvalidValue" SG_ 1095 ALIVE_MHU_CarMode_Switch "Fh";
BA_ "GenSigTimeoutTime_ALL" SG_ 1095 ALIVE_MHU_CarMode_Switch 400;
BA_ "GenSigTimeoutTime_ALL" SG_ 1095 MHU_AVH_Sw 400;
BA_ "GenSigTimeoutTime_ALL" SG_ 1095 MHU_TowingMode_Sw 400;
BA_ "InvalidValue" SG_ 1095 MHU_HDC_Switch "3h";
BA_ "GenSigTimeoutTime_ALL" SG_ 1095 MHU_HDC_Switch 400;
BA_ "InvalidValue" SG_ 1095 MHU_SET_WashMode "3h";
BA_ "GenSigTimeoutTime_ALL" SG_ 1095 MHU_SET_WashMode 400;
BA_ "InvalidValue" SG_ 1095 MHU_ESC_TCS_Switch "3h";
BA_ "GenSigTimeoutTime_ALL" SG_ 1095 MHU_ESC_TCS_Switch 200;
BA_ "GenSigTimeoutTime_ALL" SG_ 1095 MHU_V2LPowertrans_sts 200;
BA_ "InvalidValue" SG_ 1105 ALIVE_MHU_FCAM_RSSI "Fh";
BA_ "InvalidValue" SG_ 1116 ALIVE_MHU_SVM_DMS_STS "Fh";
BA_ "InvalidValue" SG_ 1116 MHU_SETTING_DMSWarning "3h";
BA_ "InvalidValue" SG_ 1116 MHU_DMS_Status_feed "Fh";
BA_ "InvalidValue" SG_ 1116 MHU_DMS_System_Status "7h";
BA_ "GenSigTimeoutTime_ALL" SG_ 1120 CRC_MHU_ACPE_CMD 1000;
BA_ "InvalidValue" SG_ 1120 ALIVE_MHU_ACPE_CMD "Fh";
BA_ "GenSigTimeoutTime_ALL" SG_ 1120 ALIVE_MHU_ACPE_CMD 1000;
BA_ "InvalidValue" SG_ 1120 MHU_ACPE_PowerCommand "7h";
BA_ "GenSigStartValue" SG_ 1120 MHU_ACPE_PowerCommand 7;
BA_ "GenSigTimeoutTime_ALL" SG_ 1120 MHU_ACPE_PowerCommand 1000;
BA_ "GenSigSendType" SG_ 1120 MHU_ACPE_PowerCommand 2;
BA_ "InvalidValue" SG_ 1120 MHU_ACPE_BrakeCommand "3h";
BA_ "GenSigStartValue" SG_ 1120 MHU_ACPE_BrakeCommand 3;
BA_ "GenSigTimeoutTime_ALL" SG_ 1120 MHU_ACPE_BrakeCommand 1000;
BA_ "GenSigSendType" SG_ 1120 MHU_ACPE_BrakeCommand 2;
BA_ "InvalidValue" SG_ 1120 MHU_ACPE_Available "3h";
BA_ "GenSigStartValue" SG_ 1120 MHU_ACPE_Available 3;
BA_ "GenSigTimeoutTime_ALL" SG_ 1120 MHU_ACPE_Available 1000;
BA_ "InvalidValue" SG_ 1120 MHU_ACPE_FuncActive "0h";
BA_ "GenSigTimeoutTime_ALL" SG_ 1120 MHU_ACPE_FuncActive 1000;
BA_ "InvalidValue" SG_ 1120 MHU_ACPE_HMICommand "7h";
BA_ "GenSigStartValue" SG_ 1120 MHU_ACPE_HMICommand 7;
BA_ "GenSigTimeoutTime_ALL" SG_ 1120 MHU_ACPE_HMICommand 1000;
BA_ "GenSigSendType" SG_ 1120 MHU_ACPE_HMICommand 2;
BA_ "InvalidValue" SG_ 1120 MHU_ACPE_State "7h";
BA_ "GenSigStartValue" SG_ 1120 MHU_ACPE_State 7;
BA_ "GenSigTimeoutTime_ALL" SG_ 1120 MHU_ACPE_State 1000;
BA_ "InvalidValue" SG_ 1120 MHU_ACPE_Setting_Feed "3h";
BA_ "GenSigStartValue" SG_ 1120 MHU_ACPE_Setting_Feed 3;
BA_ "GenSigTimeoutTime_ALL" SG_ 1120 MHU_ACPE_Setting_Feed 1000;
BA_ "InvalidValue" SG_ 1120 MHU_ACPE_Sens_Feed "3h";
BA_ "GenSigStartValue" SG_ 1120 MHU_ACPE_Sens_Feed 3;
BA_ "GenSigTimeoutTime_ALL" SG_ 1120 MHU_ACPE_Sens_Feed 1000;
BA_ "InvalidValue" SG_ 1120 MHU_ACPE_Check "7h";
BA_ "GenSigStartValue" SG_ 1120 MHU_ACPE_Check 7;
BA_ "GenSigTimeoutTime_ALL" SG_ 1120 MHU_ACPE_Check 1000;
BA_ "InvalidValue" SG_ 1120 MHU_ACPE_TargetDeccel "FFh";
BA_ "GenSigTimeoutTime_ALL" SG_ 1120 MHU_ACPE_TargetDeccel 1000;
BA_ "GenSigSendType" SG_ 1969 MHU_Req_RandomData 2;
BA_ "GenSigSendType" SG_ 1969 MHU_Req_MAC 2;
BA_ "GenSigTimeoutTime_ALL" SG_ 651 CRC_TBOX_ADCU_VAP_Status 100;
BA_ "InvalidValue" SG_ 651 ALIVE_TBOX_ADCU_VAP_Status "Fh";
BA_ "GenSigTimeoutTime_ALL" SG_ 651 ALIVE_TBOX_ADCU_VAP_Status 100;
BA_ "InvalidValue" SG_ 651 TBOX_ADCU_VAP_State "3h";
BA_ "GenSigTimeoutTime_ALL" SG_ 651 TBOX_ADCU_VAP_State 100;
BA_ "InvalidValue" SG_ 651 TBOX_ADCU_VAP_Status "3h";
BA_ "GenSigTimeoutTime_ALL" SG_ 651 TBOX_ADCU_VAP_Status 100;
BA_ "InvalidValue" SG_ 651 TBOX_ADCU_VAP_CappStatus "3h";
BA_ "GenSigTimeoutTime_ALL" SG_ 651 TBOX_ADCU_VAP_CappStatus 100;
BA_ "InvalidValue" SG_ 651 TBOX_ADCU_VAP_ParkButtonPressed "0h";
BA_ "GenSigTimeoutTime_ALL" SG_ 651 TBOX_ADCU_VAP_ParkButtonPressed 100;
BA_ "InvalidValue" SG_ 651 TBOX_ADCU_VAP_Req "0h";
BA_ "GenSigTimeoutTime_ALL" SG_ 651 TBOX_ADCU_VAP_Req 100;
BA_ "InvalidValue" SG_ 651 TBOX_ADCU_VAP_Type "Fh";
BA_ "GenSigTimeoutTime_ALL" SG_ 651 TBOX_ADCU_VAP_Type 100;
BA_ "InvalidValue" SG_ 651 TBOX_ADCU_VAP_TypeSelection "Fh";
BA_ "GenSigTimeoutTime_ALL" SG_ 651 TBOX_ADCU_VAP_TypeSelection 100;
BA_ "InvalidValue" SG_ 651 TBOX_ADCU_VAP_UserSelection "Fh";
BA_ "GenSigTimeoutTime_ALL" SG_ 651 TBOX_ADCU_VAP_UserSelection 100;
BA_ "InvalidValue" SG_ 651 TBOX_ADCU_VAP_NoseDir "3h";
BA_ "GenSigTimeoutTime_ALL" SG_ 651 TBOX_ADCU_VAP_NoseDir 100;
BA_ "InvalidValue" SG_ 651 TBOX_ADCU_VAP_ParkAngle "0h";
BA_ "GenSigTimeoutTime_ALL" SG_ 651 TBOX_ADCU_VAP_ParkAngle 100;
BA_ "InvalidValue" SG_ 651 TBOX_ADCU_VAP_UserAction "0h";
BA_ "GenSigTimeoutTime_ALL" SG_ 651 TBOX_ADCU_VAP_UserAction 100;
BA_ "InvalidValue" SG_ 651 TBOX_ADCU_VAP_UserSpotSelect "0h";
BA_ "GenSigTimeoutTime_ALL" SG_ 651 TBOX_ADCU_VAP_UserSpotSelect 100;
BA_ "GenSigTimeoutTime_ALL" SG_ 761 TBOX_GPS_Time_UTC 5000;
BA_ "GenSigSendType" SG_ 1033 TBOX_IntrusionAlertStatus 1;
BA_ "InvalidValue" SG_ 1034 ALIVE_TBOX_WarnMsg "Fh";
BA_ "GenSigSendType" SG_ 1034 TBOX_BKBattery_Malfunction 4;
BA_ "GenSigSendType" SG_ 1034 TBOX_eCall_Malfunction 4;
BA_ "InvalidValue" SG_ 1042 ALIVE_TBOX_eCall_system_status "Fh";
BA_ "GenSigStartValue" SG_ 1046 TBOX_GPS_ALTITUDE 40000;
BA_ "GenSigSendType" SG_ 1048 TBOX_MNF_ModeReq 1;
BA_ "GenSigSendType" SG_ 1048 TBOX_MNF_TempReq 1;
BA_ "GenSigSendType" SG_ 1048 TBOX_MNF_WorkTimeReq 1;
BA_ "GenSigSendType" SG_ 1048 TBOX_MNF_SpecialModeReq 1;
BA_ "GenSigTimeoutTime_ALL" SG_ 128 CRC_FCAM_TSR_STATUS 500;
BA_ "InvalidValue" SG_ 128 ALIVE_FCAM_TSR_STATUS "Fh";
BA_ "GenSigTimeoutTime_ALL" SG_ 128 ALIVE_FCAM_TSR_STATUS 500;
BA_ "InvalidValue" SG_ 128 FCAM_TSR_PopUp_Feed "Fh";
BA_ "GenSigTimeoutTime_ALL" SG_ 128 FCAM_TSR_PopUp_Feed 500;
BA_ "GenSigSendType" SG_ 128 FCAM_TSR_PopUp_Feed 2;
BA_ "GenSigTimeoutTime_ALL" SG_ 128 FCAM_TSR_SLAert_Feed 500;
BA_ "GenSigSendType" SG_ 128 FCAM_TSR_SLAert_Feed 2;
BA_ "InvalidValue" SG_ 128 FCAM_TSR_Typ2_value "3h";
BA_ "GenSigStartValue" SG_ 128 FCAM_TSR_Typ2_value 1;
BA_ "GenSigTimeoutTime_ALL" SG_ 128 FCAM_TSR_Typ2_value 500;
BA_ "GenSigSendType" SG_ 128 FCAM_TSR_Typ2_value 2;
BA_ "GenSigTimeoutTime_ALL" SG_ 128 FCAM_TSR_Typ1 500;
BA_ "GenSigSendType" SG_ 128 FCAM_TSR_Typ1 2;
BA_ "InvalidValue" SG_ 128 FCAM_TSR_Typ1_value "7h";
BA_ "GenSigTimeoutTime_ALL" SG_ 128 FCAM_TSR_Typ1_value 500;
BA_ "GenSigSendType" SG_ 128 FCAM_TSR_Typ1_value 2;
BA_ "GenSigTimeoutTime_ALL" SG_ 128 FCAM_TSR_Warning_audible 500;
BA_ "GenSigSendType" SG_ 128 FCAM_TSR_Warning_audible 2;
BA_ "InvalidValue" SG_ 128 FCAM_TSR_Typ2_Flashing_Warning "3h";
BA_ "GenSigTimeoutTime_ALL" SG_ 128 FCAM_TSR_Typ2_Flashing_Warning 500;
BA_ "GenSigSendType" SG_ 128 FCAM_TSR_Typ2_Flashing_Warning 2;
BA_ "InvalidValue" SG_ 128 FCAM_TSR_Mode_Feed "1h";
BA_ "GenSigTimeoutTime_ALL" SG_ 128 FCAM_TSR_Mode_Feed 500;
BA_ "GenSigSendType" SG_ 128 FCAM_TSR_Mode_Feed 2;
BA_ "InvalidValue" SG_ 128 FCAM_TSR_AudWarning_Feed "1h";
BA_ "GenSigTimeoutTime_ALL" SG_ 128 FCAM_TSR_AudWarning_Feed 500;
BA_ "GenSigSendType" SG_ 128 FCAM_TSR_AudWarning_Feed 2;
BA_ "InvalidValue" SG_ 128 FCAM_TSR_Typ1_Flashing_Warning "3h";
BA_ "GenSigTimeoutTime_ALL" SG_ 128 FCAM_TSR_Typ1_Flashing_Warning 500;
BA_ "GenSigSendType" SG_ 128 FCAM_TSR_Typ1_Flashing_Warning 2;
BA_ "InvalidValue" SG_ 128 FCAM_TSR_Typ3 "7h";
BA_ "GenSigTimeoutTime_ALL" SG_ 128 FCAM_TSR_Typ3 500;
BA_ "GenSigSendType" SG_ 128 FCAM_TSR_Typ3 2;
BA_ "InvalidValue" SG_ 128 FCAM_TSR_Typ2 "Fh";
BA_ "GenSigTimeoutTime_ALL" SG_ 128 FCAM_TSR_Typ2 500;
BA_ "GenSigSendType" SG_ 128 FCAM_TSR_Typ2 2;
BA_ "InvalidValue" SG_ 128 FCAM_TSR_State "7h";
BA_ "GenSigTimeoutTime_ALL" SG_ 128 FCAM_TSR_State 500;
BA_ "GenSigSendType" SG_ 128 FCAM_TSR_State 2;
BA_ "GenSigTimeoutTime_ALL" SG_ 128 FCAM_TSR_Haptic_Mode_Feed 500;
BA_ "GenSigSendType" SG_ 128 FCAM_TSR_Haptic_Mode_Feed 2;
BA_ "GenSigTimeoutTime_ALL" SG_ 128 FCAM_SLW_Mode_Feed 500;
BA_ "GenSigSendType" SG_ 128 FCAM_SLW_Mode_Feed 2;
BA_ "InvalidValue" SG_ 128 FCAM_DNS_Popup_Feed "3h";
BA_ "GenSigTimeoutTime_ALL" SG_ 128 FCAM_DNS_Popup_Feed 500;
BA_ "InvalidValue" SG_ 128 FCAM_TSR_Typ1_Distance "FFFFFh";
BA_ "GenSigTimeoutTime_ALL" SG_ 128 FCAM_TSR_Typ1_Distance 100;
BA_ "GenSigTimeoutTime_ALL" SG_ 295 CRC_FCAM_LDW_LKA_ELK 800;
BA_ "InvalidValue" SG_ 295 ALIVE_FCAM_LDW_LKA_ELK "Fh";
BA_ "GenSigTimeoutTime_ALL" SG_ 295 ALIVE_FCAM_LDW_LKA_ELK 800;
BA_ "GenSigStartValue" SG_ 295 FCAM_ELKA_ON_feed 1;
BA_ "GenSigTimeoutTime_ALL" SG_ 295 FCAM_ELKA_ON_feed 800;
BA_ "GenSigSendType" SG_ 295 FCAM_ELKA_ON_feed 2;
BA_ "GenSigTimeoutTime_ALL" SG_ 295 FCAM_LKA_HOD_state 500;
BA_ "GenSigSendType" SG_ 295 FCAM_LKA_HOD_state 2;
BA_ "GenSigTimeoutTime_ALL" SG_ 295 FCAM_ECU_check 800;
BA_ "GenSigSendType" SG_ 295 FCAM_ECU_check 2;
BA_ "GenSigTimeoutTime_ALL" SG_ 295 FCAM_LA_sens_Feed 800;
BA_ "GenSigSendType" SG_ 295 FCAM_LA_sens_Feed 2;
BA_ "GenSigTimeoutTime_ALL" SG_ 295 FCAM_LKA_ICON_Feed 800;
BA_ "GenSigSendType" SG_ 295 FCAM_LKA_ICON_Feed 2;
BA_ "InvalidValue" SG_ 295 FCAM_LDW_check "3h";
BA_ "GenSigTimeoutTime_ALL" SG_ 295 FCAM_LDW_check 500;
BA_ "GenSigSendType" SG_ 295 FCAM_LDW_check 2;
BA_ "InvalidValue" SG_ 295 FCAM_LKA_check "3h";
BA_ "GenSigTimeoutTime_ALL" SG_ 295 FCAM_LKA_check 500;
BA_ "GenSigSendType" SG_ 295 FCAM_LKA_check 2;
BA_ "GenSigTimeoutTime_ALL" SG_ 295 FCAM_LA_popup 800;
BA_ "GenSigSendType" SG_ 295 FCAM_LA_popup 2;
BA_ "InvalidValue" SG_ 295 FCAM_LA_Mode_Feed "4h";
BA_ "GenSigStartValue" SG_ 295 FCAM_LA_Mode_Feed 2;
BA_ "GenSigTimeoutTime_ALL" SG_ 295 FCAM_LA_Mode_Feed 800;
BA_ "GenSigSendType" SG_ 295 FCAM_LA_Mode_Feed 2;
BA_ "GenSigTimeoutTime_ALL" SG_ 295 FCAM_LA_LeftLaneColor_Feed 800;
BA_ "GenSigSendType" SG_ 295 FCAM_LA_LeftLaneColor_Feed 2;
BA_ "GenSigTimeoutTime_ALL" SG_ 295 FCAM_LA_RightLaneColor_Feed 300;
BA_ "GenSigSendType" SG_ 295 FCAM_LA_RightLaneColor_Feed 2;
BA_ "GenSigTimeoutTime_ALL" SG_ 295 FCAM_ELK_check 300;
BA_ "GenSigSendType" SG_ 295 FCAM_ELK_check 2;
BA_ "GenSigTimeoutTime_ALL" SG_ 295 FCAM_ELK_State 500;
BA_ "GenSigSendType" SG_ 295 FCAM_ELK_State 2;
BA_ "GenSigTimeoutTime_ALL" SG_ 295 FCAM_LKA_State 800;
BA_ "GenSigSendType" SG_ 295 FCAM_LKA_State 2;
BA_ "GenSigTimeoutTime_ALL" SG_ 295 FCAM_LDW_State 300;
BA_ "GenSigSendType" SG_ 295 FCAM_LDW_State 2;
BA_ "GenSigTimeoutTime_ALL" SG_ 295 FCAM_ELK_Warning 800;
BA_ "GenSigSendType" SG_ 295 FCAM_ELK_Warning 2;
BA_ "GenSigTimeoutTime_ALL" SG_ 295 FCAM_LDW_Warning 300;
BA_ "GenSigSendType" SG_ 295 FCAM_LDW_Warning 2;
BA_ "InvalidValue" SG_ 295 FCAM_handsoff_Warning_Mode_2 "3h";
BA_ "GenSigTimeoutTime_ALL" SG_ 295 FCAM_handsoff_Warning_Mode_2 300;
BA_ "GenSigSendType" SG_ 295 FCAM_handsoff_Warning_Mode_2 2;
BA_ "GenSigTimeoutTime_ALL" SG_ 295 FCAM_LKA_LDW_Haptic_Mode_Feed 300;
BA_ "GenSigSendType" SG_ 295 FCAM_LKA_LDW_Haptic_Mode_Feed 2;
BA_ "GenSigTimeoutTime_ALL" SG_ 295 FCAM_ELK_Haptic_Mode_Feed 300;
BA_ "GenSigSendType" SG_ 295 FCAM_ELK_Haptic_Mode_Feed 2;
BA_ "InvalidValue" SG_ 295 FCAM_LKA_Warning "3h";
BA_ "GenSigTimeoutTime_ALL" SG_ 295 FCAM_LKA_Warning 500;
BA_ "GenSigSendType" SG_ 295 FCAM_LKA_Warning 2;
BA_ "InvalidValue" SG_ 314 ALIVE_FCAM_ESA_Sts "Fh";
BA_ "GenSigTimeoutTime_ALL" SG_ 314 FCAM_ESA_Sts 100;
BA_ "GenSigTimeoutTime_ALL" SG_ 314 FCAM_ESA_Execution_Side 100;
BA_ "GenSigTimeoutTime_ALL" SG_ 314 FCAM_ESA_Popup_Sts 100;
BA_ "GenSigTimeoutTime_ALL" SG_ 314 FCAM_ESA_Mode 100;
BA_ "GenSigStartValue" SG_ 314 FCAM_ESA_check 3;
BA_ "GenSigTimeoutTime_ALL" SG_ 314 FCAM_ESA_check 500;
BA_ "GenSigTimeoutTime_ALL" SG_ 515 CRC_FCAM_Display_Info 500;
BA_ "InvalidValue" SG_ 515 ALIVE_FCAM_Display_Info "Fh";
BA_ "GenSigTimeoutTime_ALL" SG_ 515 ALIVE_FCAM_Display_Info 500;
BA_ "GenSigTimeoutTime_ALL" SG_ 515 R1_LINE_TYPE 500;
BA_ "GenSigTimeoutTime_ALL" SG_ 515 R0_LINE_TYPE 500;
BA_ "GenSigTimeoutTime_ALL" SG_ 515 FCAM_Camera_R1_Line_Type 500;
BA_ "GenSigTimeoutTime_ALL" SG_ 515 FCAM_Camera_L1_Line_Type 500;
BA_ "InvalidValue" SG_ 515 FCAM_R0_ExistProbability "Fh";
BA_ "GenSigTimeoutTime_ALL" SG_ 515 FCAM_R0_ExistProbability 500;
BA_ "InvalidValue" SG_ 515 FCAM_L0_ExistProbability "Fh";
BA_ "GenSigTimeoutTime_ALL" SG_ 515 FCAM_L0_ExistProbability 500;
BA_ "InvalidValue" SG_ 515 FCAM_L1_ExistProbability "Fh";
BA_ "GenSigTimeoutTime_ALL" SG_ 515 FCAM_L1_ExistProbability 500;
BA_ "InvalidValue" SG_ 515 FCAM_R1_ExistProbability "Fh";
BA_ "GenSigTimeoutTime_ALL" SG_ 515 FCAM_R1_ExistProbability 500;
BA_ "InvalidValue" SG_ 515 FCAM_ISA_SpeedLimitCnt_Spd_Feed "Fh";
BA_ "GenSigTimeoutTime_ALL" SG_ 515 FCAM_ISA_SpeedLimitCnt_Spd_Feed 500;
BA_ "InvalidValue" SG_ 515 FCAM_ISA_SpeedLimitCnt_Per_Feed "7h";
BA_ "GenSigTimeoutTime_ALL" SG_ 515 FCAM_ISA_SpeedLimitCnt_Per_Feed 500;
BA_ "InvalidValue" SG_ 515 L1_LINE_TYPE "3h";
BA_ "GenSigTimeoutTime_ALL" SG_ 515 L1_LINE_TYPE 500;
BA_ "InvalidValue" SG_ 515 L0_LINE_TYPE "3h";
BA_ "GenSigTimeoutTime_ALL" SG_ 515 L0_LINE_TYPE 500;
BA_ "InvalidValue" SG_ 515 FCAM_SCAM_Fault "3h";
BA_ "GenSigTimeoutTime_ALL" SG_ 515 FCAM_SCAM_Fault 1500;
BA_ "GenSigSendType" SG_ 515 FCAM_SCAM_Fault 2;
BA_ "InvalidValue" SG_ 515 FCAM_MRR_Fault "3h";
BA_ "GenSigTimeoutTime_ALL" SG_ 515 FCAM_MRR_Fault 1500;
BA_ "GenSigSendType" SG_ 515 FCAM_MRR_Fault 2;
BA_ "InvalidValue" SG_ 515 FCAM_Collision_Obj_ID "0h";
BA_ "GenSigTimeoutTime_ALL" SG_ 515 FCAM_Collision_Obj_ID 500;
BA_ "GenSigTimeoutTime_ALL" SG_ 518 CRC_FCAM_HWA_ALC 500;
BA_ "InvalidValue" SG_ 518 ALIVE_FCAM_HWA_ALC "Fh";
BA_ "GenSigTimeoutTime_ALL" SG_ 518 ALIVE_FCAM_HWA_ALC 500;
BA_ "InvalidValue" SG_ 518 FCAM_HWA_Fautlstate "3h";
BA_ "GenSigTimeoutTime_ALL" SG_ 518 FCAM_HWA_Fautlstate 500;
BA_ "GenSigSendType" SG_ 518 FCAM_HWA_Fautlstate 2;
BA_ "InvalidValue" SG_ 518 FCAM_ALC_Mode_feed "3h";
BA_ "GenSigStartValue" SG_ 518 FCAM_ALC_Mode_feed 1;
BA_ "GenSigTimeoutTime_ALL" SG_ 518 FCAM_ALC_Mode_feed 500;
BA_ "GenSigSendType" SG_ 518 FCAM_ALC_Mode_feed 2;
BA_ "InvalidValue" SG_ 518 FCAM_HWA_txtpopup "Fh";
BA_ "GenSigTimeoutTime_ALL" SG_ 518 FCAM_HWA_txtpopup 500;
BA_ "GenSigSendType" SG_ 518 FCAM_HWA_txtpopup 2;
BA_ "InvalidValue" SG_ 518 FCAM_HWA_state "7h";
BA_ "GenSigTimeoutTime_ALL" SG_ 518 FCAM_HWA_state 500;
BA_ "GenSigSendType" SG_ 518 FCAM_HWA_state 2;
BA_ "InvalidValue" SG_ 518 FCAM_ALC_txtpopup "Fh";
BA_ "GenSigTimeoutTime_ALL" SG_ 518 FCAM_ALC_txtpopup 500;
BA_ "GenSigSendType" SG_ 518 FCAM_ALC_txtpopup 2;
BA_ "InvalidValue" SG_ 518 FCAM_ALC_state "7h";
BA_ "GenSigTimeoutTime_ALL" SG_ 518 FCAM_ALC_state 500;
BA_ "GenSigSendType" SG_ 518 FCAM_ALC_state 2;
BA_ "GenSigTimeoutTime_ALL" SG_ 518 FCAM_AESA_DoorUnlock_Req 500;
BA_ "GenSigSendType" SG_ 518 FCAM_AESA_DoorUnlock_Req 2;
BA_ "GenSigTimeoutTime_ALL" SG_ 518 FCAM_AESA_ECALL_Req 500;
BA_ "GenSigSendType" SG_ 518 FCAM_AESA_ECALL_Req 2;
BA_ "GenSigTimeoutTime_ALL" SG_ 518 FCAM_AESA_Status 500;
BA_ "GenSigSendType" SG_ 518 FCAM_AESA_Status 2;
BA_ "GenSigTimeoutTime_ALL" SG_ 518 FCAM_AESA_popup 500;
BA_ "GenSigSendType" SG_ 518 FCAM_AESA_popup 2;
BA_ "InvalidValue" SG_ 518 FCAM_TakeOver_Request "1Fh";
BA_ "GenSigTimeoutTime_ALL" SG_ 518 FCAM_TakeOver_Request 500;
BA_ "GenSigSendType" SG_ 518 FCAM_TakeOver_Request 2;
BA_ "InvalidValue" SG_ 518 FCAM_Sounds_Feed "1Fh";
BA_ "GenSigTimeoutTime_ALL" SG_ 518 FCAM_Sounds_Feed 500;
BA_ "GenSigSendType" SG_ 518 FCAM_Sounds_Feed 2;
BA_ "InvalidValue" SG_ 518 FCAM_ALC_ICON_Feed "7h";
BA_ "GenSigTimeoutTime_ALL" SG_ 518 FCAM_ALC_ICON_Feed 800;
BA_ "GenSigSendType" SG_ 518 FCAM_ALC_ICON_Feed 2;
BA_ "InvalidValue" SG_ 518 FCAM_HWA_ICON_Feed "7h";
BA_ "GenSigTimeoutTime_ALL" SG_ 518 FCAM_HWA_ICON_Feed 800;
BA_ "GenSigSendType" SG_ 518 FCAM_HWA_ICON_Feed 2;
BA_ "InvalidValue" SG_ 518 FCAM_ALC_Mode_Gaze_Feed "3h";
BA_ "GenSigTimeoutTime_ALL" SG_ 518 FCAM_ALC_Mode_Gaze_Feed 500;
BA_ "GenSigSendType" SG_ 518 FCAM_ALC_Mode_Gaze_Feed 2;
BA_ "InvalidValue" SG_ 518 FCAM_ALC_Mode_Recommend_Feed "3h";
BA_ "GenSigTimeoutTime_ALL" SG_ 518 FCAM_ALC_Mode_Recommend_Feed 500;
BA_ "GenSigSendType" SG_ 518 FCAM_ALC_Mode_Recommend_Feed 2;
BA_ "InvalidValue" SG_ 518 FCAM_HWA_check "3h";
BA_ "GenSigTimeoutTime_ALL" SG_ 518 FCAM_HWA_check 500;
BA_ "InvalidValue" SG_ 518 FCAM_MHU_ALC_Option_feed "3h";
BA_ "GenSigTimeoutTime_ALL" SG_ 518 FCAM_MHU_ALC_Option_feed 500;
BA_ "GenSigTimeoutTime_ALL" SG_ 518 FCAM_EOR_warning 250;
BA_ "GenSigTimeoutTime_ALL" SG_ 518 FCAM_HWA_Mode_Feed 50;
BA_ "GenSigTimeoutTime_ALL" SG_ 527 CRC_FCAM_LKA_ELK 300;
BA_ "InvalidValue" SG_ 527 ALIVE_FCAM_LKA_ELK "Fh";
BA_ "GenSigTimeoutTime_ALL" SG_ 527 ALIVE_FCAM_LKA_ELK 300;
BA_ "GenSigTimeoutTime_ALL" SG_ 527 FCAM_ELK_ONCM_VEH 300;
BA_ "GenSigSendType" SG_ 527 FCAM_ELK_ONCM_VEH 2;
BA_ "GenSigTimeoutTime_ALL" SG_ 527 FCAM_ELK_ONCM_TTC 300;
BA_ "GenSigSendType" SG_ 527 FCAM_ELK_ONCM_TTC 2;
BA_ "GenSigTimeoutTime_ALL" SG_ 527 FCAM_ELK_OVTVEH_L 300;
BA_ "GenSigSendType" SG_ 527 FCAM_ELK_OVTVEH_L 2;
BA_ "GenSigTimeoutTime_ALL" SG_ 527 FCAM_ELK_OVTVEH_R 300;
BA_ "GenSigSendType" SG_ 527 FCAM_ELK_OVTVEH_R 2;
BA_ "GenSigTimeoutTime_ALL" SG_ 527 FCAM_ELK_OVTVEHLEFT_TTC 300;
BA_ "GenSigSendType" SG_ 527 FCAM_ELK_OVTVEHLEFT_TTC 2;
BA_ "GenSigTimeoutTime_ALL" SG_ 527 FCAM_ELK_OVTVEHRIGHT_TTC 300;
BA_ "GenSigSendType" SG_ 527 FCAM_ELK_OVTVEHRIGHT_TTC 2;
BA_ "GenSigTimeoutTime_ALL" SG_ 527 FCAM_LKA_LATDIS_LEFT 300;
BA_ "GenSigSendType" SG_ 527 FCAM_LKA_LATDIS_LEFT 2;
BA_ "GenSigTimeoutTime_ALL" SG_ 527 FCAM_LKA_LATDIS_RIGHT 300;
BA_ "GenSigSendType" SG_ 527 FCAM_LKA_LATDIS_RIGHT 2;
BA_ "GenSigTimeoutTime_ALL" SG_ 527 FCAM_LKA_LATVEL_LEFT 300;
BA_ "GenSigSendType" SG_ 527 FCAM_LKA_LATVEL_LEFT 2;
BA_ "GenSigTimeoutTime_ALL" SG_ 527 FCAM_LKA_LATVEL_RIGHT 300;
BA_ "GenSigSendType" SG_ 527 FCAM_LKA_LATVEL_RIGHT 2;
BA_ "GenSigTimeoutTime_ALL" SG_ 527 FCAM_ALCA_REAROBJLEFT_TTC 300;
BA_ "GenSigSendType" SG_ 527 FCAM_ALCA_REAROBJLEFT_TTC 2;
BA_ "GenSigTimeoutTime_ALL" SG_ 527 FCAM_ALCA_REAROBJRIGHT_TTC 300;
BA_ "GenSigSendType" SG_ 527 FCAM_ALCA_REAROBJRIGHT_TTC 2;
BA_ "GenSigTimeoutTime_ALL" SG_ 527 FCAM_LATERACC_Filtered 300;
BA_ "GenSigSendType" SG_ 527 FCAM_LATERACC_Filtered 2;
BA_ "GenSigTimeoutTime_ALL" SG_ 527 FCAM_ADAS_HOD 300;
BA_ "GenSigSendType" SG_ 527 FCAM_ADAS_HOD 2;
BA_ "GenSigTimeoutTime_ALL" SG_ 528 CRC_FCAM_NOP_Status 5000;
BA_ "InvalidValue" SG_ 528 ALIVE_FCAM_NOP_Status "Fh";
BA_ "GenSigTimeoutTime_ALL" SG_ 528 ALIVE_FCAM_NOP_Status 5000;
BA_ "InvalidValue" SG_ 528 FCAM_NOP_check "3h";
BA_ "GenSigTimeoutTime_ALL" SG_ 528 FCAM_NOP_check 250;
BA_ "GenSigTimeoutTime_ALL" SG_ 528 FCAM_NOP_state 250;
BA_ "InvalidValue" SG_ 528 FCAM_NOP_ICON_Feed "7h";
BA_ "GenSigTimeoutTime_ALL" SG_ 528 FCAM_NOP_ICON_Feed 250;
BA_ "InvalidValue" SG_ 528 FCAM_NOP_txtpopup "1Fh";
BA_ "GenSigTimeoutTime_ALL" SG_ 528 FCAM_NOP_txtpopup 250;
BA_ "InvalidValue" SG_ 528 FCAM_NOP_Warning "3h";
BA_ "GenSigTimeoutTime_ALL" SG_ 528 FCAM_NOP_Warning 250;
BA_ "InvalidValue" SG_ 528 FCAM_NOP_AAESA_state "7h";
BA_ "GenSigTimeoutTime_ALL" SG_ 528 FCAM_NOP_AAESA_state 250;
BA_ "InvalidValue" SG_ 528 FCAM_NOP_TOR "7h";
BA_ "GenSigTimeoutTime_ALL" SG_ 528 FCAM_NOP_TOR 250;
BA_ "InvalidValue" SG_ 528 FCAM_eyesoff_Warning_Mode_2 "7h";
BA_ "GenSigTimeoutTime_ALL" SG_ 528 FCAM_eyesoff_Warning_Mode_2 250;
BA_ "GenSigTimeoutTime_ALL" SG_ 528 FCAM_EOD 250;
BA_ "InvalidValue" SG_ 528 FCAM_NOP_Mode_Feed "0h";
BA_ "GenSigTimeoutTime_ALL" SG_ 528 FCAM_NOP_Mode_Feed 250;
BA_ "InvalidValue" SG_ 528 FCAM_NOP_Type_Feed "3h";
BA_ "GenSigTimeoutTime_ALL" SG_ 528 FCAM_NOP_Type_Feed 250;
BA_ "GenSigTimeoutTime_ALL" SG_ 540 CRC_FCAM_AEB_FCW 500;
BA_ "InvalidValue" SG_ 540 ALIVE_FCAM_AEB_FCW "Fh";
BA_ "GenSigTimeoutTime_ALL" SG_ 540 ALIVE_FCAM_AEB_FCW 500;
BA_ "InvalidValue" SG_ 540 FCAM_AEB_Warning "3h";
BA_ "GenSigTimeoutTime_ALL" SG_ 540 FCAM_AEB_Warning 500;
BA_ "GenSigSendType" SG_ 540 FCAM_AEB_Warning 4;
BA_ "InvalidValue" SG_ 540 FCAM_AEB_State "3h";
BA_ "GenSigStartValue" SG_ 540 FCAM_AEB_State 1;
BA_ "GenSigTimeoutTime_ALL" SG_ 540 FCAM_AEB_State 500;
BA_ "InvalidValue" SG_ 540 FCAM_AEB_Mode_Feed "3h";
BA_ "GenSigStartValue" SG_ 540 FCAM_AEB_Mode_Feed 1;
BA_ "GenSigTimeoutTime_ALL" SG_ 540 FCAM_AEB_Mode_Feed 500;
BA_ "InvalidValue" SG_ 540 FCAM_AEB_check "3h";
BA_ "GenSigTimeoutTime_ALL" SG_ 540 FCAM_AEB_check 500;
BA_ "GenSigStartValue" SG_ 540 FCAM_FCW_Mode_Feed 1;
BA_ "GenSigTimeoutTime_ALL" SG_ 540 FCAM_FCW_Mode_Feed 500;
BA_ "GenSigSendType" SG_ 540 FCAM_FCW_Mode_Feed 2;
BA_ "GenSigStartValue" SG_ 540 FCAM_FCW_Sens_Feed 1;
BA_ "GenSigTimeoutTime_ALL" SG_ 540 FCAM_FCW_Sens_Feed 500;
BA_ "GenSigSendType" SG_ 540 FCAM_FCW_Sens_Feed 2;
BA_ "GenSigStartValue" SG_ 540 FCAM_FCW_state 1;
BA_ "GenSigTimeoutTime_ALL" SG_ 540 FCAM_FCW_state 500;
BA_ "GenSigSendType" SG_ 540 FCAM_FCW_state 2;
BA_ "InvalidValue" SG_ 540 FCAM_FCW_check "3h";
BA_ "GenSigTimeoutTime_ALL" SG_ 540 FCAM_FCW_check 500;
BA_ "GenSigSendType" SG_ 540 FCAM_FCW_check 2;
BA_ "InvalidValue" SG_ 540 FCAM_FCW_warning "3h";
BA_ "GenSigTimeoutTime_ALL" SG_ 540 FCAM_FCW_warning 500;
BA_ "GenSigSendType" SG_ 540 FCAM_FCW_warning 2;
BA_ "GenSigSendType" SG_ 540 FCAM_CV_AEB_Alert 2;
BA_ "GenSigSendType" SG_ 540 FCAM_CV_FCW_Alert 2;
BA_ "GenSigSendType" SG_ 540 FCAM_CV_PartialAEB_Alert 2;
BA_ "GenSigSendType" SG_ 540 FCAM_CV_PreFill_Alert 2;
BA_ "GenSigSendType" SG_ 540 FCAM_VD_AEB_Alert 2;
BA_ "GenSigSendType" SG_ 540 FCAM_VD_DBS_Alert 2;
BA_ "GenSigSendType" SG_ 540 FCAM_VD_EGOTAP_AEB_Alert 2;
BA_ "GenSigSendType" SG_ 540 FCAM_VD_FCW_Alert 2;
BA_ "GenSigSendType" SG_ 540 FCAM_VD_HeadOn_AEB_Alert 2;
BA_ "GenSigSendType" SG_ 540 FCAM_VD_PartialAEB_Alert 2;
BA_ "GenSigSendType" SG_ 540 FCAM_VD_Prefill_Alert 2;
BA_ "GenSigSendType" SG_ 540 FCAM_VRU_AEB_Alert 2;
BA_ "GenSigSendType" SG_ 540 FCAM_VRU_FCW_Alert 2;
BA_ "GenSigSendType" SG_ 540 FCAM_VRU_PreFill_Alert 2;
BA_ "GenSigSendType" SG_ 540 FCAM_Fusion_TTC 2;
BA_ "GenSigSendType" SG_ 540 FCAM_AB_TTC 2;
BA_ "GenSigSendType" SG_ 540 FCAM_AEB_Trigger_Source 2;
BA_ "GenSigSendType" SG_ 540 FCAM_FCW_Trigger_Source 2;
BA_ "InvalidValue" SG_ 540 FCAM_AEB_BrakeReq_Source "7h";
BA_ "GenSigTimeoutTime_ALL" SG_ 540 FCAM_AEB_BrakeReq_Source 1000;
BA_ "GenSigSendType" SG_ 540 FCAM_AEB_BrakeReq_Source 2;
BA_ "GenSigTimeoutTime_ALL" SG_ 763 Tsync_Message_CRC 5000;
BA_ "InvalidValue" SG_ 763 Tsync_Message_ALV "Fh";
BA_ "GenSigTimeoutTime_ALL" SG_ 763 Tsync_Message_ALV 5000;
BA_ "GenSigTimeoutTime_ALL" SG_ 763 Tsync_Message_Time_Domain_ID 5000;
BA_ "GenSigTimeoutTime_ALL" SG_ 763 Tsync_Message_FUP_Reserved 5000;
BA_ "GenSigTimeoutTime_ALL" SG_ 763 Tsync_Message_FUP_SGW 5000;
BA_ "GenSigTimeoutTime_ALL" SG_ 763 Tsync_Message_FUP_OVS 5000;
BA_ "GenSigStartValue" SG_ 763 Tsync_Message_Type 32;
BA_ "GenSigTimeoutTime_ALL" SG_ 763 Tsync_Message_Type 5000;
BA_ "GenSigTimeoutTime_ALL" SG_ 763 Tsync_Message_SYNC_FUP_SyncTimeS 5000;
BA_ "SystemSignalLongSymbol" SG_ 763 Tsync_Message_SYNC_FUP_SyncTimeS "Tsync_Message_SYNC_FUP_SyncTimeSec";
BA_ "InvalidValue" SG_ 833 ALIVE_FCAM_Camera_Perception "Fh";
BA_ "InvalidValue" SG_ 833 FCAM_OBJ01_Class "7h";
BA_ "GenSigTimeoutTime_ALL" SG_ 833 FCAM_OBJ01_Class 500;
BA_ "InvalidValue" SG_ 833 FCAM_OBJ01_LgtDis "3FFFh";
BA_ "GenSigStartValue" SG_ 833 FCAM_OBJ01_LgtDis 400;
BA_ "GenSigTimeoutTime_ALL" SG_ 833 FCAM_OBJ01_LgtDis 500;
BA_ "InvalidValue" SG_ 833 FCAM_OBJ01_ID "FFh";
BA_ "GenSigTimeoutTime_ALL" SG_ 833 FCAM_OBJ01_ID 500;
BA_ "GenSigTimeoutTime_ALL" SG_ 833 FCAM_OBJ01_LatDis 500;
BA_ "InvalidValue" SG_ 833 FCAM_OBJ02_Class "7h";
BA_ "GenSigTimeoutTime_ALL" SG_ 833 FCAM_OBJ02_Class 500;
BA_ "InvalidValue" SG_ 833 FCAM_OBJ02_LgtDis "3FFh";
BA_ "GenSigStartValue" SG_ 833 FCAM_OBJ02_LgtDis 400;
BA_ "GenSigTimeoutTime_ALL" SG_ 833 FCAM_OBJ02_LgtDis 500;
BA_ "InvalidValue" SG_ 833 FCAM_OBJ02_ID "FFh";
BA_ "GenSigTimeoutTime_ALL" SG_ 833 FCAM_OBJ02_ID 500;
BA_ "InvalidValue" SG_ 833 FCAM_OBJ02_LatDis "3FFh";
BA_ "GenSigTimeoutTime_ALL" SG_ 833 FCAM_OBJ02_LatDis 500;
BA_ "InvalidValue" SG_ 833 FCAM_OBJ03_Class "7h";
BA_ "GenSigTimeoutTime_ALL" SG_ 833 FCAM_OBJ03_Class 500;
BA_ "InvalidValue" SG_ 833 FCAM_OBJ03_LgtDis "3FFh";
BA_ "GenSigStartValue" SG_ 833 FCAM_OBJ03_LgtDis 400;
BA_ "GenSigTimeoutTime_ALL" SG_ 833 FCAM_OBJ03_LgtDis 500;
BA_ "InvalidValue" SG_ 833 FCAM_OBJ03_ID "FFh";
BA_ "GenSigTimeoutTime_ALL" SG_ 833 FCAM_OBJ03_ID 500;
BA_ "InvalidValue" SG_ 833 FCAM_OBJ03_LatDis "3FFh";
BA_ "GenSigTimeoutTime_ALL" SG_ 833 FCAM_OBJ03_LatDis 500;
BA_ "InvalidValue" SG_ 833 FCAM_OBJ04_Class "7h";
BA_ "GenSigTimeoutTime_ALL" SG_ 833 FCAM_OBJ04_Class 500;
BA_ "InvalidValue" SG_ 833 FCAM_OBJ04_LgtDis "3FFFh";
BA_ "GenSigStartValue" SG_ 833 FCAM_OBJ04_LgtDis 400;
BA_ "GenSigTimeoutTime_ALL" SG_ 833 FCAM_OBJ04_LgtDis 500;
BA_ "InvalidValue" SG_ 833 FCAM_OBJ04_ID "FFh";
BA_ "GenSigTimeoutTime_ALL" SG_ 833 FCAM_OBJ04_ID 500;
BA_ "GenSigTimeoutTime_ALL" SG_ 833 FCAM_OBJ04_LatDis 500;
BA_ "InvalidValue" SG_ 833 FCAM_OBJ05_Class "7h";
BA_ "GenSigTimeoutTime_ALL" SG_ 833 FCAM_OBJ05_Class 500;
BA_ "InvalidValue" SG_ 833 FCAM_OBJ05_LgtDis "3FFFh";
BA_ "GenSigStartValue" SG_ 833 FCAM_OBJ05_LgtDis 400;
BA_ "GenSigTimeoutTime_ALL" SG_ 833 FCAM_OBJ05_LgtDis 500;
BA_ "InvalidValue" SG_ 833 FCAM_OBJ05_ID "FFh";
BA_ "GenSigTimeoutTime_ALL" SG_ 833 FCAM_OBJ05_ID 500;
BA_ "GenSigTimeoutTime_ALL" SG_ 833 FCAM_OBJ05_LatDis 500;
BA_ "InvalidValue" SG_ 833 FCAM_OBJ06_Class "7h";
BA_ "GenSigTimeoutTime_ALL" SG_ 833 FCAM_OBJ06_Class 500;
BA_ "InvalidValue" SG_ 833 FCAM_OBJ06_LgtDis "3FFFh";
BA_ "GenSigStartValue" SG_ 833 FCAM_OBJ06_LgtDis 400;
BA_ "GenSigTimeoutTime_ALL" SG_ 833 FCAM_OBJ06_LgtDis 500;
BA_ "InvalidValue" SG_ 833 FCAM_OBJ06_ID "FFh";
BA_ "GenSigTimeoutTime_ALL" SG_ 833 FCAM_OBJ06_ID 500;
BA_ "InvalidValue" SG_ 833 FCAM_OBJ06_LatDis "3FFFh";
BA_ "GenSigTimeoutTime_ALL" SG_ 833 FCAM_OBJ06_LatDis 500;
BA_ "InvalidValue" SG_ 834 ALIVE_FCAM_Camera_Perception_1 "Fh";
BA_ "GenSigTimeoutTime_ALL" SG_ 834 FCAM_LA_veh_pos_right 800;
BA_ "GenSigSendType" SG_ 834 FCAM_LA_veh_pos_right 2;
BA_ "GenSigTimeoutTime_ALL" SG_ 834 FCAM_LA_veh_pos_left 800;
BA_ "GenSigSendType" SG_ 834 FCAM_LA_veh_pos_left 2;
BA_ "InvalidValue" SG_ 835 ALIVE_FCAM_Camera_Perception_2 "Fh";
BA_ "GenSigTimeoutTime_ALL" SG_ 835 FCAM_L1_Line_ExistProbability 500;
BA_ "InvalidValue" SG_ 836 ALIVE_FCAM_Camera_Perception_3 "Fh";
BA_ "GenSigStartValue" SG_ 836 FCAM_OBJ09_LgtDis 1200;
BA_ "InvalidValue" SG_ 836 FCAM_OBJ09_ID "FFh";
BA_ "GenSigStartValue" SG_ 836 FCAM_OBJ09_LatDis 4000;
BA_ "GenSigStartValue" SG_ 836 FCAM_OBJ09_Heading 179;
BA_ "GenSigStartValue" SG_ 836 FCAM_OBJ10_LgtDis 1200;
BA_ "GenSigStartValue" SG_ 836 FCAM_OBJ10_LatDis 4000;
BA_ "GenSigStartValue" SG_ 836 FCAM_OBJ10_Heading 179;
BA_ "GenSigStartValue" SG_ 836 FCAM_OBJ11_LgtDis 1200;
BA_ "GenSigStartValue" SG_ 836 FCAM_OBJ11_LatDis 4000;
BA_ "GenSigStartValue" SG_ 836 FCAM_OBJ11_Heading 179;
BA_ "GenSigStartValue" SG_ 836 FCAM_OBJ12_LgtDis 1200;
BA_ "GenSigStartValue" SG_ 836 FCAM_OBJ12_LatDis 4000;
BA_ "GenSigStartValue" SG_ 836 FCAM_OBJ12_Heading 179;
BA_ "GenSigStartValue" SG_ 836 FCAM_OBJ13_LgtDis 1200;
BA_ "GenSigStartValue" SG_ 836 FCAM_OBJ13_LatDis 4000;
BA_ "GenSigStartValue" SG_ 836 FCAM_OBJ13_Heading 179;
BA_ "GenSigStartValue" SG_ 836 FCAM_OBJ14_LgtDis 1200;
BA_ "GenSigStartValue" SG_ 836 FCAM_OBJ14_LatDis 4000;
BA_ "GenSigStartValue" SG_ 836 FCAM_OBJ14_Heading 179;
BA_ "InvalidValue" SG_ 837 ALIVE_FCAM_Camera_Perception_4 "Fh";
BA_ "GenSigStartValue" SG_ 837 FCAM_OBJ15_LgtDis 1200;
BA_ "GenSigStartValue" SG_ 837 FCAM_OBJ15_LatDis 4000;
BA_ "GenSigStartValue" SG_ 837 FCAM_OBJ15_Heading 179;
BA_ "GenSigStartValue" SG_ 837 FCAM_OBJ16_LgtDis 1200;
BA_ "GenSigStartValue" SG_ 837 FCAM_OBJ16_LatDis 4000;
BA_ "GenSigStartValue" SG_ 837 FCAM_OBJ16_Heading 179;
BA_ "GenSigStartValue" SG_ 837 FCAM_OBJ17_LgtDis 1200;
BA_ "GenSigStartValue" SG_ 837 FCAM_OBJ17_LatDis 4000;
BA_ "GenSigStartValue" SG_ 837 FCAM_OBJ17_Heading 179;
BA_ "GenSigStartValue" SG_ 837 FCAM_OBJ18_LgtDis 1200;
BA_ "GenSigStartValue" SG_ 837 FCAM_OBJ18_LatDis 4000;
BA_ "GenSigStartValue" SG_ 837 FCAM_OBJ18_Heading 179;
BA_ "GenSigStartValue" SG_ 837 FCAM_OBJ19_LgtDis 1200;
BA_ "GenSigStartValue" SG_ 837 FCAM_OBJ19_LatDis 4000;
BA_ "GenSigStartValue" SG_ 837 FCAM_OBJ19_Heading 179;
BA_ "GenSigStartValue" SG_ 837 FCAM_OBJ20_LgtDis 1200;
BA_ "GenSigStartValue" SG_ 837 FCAM_OBJ20_LatDis 4000;
BA_ "GenSigStartValue" SG_ 837 FCAM_OBJ20_Heading 179;
BA_ "InvalidValue" SG_ 839 ALIVE_FCAM_Camera_Perception_5 "Fh";
BA_ "GenSigStartValue" SG_ 839 FCAM_OBJ21_LgtDis 1200;
BA_ "GenSigStartValue" SG_ 839 FCAM_OBJ21_LatDis 4000;
BA_ "GenSigStartValue" SG_ 839 FCAM_OBJ21_Heading 179;
BA_ "GenSigStartValue" SG_ 839 FCAM_OBJ22_LgtDis 1200;
BA_ "GenSigStartValue" SG_ 839 FCAM_OBJ22_LatDis 4000;
BA_ "GenSigStartValue" SG_ 839 FCAM_OBJ22_Heading 179;
BA_ "GenSigStartValue" SG_ 839 FCAM_OBJ23_LgtDis 1200;
BA_ "GenSigStartValue" SG_ 839 FCAM_OBJ23_LatDis 4000;
BA_ "GenSigStartValue" SG_ 839 FCAM_OBJ23_Heading 179;
BA_ "GenSigStartValue" SG_ 839 FCAM_OBJ24_LgtDis 1200;
BA_ "GenSigStartValue" SG_ 839 FCAM_OBJ24_LatDis 4000;
BA_ "GenSigStartValue" SG_ 839 FCAM_OBJ24_Heading 179;
BA_ "GenSigStartValue" SG_ 839 FCAM_OBJ25_LgtDis 1200;
BA_ "GenSigStartValue" SG_ 839 FCAM_OBJ25_LatDis 4000;
BA_ "GenSigStartValue" SG_ 839 FCAM_OBJ25_Heading 179;
BA_ "GenSigStartValue" SG_ 839 FCAM_OBJ26_LgtDis 1200;
BA_ "GenSigStartValue" SG_ 839 FCAM_OBJ26_LatDis 4000;
BA_ "GenSigStartValue" SG_ 839 FCAM_OBJ26_Heading 179;
BA_ "InvalidValue" SG_ 840 ALIVE_FCAM_Camera_Perception_6 "Fh";
BA_ "GenSigStartValue" SG_ 840 FCAM_OBJ27_LgtDis 1200;
BA_ "GenSigStartValue" SG_ 840 FCAM_OBJ27_LatDis 4000;
BA_ "GenSigStartValue" SG_ 840 FCAM_OBJ27_Heading 179;
BA_ "GenSigStartValue" SG_ 840 FCAM_OBJ28_LgtDis 1200;
BA_ "GenSigStartValue" SG_ 840 FCAM_OBJ28_LatDis 4000;
BA_ "GenSigStartValue" SG_ 840 FCAM_OBJ28_Heading 179;
BA_ "GenSigStartValue" SG_ 840 FCAM_OBJ29_LgtDis 1200;
BA_ "GenSigStartValue" SG_ 840 FCAM_OBJ29_LatDis 4000;
BA_ "GenSigStartValue" SG_ 840 FCAM_OBJ29_Heading 179;
BA_ "GenSigStartValue" SG_ 840 FCAM_OBJ30_LgtDis 1200;
BA_ "GenSigStartValue" SG_ 840 FCAM_OBJ30_LatDis 4000;
BA_ "GenSigStartValue" SG_ 840 FCAM_OBJ30_Heading 179;
BA_ "GenSigStartValue" SG_ 840 FCAM_OBJ31_LgtDis 1200;
BA_ "GenSigStartValue" SG_ 840 FCAM_OBJ31_LatDis 4000;
BA_ "GenSigStartValue" SG_ 840 FCAM_OBJ31_Heading 179;
BA_ "GenSigStartValue" SG_ 840 FCAM_OBJ32_LgtDis 1200;
BA_ "GenSigStartValue" SG_ 840 FCAM_OBJ32_LatDis 4000;
BA_ "GenSigStartValue" SG_ 840 FCAM_OBJ32_Heading 179;
BA_ "GenSigTimeoutTime_ALL" SG_ 850 CRC_FCAM_ADAS_BODY 500;
BA_ "InvalidValue" SG_ 850 ALIVE_FCAM_ADAS_BODY "Fh";
BA_ "GenSigTimeoutTime_ALL" SG_ 850 ALIVE_FCAM_ADAS_BODY 500;
BA_ "InvalidValue" SG_ 850 FCAM_AHB_sens_Feed "3h";
BA_ "GenSigTimeoutTime_ALL" SG_ 850 FCAM_AHB_sens_Feed 500;
BA_ "GenSigSendType" SG_ 850 FCAM_AHB_sens_Feed 2;
BA_ "GenSigTimeoutTime_ALL" SG_ 850 FCAM_AHB_Mode_Feed 500;
BA_ "GenSigSendType" SG_ 850 FCAM_AHB_Mode_Feed 2;
BA_ "InvalidValue" SG_ 850 FCAM_AHB_check "3h";
BA_ "GenSigTimeoutTime_ALL" SG_ 850 FCAM_AHB_check 500;
BA_ "GenSigSendType" SG_ 850 FCAM_AHB_check 2;
BA_ "InvalidValue" SG_ 850 FCAM_AHB_state "3h";
BA_ "GenSigTimeoutTime_ALL" SG_ 850 FCAM_AHB_state 500;
BA_ "GenSigSendType" SG_ 850 FCAM_AHB_state 2;
BA_ "InvalidValue" SG_ 850 FCAM_AHB_RBPos "7h";
BA_ "GenSigTimeoutTime_ALL" SG_ 850 FCAM_AHB_RBPos 500;
BA_ "GenSigSendType" SG_ 850 FCAM_AHB_RBPos 2;
BA_ "InvalidValue" SG_ 850 FCAM_AHB_LBPos "7h";
BA_ "GenSigTimeoutTime_ALL" SG_ 850 FCAM_AHB_LBPos 500;
BA_ "GenSigSendType" SG_ 850 FCAM_AHB_LBPos 2;
BA_ "GenSigTimeoutTime_ALL" SG_ 850 FCAM_DashCam_Status 500;
BA_ "GenSigSendType" SG_ 850 FCAM_DashCam_Status 2;
BA_ "GenSigTimeoutTime_ALL" SG_ 850 FCAM_Body_HeadlightReq 500;
BA_ "GenSigSendType" SG_ 850 FCAM_Body_HeadlightReq 2;
BA_ "GenSigTimeoutTime_ALL" SG_ 850 FCAM_Body_FoldMirrorReq 500;
BA_ "GenSigSendType" SG_ 850 FCAM_Body_FoldMirrorReq 2;
BA_ "GenSigTimeoutTime_ALL" SG_ 850 FCAM_Body_Status 500;
BA_ "GenSigSendType" SG_ 850 FCAM_Body_Status 2;
BA_ "GenSigTimeoutTime_ALL" SG_ 850 FCAM_Body_IndicatorlightReq 500;
BA_ "GenSigSendType" SG_ 850 FCAM_Body_IndicatorlightReq 2;
BA_ "GenSigTimeoutTime_ALL" SG_ 851 CRC_FCAM_CMP_ACC 500;
BA_ "InvalidValue" SG_ 851 ALIVE_FCAM_CMP_ACC "Fh";
BA_ "GenSigTimeoutTime_ALL" SG_ 851 ALIVE_FCAM_CMP_ACC 500;
BA_ "GenSigTimeoutTime_ALL" SG_ 851 FCAM_ACC_ObjDetec 500;
BA_ "GenSigSendType" SG_ 851 FCAM_ACC_ObjDetec 2;
BA_ "InvalidValue" SG_ 851 FCAM_ISA_check "3h";
BA_ "GenSigTimeoutTime_ALL" SG_ 851 FCAM_ISA_check 500;
BA_ "GenSigSendType" SG_ 851 FCAM_ISA_check 2;
BA_ "GenSigTimeoutTime_ALL" SG_ 851 FCAM_ISA_Mode_SW_Feed 500;
BA_ "GenSigSendType" SG_ 851 FCAM_ISA_Mode_SW_Feed 2;
BA_ "InvalidValue" SG_ 851 FCAM_TagSpeed_ICON_Feed "7h";
BA_ "GenSigTimeoutTime_ALL" SG_ 851 FCAM_TagSpeed_ICON_Feed 500;
BA_ "GenSigSendType" SG_ 851 FCAM_TagSpeed_ICON_Feed 2;
BA_ "InvalidValue" SG_ 851 FCAM_ISA_PopUp_Feed "Fh";
BA_ "GenSigTimeoutTime_ALL" SG_ 851 FCAM_ISA_PopUp_Feed 500;
BA_ "GenSigSendType" SG_ 851 FCAM_ISA_PopUp_Feed 2;
BA_ "GenSigTimeoutTime_ALL" SG_ 851 FCAM_ISA_Btn_Feed 500;
BA_ "GenSigSendType" SG_ 851 FCAM_ISA_Btn_Feed 2;
BA_ "GenSigTimeoutTime_ALL" SG_ 851 FCAM_ACC_DistSet_upper_Feed 500;
BA_ "GenSigSendType" SG_ 851 FCAM_ACC_DistSet_upper_Feed 2;
BA_ "InvalidValue" SG_ 851 FCAM_ACC_TimeGapSet "7h";
BA_ "GenSigTimeoutTime_ALL" SG_ 851 FCAM_ACC_TimeGapSet 500;
BA_ "GenSigSendType" SG_ 851 FCAM_ACC_TimeGapSet 2;
BA_ "GenSigTimeoutTime_ALL" SG_ 851 FCAM_ACC_State 500;
BA_ "GenSigSendType" SG_ 851 FCAM_ACC_State 2;
BA_ "InvalidValue" SG_ 851 FCAM_ACC_TagSpeed "FFh";
BA_ "GenSigTimeoutTime_ALL" SG_ 851 FCAM_ACC_TagSpeed 500;
BA_ "GenSigSendType" SG_ 851 FCAM_ACC_TagSpeed 2;
BA_ "InvalidValue" SG_ 851 FCAM_ACC_PopUp_Feed "Fh";
BA_ "GenSigTimeoutTime_ALL" SG_ 851 FCAM_ACC_PopUp_Feed 500;
BA_ "GenSigSendType" SG_ 851 FCAM_ACC_PopUp_Feed 2;
BA_ "InvalidValue" SG_ 851 FCAM_ACC_check "3h";
BA_ "GenSigTimeoutTime_ALL" SG_ 851 FCAM_ACC_check 500;
BA_ "GenSigSendType" SG_ 851 FCAM_ACC_check 2;
BA_ "GenSigTimeoutTime_ALL" SG_ 851 FCAM_ISA_ICON_Feed 500;
BA_ "GenSigSendType" SG_ 851 FCAM_ISA_ICON_Feed 2;
BA_ "GenSigTimeoutTime_ALL" SG_ 851 FCAM_ACC_DistSet_lower_Feed 500;
BA_ "GenSigSendType" SG_ 851 FCAM_ACC_DistSet_lower_Feed 2;
BA_ "GenSigTimeoutTime_ALL" SG_ 851 FCAM_ACC_SpdSet_upper_Feed 500;
BA_ "GenSigSendType" SG_ 851 FCAM_ACC_SpdSet_upper_Feed 2;
BA_ "GenSigTimeoutTime_ALL" SG_ 851 FCAM_ACC_SpdSet_lower_Feed 500;
BA_ "GenSigSendType" SG_ 851 FCAM_ACC_SpdSet_lower_Feed 2;
BA_ "GenSigTimeoutTime_ALL" SG_ 851 FCAM_ACC_On_Feed 500;
BA_ "GenSigSendType" SG_ 851 FCAM_ACC_On_Feed 2;
BA_ "GenSigTimeoutTime_ALL" SG_ 851 FCAM_ACC_Set_Feed 500;
BA_ "GenSigSendType" SG_ 851 FCAM_ACC_Set_Feed 2;
BA_ "GenSigTimeoutTime_ALL" SG_ 851 FCAM_ACC_CnlBtn_Feed 500;
BA_ "GenSigSendType" SG_ 851 FCAM_ACC_CnlBtn_Feed 2;
BA_ "GenSigTimeoutTime_ALL" SG_ 851 FCAM_ACC_Res_Feed 500;
BA_ "GenSigSendType" SG_ 851 FCAM_ACC_Res_Feed 2;
BA_ "InvalidValue" SG_ 851 FCAM_ACC_ICON_Feed "7h";
BA_ "GenSigTimeoutTime_ALL" SG_ 851 FCAM_ACC_ICON_Feed 500;
BA_ "GenSigSendType" SG_ 851 FCAM_ACC_ICON_Feed 2;
BA_ "InvalidValue" SG_ 851 FCAM_ISA_Status "7h";
BA_ "GenSigTimeoutTime_ALL" SG_ 851 FCAM_ISA_Status 500;
BA_ "GenSigSendType" SG_ 851 FCAM_ISA_Status 2;
BA_ "GenSigTimeoutTime_ALL" SG_ 851 FCAM_ACC_DriveOff 500;
BA_ "GenSigSendType" SG_ 851 FCAM_ACC_DriveOff 2;
BA_ "InvalidValue" SG_ 1115 FCAM_HOD_state_requesting "3h";
BA_ "GenSigTimeoutTime_ALL" SG_ 1115 FCAM_HOD_state_requesting 2500;
VAL_ 599 MHU_RVC_Request 0 "Off" 1 "On" 2 "Reserved" 3 "Signal invalid" ;
VAL_ 601 MHU_Sentry_Mode_Request 0 "Off" 1 "On" 2 "Reserved" 3 "Signal invalid" ;
VAL_ 601 MHU_Set_Sentry_Mode_Alarm 0 "Alarm_OFF" 1 "Alarm_ON" 2 "Reserved" 3 "Invalid" ;
VAL_ 601 MHU_SET_SentryActivation 0 "Deactivate" 1 "Activate" 2 "Reserved" 3 "Invalid" ;
VAL_ 672 DrvSeatHeatSet 0 "Unavailable" 1 "One" 2 "Two" 3 "Three" 4 "Unused and Reserved" 5 "Unused and Reserved" 6 "Unused and Reserved" 7 "OFF" ;
VAL_ 672 PassSeatHeatSet 0 "Unavailable" 1 "One" 2 "Two" 3 "Three" 4 "Unused and Reserved" 5 "Unused and Reserved" 6 "Unused and Reserved" 7 "OFF" ;
VAL_ 672 Rear1DrvSeatHeatSet 0 "Unavailable" 1 "One" 2 "Two" 3 "Three" 4 "Unused and Reserved" 5 "Unused and Reserved" 6 "Unused and Reserved" 7 "OFF" ;
VAL_ 672 Rear1PassSeatHeatSet 0 "Unavailable" 1 "One" 2 "Two" 3 "Three" 4 "Unused and Reserved" 5 "Unused and Reserved" 6 "Unused and Reserved" 7 "OFF" ;
VAL_ 672 Rear2DrvSeatHeatSet 0 "Unavailable" 1 "One" 2 "Two" 3 "Three" 4 "Unused and Reserved" 5 "Unused and Reserved" 6 "Unused and Reserved" 7 "OFF" ;
VAL_ 672 Rear2PassSeatHeatSet 0 "Unavailable" 1 "One" 2 "Two" 3 "Three" 4 "Unused and Reserved" 5 "Unused and Reserved" 6 "Unused and Reserved" 7 "OFF" ;
VAL_ 672 CVC_FLSeatVent_Req 0 "OFF" 1 "Level 1" 2 "Level 2" 3 "Level 3" 4 "Reserved" 5 "Reserved" 6 "Reserved" 7 "Invalid" ;
VAL_ 672 CVC_FRSeatVent_Req 0 "OFF" 1 "Level 1" 2 "Level 2" 3 "Level 3" 4 "Reserved" 5 "Reserved" 6 "Reserved" 7 "Invalid" ;
VAL_ 672 CVC_RLSeatVent_Req 0 "OFF" 1 "Level 1" 2 "Level 2" 3 "Level 3" 4 "Reserved" 5 "Reserved" 6 "Reserved" 7 "Invalid" ;
VAL_ 672 CVC_RRSeatVent_Req 0 "OFF" 1 "Level 1" 2 "Level 2" 3 "Level 3" 4 "Reserved" 5 "Reserved" 6 "Reserved" 7 "Invalid" ;
VAL_ 673 DrvSeatMsgStrLvlSet 0 "OFF" 1 "Initial value" 2 "Level 1(Weak)" 3 "Level 2(General)" 4 "Level 3(Strong)" 5 "Reserved" 6 "Reserved" 7 "Invalid" ;
VAL_ 673 PassSeatMsgStrLvlSet 0 "OFF" 1 "Initial value" 2 "Level 1(Weak)" 3 "Level 2(General)" 4 "Level 3(Strong)" 5 "Reserved" 6 "Reserved" 7 "Invalid" ;
VAL_ 673 Rear1DrvSeatMsgStrLvlSet 0 "OFF" 1 "Initial value" 2 "Level 1(Weak)" 3 "Level 2(General)" 4 "Level 3(Strong)" 5 "Not used" 6 "Not used" 7 "Not used" ;
VAL_ 673 Rear1PassSeatMsgStrLvlSet 0 "OFF" 1 "Initial value" 2 "Level 1(Weak)" 3 "Level 2(General)" 4 "Level 3(Strong)" 5 "Not used" 6 "Not used" 7 "Not used" ;
VAL_ 673 DrvSeatMsgModeSet 0 "OFF" 1 "Wave Mode" 2 "Cat Paw Mode" 3 "Cross Mode" 4 "Relieve Mode" 5 "Jump Mode" 6 "Reserved" 7 "Invalid" ;
VAL_ 673 PassSeatMsgModeSet 0 "OFF" 1 "Wave Mode" 2 "Cat Paw Mode" 3 "Cross Mode" 4 "Relieve Mode" 5 "Jump Mode" 6 "Reserved" 7 "Invalid" ;
VAL_ 673 Rear1DrvSeatMsgModeSet 0 "OFF" 1 "Wave Mode" 2 "Cat Paw Mode" 3 "Cross Mode" 4 "Relieve Mode" 5 "Jump Mode" 6 "Invalid" 7 "Not used" ;
VAL_ 673 Rear1PassSeatMsgModeSet 0 "OFF" 1 "Wave mode" 2 "Cat Paw Mode" 3 "Cross Mode" 4 "Relieve Mode" 5 "Jump Mode" 6 "invalid" 7 "Not used" ;
VAL_ 753 MHU_STAT_AirbagWarnLamp 0 "Lamp off" 1 "Lamp on" 2 "Lamp failure" 3 "Signal invalid" ;
VAL_ 776 MHU_CPD_Setting 0 "Enable" 1 "Disable" 2 "Child Mode" 3 "Delay CPD" 4 "Reserved" 5 "Reserved" 6 "Reserved" 7 "Reserved" ;
VAL_ 776 MHU_CPD_Confirmation_On_HMI 0 "No confirmation" 1 "User confirmation" 2 "Reserved" 3 "Reserved" 4 "Reserved" 5 "Reserved" 6 "Reserved" 7 "Reserved" ;
VAL_ 788 MHU_RAEB_check 0 "Available" 1 "Degraded" 2 "Temporarily not available" 3 "Permanently not available" 4 "RAEB Inhibited" 5 "Reserved" 6 "Initializing" 7 "Invalid" ;
VAL_ 788 MHU_RAEB_Warning 0 "No warning" 1 "Braking" 2 "Postfeedback" 3 "Display Prompt to turn OFF RAEB" 4 "Reserved" 5 "Reserved" 6 "Reserved" 7 "Invalid" ;
VAL_ 788 MHU_RAEB_State 0 "Off" 1 "Inactive" 2 "Ready" 3 "PreFill" 4 "AEB Active" 5 "Post-RAEB Brake" 6 "Error" 7 "Invalid" ;
VAL_ 788 MHU_RAEB_BrakeCommand 0 "No Request" 1 "Prefill Brake Request" 2 "Emergency brake Request" 3 "Signal invalid" ;
VAL_ 788 MHU_RAEB_Available 0 "Not Support" 1 "Not Available" 2 "Available" 3 "Invalid" ;
VAL_ 788 MHU_RAEB_FuncActive 0 "Not Active" 1 "Active" ;
VAL_ 788 MHU_RAEB_Mode_Feed 0 "OFF" 1 "ON" 2 "Reserved" 3 "Invalid" ;
VAL_ 788 MHU_RAEB_BrakeType 0 "No Request" 1 "Comfort Brake" 2 "Normal Emergency Brake" 3 "Emergency Brake" ;
VAL_ 788 MHU_RAEB_PullEPBOpt 0 "No Request" 1 "Request" ;
VAL_ 788 MHU_RAEB_BrakeReq_Source 0 "None" 1 "RAEB request" 2 "Rear ACPE Request" 3 "RCTB - by Radar Rear crossing obj" 4 "Reserved" 5 "Reserved" 6 "Reserved" 7 "Invalid" ;
VAL_ 791 MHU_SVM_ShowAVMReq 0 "No Request" 1 "Show SVM Req" 2 "Hide SVM Req" 3 "Reserved" 4 "Reserved" 5 "Reserved" 6 "Reserved" 7 "Invalid" ;
VAL_ 791 MHU_SVM_ViewRequest 0 "No Request" 1 "Front View" 2 "Front Junction View" 3 "Rear View" 4 "Rear Junction View" 5 "3D View'" 6 "3D - Left Tire View" 7 "3D- Right Tire View" 8 "3D- Frunk View" 9 "3D- Trunk View" 10 "3D- Globe View" 31 "Invalid" ;
VAL_ 791 MHU_SVM_BlindspotView_Feed 0 "OFF" 1 "'Left Blindspot camera showing" 2 "Right Blindspot camera showing" 3 "Invalid" ;
VAL_ 801 DeadReckoning_Status 0 "INVALID" 1 "ALIGNING" 3 "SOLUTION_GOOD" ;
VAL_ 802 Fix_Type 0 "No_Fix" 1 "SPP" 4 "RTK_Fixed" 5 "RTK_Float" ;
VAL_ 802 Fix_Quality 0 "Invalid" 5 "Excellent" ;
VAL_ 804 Steering_HeatingControl 0 "Disable" 1 "Enable" ;
VAL_ 1043 MHU_SetSuspensionMode 0 "Low" 1 "Standard" 2 "High" 3 "Auto" 7 "Inactive" ;
VAL_ 1043 MHU_SetCDC_EasyAccess 0 "ON" 1 "OFF" 2 "reserved" 3 "Invalid" ;
VAL_ 1043 MHU_Set_CDC_Mode 0 "Comfort" 1 "Standard" 2 "Sport" 3 "Inactive" ;
VAL_ 1043 MHU_Set_EAS_CDC_SystemWorkMode 0 "Normal" 1 "Transportation mode" 2 "Maintenance mode" 3 "Reserved" ;
VAL_ 1043 MHU_Set_Easy_Load_Mode 0 "Inactive" 1 "OFF" 2 "ON" 3 "Reserved" ;
VAL_ 1043 MHU_Set_Lift_Jack_Mode 0 "No Lift and Jack" 1 "AutoLift Mode" 2 "AutoJack Mode" 3 "invalid" ;
VAL_ 1045 MHU_ADCU_AutPrkgSlotSel 0 "No Slot" 1 "Left ID1" 2 "Left ID2" 3 "Left ID3" 4 "Right ID1" 5 "Right ID2" 6 "Right ID3" 7 "Reserved" ;
VAL_ 1045 MHU_ADCU_DirSel 0 "No_ParkSlot" 1 "FrntLeCrss" 2 "FrntLePrl" 3 "Frnt" 4 "FrntRiCrss" 5 "FrntRiPrl" 6 "Bck" 7 "BckLe" 8 "BckRi" ;
VAL_ 1047 CVC_MNF_AutoStartReq 0 "No command" 1 "Disable" 2 "Enable" 3 "Signal Invalid" ;
VAL_ 1047 CVC_MNF_ModeReq 0 "No command" 1 "OFF" 2 "Cooling" 3 "Heating" ;
VAL_ 1047 CVC_MNF_DoorLock_Req 0 "No command" 1 "Open" ;
VAL_ 1047 CVC_MNF_SpecialModeReq 0 "No command" 1 "Iced" 2 "Preservation" 3 "Warm milk" 4 "Reserved" 5 "Reserved" 6 "Reserved" 7 "Reserved" ;
VAL_ 1050 MHU_SteeringWheel_EasyEntry 0 "ON" 1 "OFF" 2 "reserved" 3 "Invalid" ;
VAL_ 1050 MHU_SteeringWheel_Heater 0 "ON" 1 "OFF" 2 "reserved" 3 "Invalid" ;
VAL_ 1050 MHU_SteerElecAdj_Req 0 "No Request" 1 "Save" 2 "Restore memory location" 3 "Moving" ;
VAL_ 1058 MHU_STAT_Cluster 0 "OFF" 1 "ON" 2 "Reserved" 3 "Signal invalid" ;
VAL_ 1058 MHU_STAT_Infotainment 0 "OFF" 1 "ON" 2 "Reserved" 3 "Signal invalid" ;
VAL_ 1058 MHU_STAT_MileageUnit 0 "Mile" 1 "KM" 2 "Reserved" 3 "Signal invalid" ;
VAL_ 1058 MHU_STAT_PressureUnit 0 "Bar" 1 "Psi" 2 "Kpa" 3 "Signal invalid" ;
VAL_ 1058 MHU_STAT_TemperatureUnit 0 "Celcius" 1 "Fahrenheit" 2 "Reserved" 3 "Signal invalid" ;
VAL_ 1058 MHU_STAT_DateTimeFormat 0 "24H" 1 "12H" 2 "Reserved" 3 "Signal invalid" ;
VAL_ 1058 MHU_Operation_State 0 "Sleep - Low power mode" 1 "Standby/Screen OFF" 2 "Booting/Rebooting" 3 "Running" 4 "Standby/Fullscreen" 5 "OTA progess" 6 "Fault" 7 "Signal Invalid" ;
VAL_ 1058 MHU_STAT_Language 0 "Vietnamese" 1 "English" 2 "Spanish" 3 "French" 4 "German" 5 "Dutch" 6 "English (CANADA)" 7 "French (CANADA)" 8 "Russian" 9 "Spanish (Latin America)" 10 "Portuguese" 11 "Portuguese (Brasil)" 12 "Chinese, simplipied" 13 "Chinese, traditional" 14 "Mexican-Spanish" 15 "Bahasa Indonesian" 16 "Hindi" 17 "Arabic" 18 "Italian" 19 "Finnish" 20 "Lithuanian" 21 "Latvian" 22 "Estonian" 23 "Hungarian" 24 "Czech" 25 "Slovakian" 26 "Slovenian" 27 "Croatian" 28 "Bulgarian" 29 "Reserved" 30 "Reserved" 31 "Signal invalid" ;
VAL_ 1058 MHU_STAT_EnergyConsumptionUnit 0 "KWH/100KM" 1 "KM/KWH" 2 "Mile per KWH" 3 "KWH/100mil" 4 "Reserved" 5 "Reserved" 6 "Reserved" 7 "Signal invalid" ;
VAL_ 1058 MHU_STAT_BatLvlPopsetting 0 "20%" 1 "30%" 2 "40%" 3 "50%" 4 "60%" 5 "70%" 6 "Signal Invalid" ;
VAL_ 1058 MHU_STAT_DistToEmptyUnit 0 "%percentage" 1 "KM/Mi" 2 "Reserved" 3 "Signal Invalid" ;
VAL_ 1058 MHU_DCM_Status 0 "Normal" 1 "Fault" 2 "Reserved" ;
VAL_ 1092 MHU_RPParkingstartReq 0 "no request" 1 "request" ;
VAL_ 1092 MHU_RP_ParkOutModeConfirm 0 "No request" 1 "Perpendicular parking" 2 "parallel parking" 3 "Angled parking" ;
VAL_ 1092 MHU_RP_ParkOutDircnConfirm 0 "No request" 1 "left" 2 "right" ;
VAL_ 1092 MHU_RemoteconnectionSts 0 "Disconnect" 1 "Connect" ;
VAL_ 1092 MHU_RP_FuncMode 0 "No function" 1 "Parking in" 2 "parking out" 3 "drag parking" 4 "Straight in straight out" ;
VAL_ 1092 MHU_SMParkingstartReq 0 "no request" 1 "request" ;
VAL_ 1092 MHU_SMParkingControlReq 0 "no request" 1 "request" ;
VAL_ 1092 MHU_RP_RecoverParking 0 "no request" 1 "request" ;
VAL_ 1092 MHU_RPStraightParkingDir 0 "-" 1 "forward" 2 "back" ;
VAL_ 1092 MHU_SM_global_path_Status 0 "not available" 1 "available" 2 "Reserved" ;
VAL_ 1092 MHU_SM_QuitReq 0 "No request" 1 "request exit" 2 "request exit and flameout" ;
VAL_ 1092 MHU_RPParkingControlReq 0 "no request" 1 "request" ;
VAL_ 1092 MHU_RP_QuitReq 0 "no request" 1 "request exit" 2 "request exit and flameout" ;
VAL_ 1095 MHU_AVH_Sw 0 "No Action" 1 "ON" 2 "OFF" 3 "Reserved" ;
VAL_ 1095 MHU_TowingMode_Sw 0 "No Action" 1 "ON" 2 "OFF" 3 "Reserved" ;
VAL_ 1095 MHU_HDC_Switch 0 "OFF" 1 "ON" 3 "Signal Invalid" ;
VAL_ 1095 MHU_SET_WashMode 0 "Wash mode OFFt" 1 "Wash mode ON" 2 "Reserved" 3 "Signal Invalid" ;
VAL_ 1095 MHU_TowMode_Req 0 "Inactive" 1 "Active" 3 "Reserve" ;
VAL_ 1095 MHU_ESC_TCS_Switch 0 "Normal" 1 "Traction Mode OFF" 2 "ESC-OFF" 3 "Signal Invalid" ;
VAL_ 1095 MHU_V2LPowertrans_sts 0 "Enable" 1 "Disable" 2 "Signal invalid" ;
VAL_ 1116 MHU_SVM_FCamera_Fault 0 "No fault" 1 "Temp fault(clean fix)" 2 "Temp fault(Environment)" 3 "Permanent fault" ;
VAL_ 1116 MHU_SVM_LCamera_Fault 0 "No fault" 1 "Temp fault(clean fix)" 2 "Temp fault(Environment)" 3 "Permanent fault" ;
VAL_ 1116 MHU_SVM_RCamera_Fault 0 "No fault" 1 "Temp fault(clean fix)" 2 "Temp fault(Environment)" 3 "Permanent fault" ;
VAL_ 1116 MHU_SVM_RightCamera_Fault 0 "No fault" 1 "Temp fault(clean fix)" 2 "Temp fault(Environment)" 3 "Permanent fault" ;
VAL_ 1116 MHU_SETTING_DMSWarning 0 "OFF" 1 "Warning Only" 2 "Warning + Chime" 3 "Signal invalid" ;
VAL_ 1116 MHU_DMS_Status_feed 0 "Init" 1 "DMS ON" 2 "DMS OFF" 3 "Wearing mask" 4 "Wearing IR blocking glass" 5 "No face detected" 6 "Malfunction" 7 "Camera defected" 15 "Invalid" ;
VAL_ 1116 MHU_DMS_System_Status 0 "No failure" 1 "Failure" 2 "Degradation" 3 "Driver undetected" 7 "Invalid" ;
VAL_ 1120 MHU_ACPE_PowerCommand 0 "No Request" 1 "ACPE Armed-cut-off power" 2 "ACPE Armed-Limit power" 3 "ACPE intervene cut-off power" 4 "ACPE intervene limit power" 5 "ACPE Disengaging" 6 "Reserved" 7 "Invalid" ;
VAL_ 1120 MHU_ACPE_BrakeCommand 0 "No Request'" 1 "Front ACPE Brake request" 2 "Rear ACPE Brake Request" 3 "Invalid" ;
VAL_ 1120 MHU_ACPE_Available 0 "Not Support'" 1 "Not Available" 2 "Available" 3 "Invalid" ;
VAL_ 1120 MHU_ACPE_FuncActive 0 "Not Active" 1 "Active" ;
VAL_ 1120 MHU_ACPE_HMICommand 0 "No Request" 1 "ACPE Intervene Alert" 2 "Display prompt offer turn off ACPE" 3 "Reserved" 4 "Reserved" 5 "Reserved" 6 "Reserved" 7 "Invalid" ;
VAL_ 1120 MHU_ACPE_State 0 "Off" 1 "Inactive" 2 "Ready" 3 "Armed" 4 "ACPE Active" 5 "ACPE Inhibited" 6 "Error" 7 "Invalid" ;
VAL_ 1120 MHU_ACPE_Setting_Feed 0 "ACPE Off" 1 "ACPE ON" 2 "Reserved" 3 "Invalid" ;
VAL_ 1120 MHU_ACPE_Sens_Feed 0 "Normal'" 1 "Plus" 2 "Reserved" 3 "Invalid" ;
VAL_ 1120 MHU_ACPE_Check 0 "Available" 1 "Degraded" 2 "Temporarily not available" 3 "Permanently not available" 4 "Inhibited" 5 "Reserved" 6 "Initializing" 7 "Invalid" ;
VAL_ 651 TBOX_ADCU_VAP_State 0 "Idle'" 1 "Active" 2 "Abort" 3 "Error" ;
VAL_ 651 TBOX_ADCU_VAP_CappStatus 0 "NotConnected'" 1 "Connected" 2 "Dropped" 3 "Error" ;
VAL_ 651 TBOX_ADCU_VAP_ParkButtonPressed 0 "Released" 1 "Presssed" ;
VAL_ 651 TBOX_ADCU_VAP_Req 0 "No Request" 1 "Request" ;
VAL_ 651 TBOX_ADCU_VAP_Type 0 "Init" 1 "Park In via MHU" 2 "Park In continue Remote" 3 "Comfort Park In via MHU" 4 "Comfort Park In Continue Remote" 5 "Park Out via MHU" 6 "Park Out via Remote" 7 "Comfort Park Out via MHU" 8 "Comfort Park Out via Remote" 9 "Reverse Forward via MHU" 10 "Reverse Forward via Remote" 11 "Reverse Backward via MHU" 12 "Straight Parking" ;
VAL_ 651 TBOX_ADCU_VAP_TypeSelection 0 "Init" 1 "Parallel" 2 "Perpendicular" 3 "Angled" 4 "Reserved" ;
VAL_ 651 TBOX_ADCU_VAP_UserSelection 0 "Init" 1 "Front Left" 2 "Front Right" 3 "Rear Left" 4 "Rear Right" ;
VAL_ 651 TBOX_ADCU_VAP_NoseDir 0 "Init" 1 "Nose Out" 2 "Nose In" 3 "Reserve" ;
VAL_ 651 TBOX_ADCU_VAP_ParkAngle 0 "0 deg" 1 "'Angled 45deg" 2 "90deg" 3 "Angled 135deg" ;
VAL_ 651 TBOX_ADCU_VAP_UserAction 0 "No action" 1 "StartParking" 2 "Pause" 3 "Abort" 4 "Skip" 5 "Back" 6 "Resume" 7 "Accept Spot" ;
VAL_ 1033 TBOX_IntrusionAlertStatus 0 "OFF" 1 "ON" 2 "Stop Alarm" 3 "Signal invalid" ;
VAL_ 1034 TBOX_BKBattery_Malfunction 0 "None" 1 "Alert" ;
VAL_ 1034 TBOX_eCall_Malfunction 0 "None" 1 "Alert" ;
VAL_ 1042 eCall_state 0 "Off/Inactive" 1 "Faulted/Error" 2 "On/Active - Call Not Triggered Automatically" 3 "On/Active - Call Automatically Triggered" 4 "On/Active - eCall Ongoing" ;
VAL_ 1048 TBOX_MNF_ModeReq 0 "No command" 1 "OFF" 2 "Cooling" 3 "Heating" ;
VAL_ 1048 TBOX_MNF_SpecialModeReq 0 "No command" 1 "Iced" 2 "Preservation" 3 "Warm milk" 4 "Reserved" 5 "Reserved" 6 "Reserved" 7 "Reserved" ;
VAL_ 128 FCAM_TSR_PopUp_Feed 0 "Off" 1 "Pop Up 1" 2 "Pop Up 2" 3 "Pop Up 3" 4 "Pop Up 4" 5 "Pop Up 5" 6 "Pop Up 6" 7 "Pop Up 7" 8 "Pop Up 8" 9 "Pop Up 9" 10 "Pop Up 10" 11 "Reserved" 12 "Reserved" 13 "Reserved" 14 "Reserved" 15 "Invalid" ;
VAL_ 128 FCAM_TSR_SLAert_Feed 0 "Offset" 1 "Offset + 5" 2 "Offset + 10" 3 "Reserved" ;
VAL_ 128 FCAM_TSR_Typ2_value 0 "No value" 1 "5" 2 "10" 3 "15" 4 "20" 5 "25" 6 "30" 7 "35" 8 "40" 9 "45" 10 "50" 11 "55" 12 "60" 13 "65" 14 "70" 15 "75" 16 "80" 17 "85" 18 "90" 19 "95" 20 "100" 21 "105" 22 "110" 23 "115" 24 "120" 25 "125" 26 "130" 27 "135" 28 "140" 29 "145" 30 "150" 31 "155" ;
VAL_ 128 FCAM_TSR_Typ1 0 "No detected" 1 "Maximum Speed Limit" 2 "End of speed limit sign" 3 "Invalid value" 4 "Reserve" 5 "Resever" ;
VAL_ 128 FCAM_TSR_Typ1_value 0 "No value" 1 "5" 2 "10" 3 "15" 4 "20" 5 "25" 6 "30" 7 "35" 8 "40" 9 "45" 10 "50" 11 "55" 12 "60" 13 "65" 14 "70" 15 "75" 16 "80" 17 "85" 18 "90" 19 "95" 20 "100" 21 "105" 22 "110" 23 "115" 24 "120" 25 "125" 26 "130" 27 "135" 28 "140" 29 "145" 30 "150" 31 "155" ;
VAL_ 128 FCAM_TSR_Warning_audible 0 "Off" 1 "On" ;
VAL_ 128 FCAM_TSR_Typ2_Flashing_Warning 0 "Off" 1 "On" ;
VAL_ 128 FCAM_TSR_Mode_Feed 0 "Off" 1 "On" 2 "reserved" 3 "Reserved" ;
VAL_ 128 FCAM_TSR_AudWarning_Feed 0 "Off" 1 "On" ;
VAL_ 128 FCAM_TSR_Typ1_Flashing_Warning 0 "Off" 1 "On" ;
VAL_ 128 FCAM_TSR_Typ3 0 "No detected" 1 "End of signed prohibition" 2 "End of Tunnel" 3 "Tunnel" 4 "Snow" 5 "Slippery road" 6 "Pedestrian Crossing" 7 "School crossing" 8 "No passing" 9 "No left turn" 10 "No right turn" 11 "No left U turn" 12 "Stop sign" 13 "car prohibited" 14 "No entry" 15 "No Thoroughfare" 16 "Yield" 17 "No right U turn" 18 " No left turn or left U turn" 19 "No right turn or right U turn" 20 "End of overtaking prohibition" 21 "Curve left" 22 "Curve right" 23 "4way junction" 24 "T junction" 25 "T junction right" 26 "T junction left" 27 "Y junction" 28 "Roundabout" 29 "Uneven road surface" 30 "Speed hump" 31 "Dangerous shoulder" 32 "Construction" 33 "Falling rocks" 34 "Loose Chippings" 35 "Animal Crossing" 36 "Slow" 37 "Reserved" 38 "Reserved" 39 "Reserved" 40 "Reserved" ;
VAL_ 128 FCAM_TSR_Typ2 0 "No detected" 1 "Camping zone" 2 "Highway" 3 "Town zone" 4 "End of town zone" 5 "Express way" 6 "Bicycle way" 7 "Night" 8 "Minimun speed limit" 9 "Ramp" 10 "Exit" 11 "Curve" 12 "School zone" 13 "Reserved" 14 "Reserved" 15 "Reserved" ;
VAL_ 128 FCAM_TSR_State 0 "Standby" 1 "Active_Fusion" 2 "Active_Vision_Only" 3 "Active_Map_ONLY" 4 "Fault" 5 "OFF" 6 "Reserved" 7 "Reserved" ;
VAL_ 128 FCAM_TSR_Haptic_Mode_Feed 0 "Off" 1 "On" ;
VAL_ 128 FCAM_SLW_Mode_Feed 0 "Off" 1 "On" ;
VAL_ 128 FCAM_DNS_Popup_Feed 0 "None" 1 "Departure notification" ;
VAL_ 295 FCAM_ELKA_ON_feed 0 "ELKA_OFF" 1 "ELKA_ON" ;
VAL_ 295 FCAM_LKA_HOD_state 0 "Hands On" 1 "Hands Off Warning" ;
VAL_ 295 FCAM_ECU_check 0 "Available" 1 "Fault" 2 "reserved" ;
VAL_ 295 FCAM_LA_sens_Feed 0 "Early" 1 "Normal" 2 "Late" 3 "Signal Invalid" ;
VAL_ 295 FCAM_LKA_ICON_Feed 0 "No icon" 1 "ICON_1" 2 "ICON_2" 3 "ICON_3" 4 "ICON_4" 5 "ICON_5" ;
VAL_ 295 FCAM_LDW_check 0 "Available" 1 "Temporary fault" 2 "Permanent fault" 3 "Reserved" ;
VAL_ 295 FCAM_LKA_check 0 "Available" 1 "Temporary fault" 2 "Permanent fault" 3 "Automatic Deactivation" ;
VAL_ 295 FCAM_LA_popup 0 "No Popup" 1 "Take control Veh departing lane" 2 "Emergency steering for safety" 3 "lane keep assist in intervention" 4 "Emergency lane keep assist" 5 "reserved" 6 "reserved" 7 "Lane assist Unavailable" ;
VAL_ 295 FCAM_LA_Mode_Feed 0 "OFF" 1 "Setting 1" 2 "Setting 2" 3 "Setting 3" 4 "Signal Invalid" ;
VAL_ 295 FCAM_LA_LeftLaneColor_Feed 0 "No color" 1 "Gray" 2 "White" 3 "Green" 4 "Blue" 5 "Yellow" 6 "Red" 7 "Reserved" ;
VAL_ 295 FCAM_LA_RightLaneColor_Feed 0 "No color" 1 "Gray" 2 "White" 3 "Green" 4 "Blue" 5 "Yellow" 6 "Red" 7 "Reserved" ;
VAL_ 295 FCAM_ELK_check 0 "Available" 1 "Temporary fault" 2 "Permanent fault" 3 "Reserved" ;
VAL_ 295 FCAM_ELK_State 0 "Init" 1 "Off" 2 "Passive" 3 "Standby" 4 "Active" 5 "Fault" 6 "Reserve" 7 "Reserve" ;
VAL_ 295 FCAM_LKA_State 0 "Init" 1 "Off" 2 "Passive" 3 "Standby" 4 "Active" 5 "Fault" 6 "Reserve" 7 "Reserve" ;
VAL_ 295 FCAM_LDW_State 0 "Init" 1 "Off" 2 "Passive" 3 "Standby" 4 "Active" 5 "Fault" 6 "Reserve" 7 "Reserve" ;
VAL_ 295 FCAM_ELK_Warning 0 "No Warning" 1 "Solid Lane & Road Edge Left" 2 "Solid Lane & Road Edge Right" 3 "Overtaking Left" 4 "Overtaking Right" 5 "Oncoming Left" 6 "Oncoming Right" 7 "Reserve" 8 "Reserve" ;
VAL_ 295 FCAM_LDW_Warning 0 "No warning" 1 "Departure on left" 2 "Departure on right" 3 "Reserved" ;
VAL_ 295 FCAM_handsoff_Warning_Mode_2 0 "No Warning!" 1 "Level 1" 2 "Level 2" 3 "Level 3" 4 "reserved" 5 "reserved" 6 "reserved" 7 "reserved" ;
VAL_ 295 FCAM_LKA_LDW_Haptic_Mode_Feed 0 "OFF" 1 "ON" ;
VAL_ 295 FCAM_ELK_Haptic_Mode_Feed 0 "OFF" 1 "ON" ;
VAL_ 295 FCAM_LKA_Warning 0 "No LKA" 1 "LKA intervention Left" 2 "LKA intervention Right" 3 "Reserved" ;
VAL_ 314 FCAM_ESA_Sts 0 "FctaOn1_StrtUpOn (Not_enabled)" 1 "FctaOn1_On (Active)" 2 "FctaOn1_Off (Inactive)" 3 "FctaOn1_Error (Denied)" ;
VAL_ 314 FCAM_ESA_Execution_Side 0 "To the right side" 1 "To the left side" ;
VAL_ 314 FCAM_ESA_Popup_Sts 0 "None" 1 "Post ESA triggered" 2 "Post AEB + ESA triggered" 3 "ESA assisting" ;
VAL_ 314 FCAM_ESA_Mode 0 "OFF" 1 "ON" ;
VAL_ 314 FCAM_ESA_check 0 "Available" 1 "Temporary fault" 2 "Permanent Fault" 3 "Invalid" ;
VAL_ 515 R1_LINE_TYPE 0 "No display" 1 "Solid Line" 2 "Dashed Line" 3 "Roadside" ;
VAL_ 515 R0_LINE_TYPE 0 "No display" 1 "solid line" 2 "dashed line" 3 "Roadside" ;
VAL_ 515 FCAM_Camera_R1_Line_Type 0 "No display" 1 "solid line" 2 "dashed line" 3 "Roadside" ;
VAL_ 515 FCAM_Camera_L1_Line_Type 0 "No display" 1 "Solid line" 2 "Dashed line" 3 "Roadside" ;
VAL_ 515 FCAM_ISA_SpeedLimitCnt_Spd_Feed 0 "0" 1 "5 KPH" 2 "10 KPH" 3 "15 KPH" 4 "20 KPH" 5 "5 MPH" 6 "10 MPH" 7 "15 MPH" 8 "Reserved" 9 "Reserved" 10 "Reserved" 11 "Reserved" 12 "Reserved" 13 "Reserved" 14 "Reserved" ;
VAL_ 515 FCAM_ISA_SpeedLimitCnt_Per_Feed 0 "0 Percent" 1 "5 Percent" 2 "10 Percent" 3 "15 percent" 4 "Reserved" 5 "Reserved" 6 "Reserved" ;
VAL_ 515 L1_LINE_TYPE 0 "NoDisplay" 1 "Solid Line" 2 "Dashed Line" 3 "Roadside" ;
VAL_ 515 L0_LINE_TYPE 0 "No display" 1 "solid line" 2 "dashed line" 3 "Roadside" ;
VAL_ 515 FCAM_SCAM_Fault 0 "No fault" 1 "Temp fault(clean fix)" 2 "Temp fault(Environment)" 3 "Permanent fault" ;
VAL_ 515 FCAM_MRR_Fault 0 "No fault" 1 "Temp fault(clean fix)" 2 "Temp fault(Environment)" 3 "Permanent fault" ;
VAL_ 518 FCAM_HWA_Fautlstate 0 "no_error" 1 "HWA" 2 "fault" 3 "Reserved" ;
VAL_ 518 FCAM_ALC_Mode_feed 0 "OFF" 1 "ON" 2 "Reserved" 3 "Reserved" ;
VAL_ 518 FCAM_HWA_txtpopup 0 "No popup" 1 "HWA activated successfully by user" 2 "HWA disengaged manually by user" 3 "Remind driver to Press RES or accelerator pedal to re-engage the function" 4 "HWA activation rejected because of preconditions not met" 5 "Resume rejected. No previous ACC/HWA active" 6 "HWA activation rejected because feature is fault" 7 "Potential HWA degradation ahead" 8 "Takeover warning because boundary conditions reached. HWA still try to help." 9 "Takeover warning because HWA automatically disengaged" 10 "Take over warning. HWA overspeed. Cannot maintain set speed." 11 "Lateral control inhibit- non user input" 12 "Reserve" ;
VAL_ 518 FCAM_HWA_state 0 "Off" 1 "Stand_by" 2 "Active" 3 "Override" 4 "Passive" 5 "Active_suspend" 6 "Offset Assist" 7 "AESA" 8 "Fault" ;
VAL_ 518 FCAM_ALC_txtpopup 0 "No popup" 1 "Left ALC initiated by driver" 2 "Right ALC initated by driver" 3 "Left ALC recommended" 4 "Right ALC recommended" 5 "Left ALC start manoeuvre" 6 "Right ALC start manoeuvre" 7 "ALC request rejected when user initiate" 8 "ALC canceled because timeout after x sec trying to start manoeuvre" 9 "ALC canceled manually by user" 10 "ALC canceled by system before PONR. Able to resume HWA" 11 "ALC canceled by system after PONR. Able to resume HWA" 12 "ALC cancel because of handsoff + Need user takeover" 13 "ALC canceled by system + Need user takeover" 14 "Reserve" 15 "Reserve" ;
VAL_ 518 FCAM_ALC_state 0 "Off" 1 "Stand_by" 2 "Active" 3 "Rejected" 4 "Passive" 5 "Finished" 6 "Fault" 7 "Abort" ;
VAL_ 518 FCAM_AESA_DoorUnlock_Req 0 "No request" 1 "Requested" ;
VAL_ 518 FCAM_AESA_ECALL_Req 0 "No request" 1 "Requested" ;
VAL_ 518 FCAM_AESA_Status 0 "Not active" 1 "Decelerating" 2 "Target following" 3 "Reserved" ;
VAL_ 518 FCAM_AESA_popup 0 "None" 1 "Takeover-AESA Activate" 2 "Post AESA - AESA complete" 3 "Post AESA - AESA cancelled due to user intervention" ;
VAL_ 518 FCAM_TakeOver_Request 0 "Off" 1 "Take Over 1" 2 "Take Over 2" 3 "Take Over 3" 4 "Take Over 4" 5 "Take Over 5" 6 "Take Over 6" 7 "Take Over 7" 8 "Take Over 8" 9 "Take Over 9" 10 "Take Over 10" 11 "Take Over 11" 12 "Take Over 12" 13 "Take Over 13" 14 "Take Over 14" 15 "Take Over 15" 16 "Take Over 6" 17 "Take Over 17" 18 "Take Over 18" 19 "Take Over 19" 20 "Take Over 20" 21 "Reserve 1" 22 "Reserved 2" 23 "Reserved 3" 24 "Reserved 4" 25 "Reserved 5" 26 "Reserved 6" 27 "Reserved 7" 28 "Reserved 8" 29 "Reserved 9" 30 "Reserved 10" 31 "Invalid" ;
VAL_ 518 FCAM_Sounds_Feed 0 "Off" 1 "Chime 1" 2 "Chime 2" 3 "Chime 3" 4 "Chime 4" 5 "Chime 5" 6 "Chime 6" 7 "Chime 7" 8 "Chime 8" 9 "Chime 9" 10 "Chime 10" 11 "Chime 11" 12 "Chime 12" 13 "Chime 13" 14 "Chime 14" 15 "Chime 15" 16 "Chime 16" 17 "Chime 17" 18 "Chime 18" 19 "Chime 19" 20 "Chime 20" 21 "Reserve 1" 22 "Reserved 2" 23 "Reserved 3" 24 "Reserved 4" 25 "Reserved 5" 26 "Reserved 6" 27 "Reserved 7" 28 "Reserved 8" 29 "Reserved 9" 30 "Reserved 10" 31 "Invalid" ;
VAL_ 518 FCAM_ALC_ICON_Feed 0 "No Icon" 1 "Passive" 2 "Standby Left only" 3 "Standby Right only" 4 "Standby both sides" 5 "Active Left initiate" 6 "Active Right initiate" 7 "Active Left manoeuvre" 8 "Active Right manoeuvre" ;
VAL_ 518 FCAM_HWA_ICON_Feed 0 "No icon" 1 "ICON_1" 2 "ICON_2" 3 "ICON_3" 4 "ICON_4" 5 "ICON_5" 6 "ICON_6" 7 "ICON_7" ;
VAL_ 518 FCAM_ALC_Mode_Gaze_Feed 0 "OFF" 1 "ON" 2 "Reserved" 3 "Reserved" ;
VAL_ 518 FCAM_ALC_Mode_Recommend_Feed 0 "OFF" 1 "ON" 2 "Reserved" 3 "Reserved" ;
VAL_ 518 FCAM_HWA_check 0 "Available" 1 "Temporarily not available" 2 "Permanently not available" ;
VAL_ 518 FCAM_MHU_ALC_Option_feed 0 "No action" 1 "Perform Driver-Initiated Lane Change" 2 "Perform System-Initiated but Driver-Confirmed Lane Change" ;
VAL_ 518 FCAM_EOR_warning 0 "No warning" 1 "EOR" 2 "Reserved" 3 "Reserved" 4 "Reserved" 5 "Reserved" 6 "Reserved" ;
VAL_ 518 FCAM_HWA_Mode_Feed 0 "OFF" 1 "ON" ;
VAL_ 527 FCAM_ADAS_HOD 0 "Hands On" 1 "Hands Off" ;
VAL_ 528 FCAM_NOP_check 0 "Available" 1 "Temporary fault" 2 "Permanent Fault" 3 "Invalid" ;
VAL_ 528 FCAM_NOP_state 0 "Off" 1 "Standby" 2 "Active" 3 "Override" 4 "Passive" 5 "Downgrade to HWA_ALCA" 6 "MRM" 7 "Fault" 8 "Downgrade to ACC" 9 "Reserve" 10 "Reserve" 11 "Reserve" 12 "Reserve" 13 "Reserve" 14 "Reserve" 15 "Reserve" ;
VAL_ 528 FCAM_NOP_ICON_Feed 0 "No icon" 1 "Gray ICON" 2 "Purple ICON" 3 "White ICON" 4 "Yellow ICON" 5 "Red ICON" 7 "Invalid" ;
VAL_ 528 FCAM_NOP_txtpopup 0 "OFF" 1 "NOP initial activation" 2 "Manual Cancel warning" 3 "Downgrade to HWA ahead" 4 "Activation Rejected" 5 "Sensors / System fault" 6 "Notification Change Lane Left Navigation Only" 7 "Notification Change Lane Right Navigation Only" 8 "Overtaking suggestion" 9 "Leaving ODD" 10 "Temporary function suspension - construction zones, tunnels, adverse conditions" 11 "Sharp curve ahead" 12 "Resume rejected. NOP not activated" 13 "Destination reached" 14 "Unprotected intersection ahead" 15 "Vehicle low speed ahead" 16 "Take Over control" 17 "Ambulance / Emergency vehicle detected" 18 "text_popup_18" 19 "text_popup_19" 20 "text_popup_20" 21 "text_popup_21" 22 "text_popup_22" 23 "text_popup_23" 24 "text_popup_24" 25 "text_popup_25" 26 "text_popup_26" 27 "text_popup_27" 28 "text_popup_28" 29 "text_popup_29" 30 "text_popup_30" 31 "text_popup_31" ;
VAL_ 528 FCAM_NOP_Warning 0 "No Request" 1 "Audible Warning" 2 "Reserved" 3 "Invalid" ;
VAL_ 528 FCAM_NOP_AAESA_state 0 "No txt" 1 "text 1" 2 "text 2" 3 "text 3" 4 "text 4" 5 "text 5" 6 "text 6" 7 "reserved" ;
VAL_ 528 FCAM_NOP_TOR 0 "No txt" 1 "text 1" 2 "text 2" 3 "text 3" 4 "text 4" 5 "text 5" 6 "text 6" 7 "reserved" ;
VAL_ 528 FCAM_eyesoff_Warning_Mode_2 0 "No Warning!" 1 "Level 1" 2 "Level 2" 3 "Level 3" 4 "reserved" 5 "reserved" 6 "reserved" 7 "reserved" ;
VAL_ 528 FCAM_EOD 0 "Eyes Ont" 1 "Eyes Off" ;
VAL_ 528 FCAM_NOP_Mode_Feed 0 "OFF" 1 "ON" 2 "Reserved" 3 "Reserved" ;
VAL_ 528 FCAM_NOP_Type_Feed 0 "Init" 1 "HWA" 2 "NOP" 3 "Reserved" ;
VAL_ 540 FCAM_AEB_Warning 0 "No warning" 1 "Braking" 2 "Post Feedback" ;
VAL_ 540 FCAM_AEB_State 0 "OFF State" 1 "Stand by Mode" 2 "Active Mode" 3 "Hold Mode" 4 "Suppressed" 5 "Fault" ;
VAL_ 540 FCAM_AEB_Mode_Feed 0 "Off" 1 "ON" ;
VAL_ 540 FCAM_AEB_check 0 "Available" 1 "Temporarily not available" 2 "Permanently not available" ;
VAL_ 540 FCAM_FCW_Mode_Feed 0 "Off" 1 "ON" ;
VAL_ 540 FCAM_FCW_Sens_Feed 0 "Early" 1 "Normal" 2 "Late" 3 "Reserved" ;
VAL_ 540 FCAM_FCW_state 0 "OFF State" 1 "Stand by state" 2 "Active state" 3 "reserve" ;
VAL_ 540 FCAM_FCW_check 0 "Available" 1 "Temporarily not available" 2 "Permanently not available" ;
VAL_ 540 FCAM_FCW_warning 0 "No Warning" 1 "warning stage-1" 2 "warning stage-2" 3 "warning stage-3" ;
VAL_ 540 FCAM_CV_AEB_Alert 0 "No AEB (Fusion)" 1 "AEB active (Fusion)" ;
VAL_ 540 FCAM_CV_FCW_Alert 0 "No FCW (Fusion)" 1 "FCW active (Fusion)" ;
VAL_ 540 FCAM_CV_PartialAEB_Alert 0 "No partial AEB (Fusion)" 1 "Partial AEB active (Fusion)" ;
VAL_ 540 FCAM_CV_PreFill_Alert 0 "No Prefill (Fusion)" 1 "Prefill active (Fusion)" ;
VAL_ 540 FCAM_VD_AEB_Alert 0 "No AEB (Fusion)" 1 "AEB active (Fusion)" ;
VAL_ 540 FCAM_VD_DBS_Alert 0 "No DBS (Vision)" 1 "DBS active (Vision)" ;
VAL_ 540 FCAM_VD_EGOTAP_AEB_Alert 0 "No AEB for tap (Vision)" 1 "AEB active for tap (Vision)" ;
VAL_ 540 FCAM_VD_FCW_Alert 0 "No FCW for C2C/ C2M (Vision)" 1 "FCW active C2C/ C2M (Vision)" ;
VAL_ 540 FCAM_VD_HeadOn_AEB_Alert 0 "No AEB for head on (Vision) " 1 "AEB active for head on (Vision)" ;
VAL_ 540 FCAM_VD_PartialAEB_Alert 0 "No partial AEB for C2C/C2M (Vision)" 1 "Partial AEB active for C2C/C2M (Vision)" ;
VAL_ 540 FCAM_VD_Prefill_Alert 0 "No Prefill for C2C/C2M (Vision)" 1 "Prefill active for C2C/C2M (Vision)'" ;
VAL_ 540 FCAM_VRU_AEB_Alert 0 "No AEB for VRU (Vision)" 1 "AEB active for VRU (Vision)" ;
VAL_ 540 FCAM_VRU_FCW_Alert 0 "No FCW for VRU (Vision)" 1 "FCW active for VRU (VIsion)" ;
VAL_ 540 FCAM_VRU_PreFill_Alert 0 "No Prefill for VRU (Vision)" 1 "Prefill active for VRU (Vision)" ;
VAL_ 540 FCAM_AEB_Trigger_Source 0 "None" 1 "Vsion Only" 2 "Fusion Only" 3 "Both" ;
VAL_ 540 FCAM_FCW_Trigger_Source 0 "None" 1 "Vsion Only" 2 "Fusion Only" 3 "Both" ;
VAL_ 540 FCAM_AEB_BrakeReq_Source 0 "None" 1 "FAEB request" 2 "Front ACPE Request" 3 "FCTB request" 4 "Reserved" 5 "Reserved" 6 "Reserved" 7 "Invalid" ;
VAL_ 763 Tsync_Message_FUP_SGW 0 "SyncToGTM" 1 "SyncToSubDomain" ;
VAL_ 763 Tsync_Message_Type 32 "SYNC CRC secured message" 40 "FUP CRC secured message" ;
VAL_ 833 FCAM_OBJ01_Class 0 "No type" 1 "Sedan car" 2 "Truck" 3 "Motorcycle" 4 "Bicycle" 5 "Pedestrian" 6 "Bus" 7 "SUV car" 8 "Traffic Cones" 9 "Reserve" 10 "Reserve" 11 "Reserve" 12 "Reserve" ;
VAL_ 833 FCAM_OBJ01_ClosestSurface 0 "Init" 1 "Center Point" 2 "Rear" 3 "Left" 4 "Right" 5 "Front" 6 "Reserve" 7 "Reserve" ;
VAL_ 833 FCAM_OBJ02_Class 0 "No type" 1 "Sedan car" 2 "Truck" 3 "Motorcycle" 4 "Bicycle" 5 "Pedestrian" 6 "Bus" 7 "SUV car" 8 "Traffic Cones" 9 "Reserve" 10 "Reserve" 11 "Reserve" 12 "Reserve" ;
VAL_ 833 FCAM_OBJ02_ClosestSurface 0 "Init" 1 "Center Point" 2 "Rear" 3 "Left" 4 "Right" 5 "Front" 6 "Reserve" 7 "Reserve" ;
VAL_ 833 FCAM_OBJ03_Class 0 "No type" 1 "Sedan car" 2 "Truck" 3 "Motorcycle" 4 "Bicycle" 5 "Pedestrian" 6 "Bus" 7 "SUV car" 8 "Traffic Cones" 9 "Reserve" 10 "Reserve" 11 "Reserve" 12 "Reserve" ;
VAL_ 833 FCAM_OBJ03_ClosestSurface 0 "Init" 1 "Center Point" 2 "Rear" 3 "Left" 4 "Right" 5 "Front" 6 "Reserve" 7 "Reserve" ;
VAL_ 833 FCAM_OBJ04_Class 0 "No type" 1 "Sedan car" 2 "Truck" 3 "Motorcycle" 4 "Bicycle" 5 "Pedestrian" 6 "Bus" 7 "SUV car" 8 "Traffic Cones" 9 "Reserve" 10 "Reserve" 11 "Reserve" 12 "Reserve" ;
VAL_ 833 FCAM_OBJ04_ClosestSurface 0 "Init" 1 "Center Point" 2 "Rear" 3 "Left" 4 "Right" 5 "Front" 6 "Reserve" 7 "Reserve" ;
VAL_ 833 FCAM_OBJ05_Class 0 "No type" 1 "Sedan car" 2 "Truck" 3 "Motorcycle" 4 "Bicycle" 5 "Pedestrian" 6 "Bus" 7 "SUV car" 8 "Traffic Cones" 9 "Reserve" 10 "Reserve" 11 "Reserve" 12 "Reserve" ;
VAL_ 833 FCAM_OBJ05_ClosestSurface 0 "Init" 1 "Center Point" 2 "Rear" 3 "Left" 4 "Right" 5 "Front" 6 "Reserve" 7 "Reserve" ;
VAL_ 833 FCAM_OBJ05_TurnSignal 0 "Off" 1 "Left" 2 "Right" 3 "Both/Hazard" ;
VAL_ 833 FCAM_OBJ05_BrakeLight 0 "No brake" 1 "Braking" ;
VAL_ 833 FCAM_OBJ06_TurnSignal 0 "Off" 1 "Left" 2 "Right" 3 "Both/Hazard" ;
VAL_ 833 FCAM_OBJ06_BrakeLight 0 "No brake" 1 "Braking" ;
VAL_ 833 FCAM_OBJ06_ClosestSurface 0 "Init" 1 "Center Point" 2 "Rear" 3 "Left" 4 "Right" 5 "Front" 6 "Reserve" 7 "Reserve" ;
VAL_ 833 FCAM_OBJ07_Class 0 "No type" 1 "Sedan car" 2 "Truck" 3 "Motorcycle" 4 "Bicycle" 5 "Pedestrian" 6 "Bus" 7 "SUV car" 8 "Traffic Cones" 9 "Reserve" 10 "Reserve" 11 "Reserve" 12 "Reserve" ;
VAL_ 833 FCAM_OBJ07_TurnSignal 0 "Off" 1 "Left" 2 "Right" 3 "Both/Hazard" ;
VAL_ 833 FCAM_OBJ07_BrakeLight 0 "No brake" 1 "Braking" ;
VAL_ 833 FCAM_OBJ07_ClosestSurface 0 "Init" 1 "Center Point" 2 "Rear" 3 "Left" 4 "Right" 5 "Front" 6 "Reserve" 7 "Reserve" ;
VAL_ 833 FCAM_OBJ08_ClosestSurface 0 "Init" 1 "Center Point" 2 "Rear" 3 "Left" 4 "Right" 5 "Front" 6 "Reserve" 7 "Reserve" ;
VAL_ 833 FCAM_OBJ08_Class 0 "No type" 1 "Sedan car" 2 "Truck" 3 "Motorcycle" 4 "Bicycle" 5 "Pedestrian" 6 "Bus" 7 "SUV car" 8 "Traffic Cones" 9 "Reserve" 10 "Reserve" 11 "Reserve" 12 "Reserve" ;
VAL_ 833 FCAM_OBJ08_TurnSignal 0 "Off" 1 "Left" 2 "Right" 3 "Both/Hazard" ;
VAL_ 833 FCAM_OBJ08_BrakeLight 0 "No brake" 1 "Braking" ;
VAL_ 834 FCAM_R0_Line_Class 0 "No Type" 1 "Single dashed white" 2 "Single dashed yellow" 3 "Single solid white" 4 "Single solid yellow" 5 "Double solid white" 6 "Double solid yellow" 7 "Dashed solid white" 8 "Solid dashed white" 9 "Dashed solid yellow" 10 "Solid dashed yellow" 11 "Road edge" 12 "Reserve" 13 "Reserve" 14 "Reserve" 15 "Reserve" ;
VAL_ 834 FCAM_R1_Line_Class 0 "No Type" 1 "Single dashed white" 2 "Single dashed yellow" 3 "Single solid white" 4 "Single solid yellow" 5 "Double solid white" 6 "Double solid yellow" 7 "Dashed solid white" 8 "Solid dashed white" 9 "Dashed solid yellow" 10 "Solid dashed yellow" 11 "Road edge" 12 "Reserve" 13 "Reserve" 14 "Reserve" 15 "Reserve" ;
VAL_ 834 FCAM_R2_Line_Class 0 "No Type" 1 "Single dashed white" 2 "Single dashed yellow" 3 "Single solid white" 4 "Single solid yellow" 5 "Double solid white" 6 "Double solid yellow" 7 "Dashed solid white" 8 "Solid dashed white" 9 "Dashed solid yellow" 10 "Solid dashed yellow" 11 "Road edge" 12 "Reserve" 13 "Reserve" 14 "Reserve" 15 "Reserve" ;
VAL_ 835 FCAM_L0_Line_Class 0 "No Type" 1 "Single dashed white" 2 "Single dashed yellow" 3 "Single solid white" 4 "Single solid yellow" 5 "Double solid white" 6 "Double solid yellow" 7 "Dashed solid white" 8 "Solid dashed white" 9 "Dashed solid yellow" 10 "Solid dashed yellow" 11 "Road edge" 12 "Reserve" 13 "Reserve" 14 "Reserve" 15 "Reserve" ;
VAL_ 835 FCAM_L1_Line_Class 0 "No Type" 1 "Single dashed white" 2 "Single dashed yellow" 3 "Single solid white" 4 "Single solid yellow" 5 "Double solid white" 6 "Double solid yellow" 7 "Dashed solid white" 8 "Solid dashed white" 9 "Dashed solid yellow" 10 "Solid dashed yellow" 11 "Road edge" 12 "Reserve" 13 "Reserve" 14 "Reserve" 15 "Reserve" ;
VAL_ 835 FCAM_L2_Line_Class 0 "No Type" 1 "Single dashed white" 2 "Single dashed yellow" 3 "Single solid white" 4 "Single solid yellow" 5 "Double solid white" 6 "Double solid yellow" 7 "Dashed solid white" 8 "Solid dashed white" 9 "Dashed solid yellow" 10 "Solid dashed yellow" 11 "Road edge" 12 "Reserve" 13 "Reserve" 14 "Reserve" 15 "Reserve" ;
VAL_ 835 FCAM_OBJ01_TurnSignal 0 "Off" 1 "Left" 2 "Right" 3 "Both/Hazard" ;
VAL_ 835 FCAM_OBJ01_BrakeLight 0 "No brake" 1 "Braking" ;
VAL_ 835 FCAM_OBJ02_TurnSignal 0 "Off" 1 "Left" 2 "Right" 3 "Both/Hazard" ;
VAL_ 835 FCAM_OBJ02_BrakeLight 0 "No brake" 1 "Braking" ;
VAL_ 835 FCAM_OBJ03_TurnSignal 0 "Off" 1 "Left" 2 "Right" 3 "Both/Hazard" ;
VAL_ 835 FCAM_OBJ03_BrakeLight 0 "No brake" 1 "Braking" ;
VAL_ 835 FCAM_OBJ04_TurnSignal 0 "Off" 1 "Left" 2 "Right" 3 "Both/Hazard" ;
VAL_ 835 FCAM_OBJ04_BrakeLight 0 "No brake" 1 "Braking" ;
VAL_ 836 FCAM_OBJ09_Class 0 "No type" 1 "Sedan car" 2 "Truck" 3 "Motorcycle" 4 "Bicycle" 5 "Pedestrian" 6 "Bus" 7 "SUV car" 8 "Traffic Cones" 9 "Reserve" 10 "Reserve" 11 "Reserve" 12 "Reserve" ;
VAL_ 836 FCAM_OBJ09_ClosestSurface 0 "Init" 1 "Center Point" 2 "Rear" 3 "Left" 4 "Right" 5 "Front" 6 "Reserve" 7 "Reserve" ;
VAL_ 836 FCAM_OBJ09_TurnSignal 0 "Off" 1 "Left" 2 "Right" 3 "Both/Hazard" ;
VAL_ 836 FCAM_OBJ09_BrakeLight 0 "No brake" 1 "Braking" ;
VAL_ 836 FCAM_OBJ10_Class 0 "No type" 1 "Sedan car" 2 "Truck" 3 "Motorcycle" 4 "Bicycle" 5 "Pedestrian" 6 "Bus" 7 "SUV car" 8 "Traffic Cones" 9 "Reserve" 10 "Reserve" 11 "Reserve" 12 "Reserve" ;
VAL_ 836 FCAM_OBJ10_ClosestSurface 0 "Init" 1 "Center Point" 2 "Rear" 3 "Left" 4 "Right" 5 "Front" 6 "Reserve" 7 "Reserve" ;
VAL_ 836 FCAM_OBJ10_TurnSignal 0 "Off" 1 "Left" 2 "Right" 3 "Both/Hazard" ;
VAL_ 836 FCAM_OBJ10_BrakeLight 0 "No brake" 1 "Braking" ;
VAL_ 836 FCAM_OBJ11_Class 0 "No type" 1 "Sedan car" 2 "Truck" 3 "Motorcycle" 4 "Bicycle" 5 "Pedestrian" 6 "Bus" 7 "SUV car" 8 "Traffic Cones" 9 "Reserve" 10 "Reserve" 11 "Reserve" 12 "Reserve" ;
VAL_ 836 FCAM_OBJ11_ClosestSurface 0 "Init" 1 "Center Point" 2 "Rear" 3 "Left" 4 "Right" 5 "Front" 6 "Reserve" 7 "Reserve" ;
VAL_ 836 FCAM_OBJ11_TurnSignal 0 "Off" 1 "Left" 2 "Right" 3 "Both/Hazard" ;
VAL_ 836 FCAM_OBJ11_BrakeLight 0 "No brake" 1 "Braking" ;
VAL_ 836 FCAM_OBJ12_Class 0 "No type" 1 "Sedan car" 2 "Truck" 3 "Motorcycle" 4 "Bicycle" 5 "Pedestrian" 6 "Bus" 7 "SUV car" 8 "Traffic Cones" 9 "Reserve" 10 "Reserve" 11 "Reserve" 12 "Reserve" ;
VAL_ 836 FCAM_OBJ12_ClosestSurface 0 "Init" 1 "Center Point" 2 "Rear" 3 "Left" 4 "Right" 5 "Front" 6 "Reserve" 7 "Reserve" ;
VAL_ 836 FCAM_OBJ12_TurnSignal 0 "Off" 1 "Left" 2 "Right" 3 "Both/Hazard" ;
VAL_ 836 FCAM_OBJ12_BrakeLight 0 "No brake" 1 "Braking" ;
VAL_ 836 FCAM_OBJ13_Class 0 "No type" 1 "Sedan car" 2 "Truck" 3 "Motorcycle" 4 "Bicycle" 5 "Pedestrian" 6 "Bus" 7 "SUV car" 8 "Traffic Cones" 9 "Reserve" 10 "Reserve" 11 "Reserve" 12 "Reserve" ;
VAL_ 836 FCAM_OBJ13_ClosestSurface 0 "Init" 1 "Center Point" 2 "Rear" 3 "Left" 4 "Right" 5 "Front" 6 "Reserve" 7 "Reserve" ;
VAL_ 836 FCAM_OBJ13_TurnSignal 0 "Off" 1 "Left" 2 "Right" 3 "Both/Hazard" ;
VAL_ 836 FCAM_OBJ13_BrakeLight 0 "No brake" 1 "Braking" ;
VAL_ 836 FCAM_OBJ14_Class 0 "No type" 1 "Sedan car" 2 "Truck" 3 "Motorcycle" 4 "Bicycle" 5 "Pedestrian" 6 "Bus" 7 "SUV car" 8 "Traffic Cones" 9 "Reserve" 10 "Reserve" 11 "Reserve" 12 "Reserve" ;
VAL_ 836 FCAM_OBJ14_ClosestSurface 0 "Init" 1 "Center Point" 2 "Rear" 3 "Left" 4 "Right" 5 "Front" 6 "Reserve" 7 "Reserve" ;
VAL_ 836 FCAM_OBJ14_TurnSignal 0 "Off" 1 "Left" 2 "Right" 3 "Both/Hazard" ;
VAL_ 836 FCAM_OBJ14_BrakeLight 0 "No brake" 1 "Braking" ;
VAL_ 837 FCAM_OBJ15_Class 0 "No type" 1 "Sedan car" 2 "Truck" 3 "Motorcycle" 4 "Bicycle" 5 "Pedestrian" 6 "Bus" 7 "SUV car" 8 "Traffic Cones" 9 "Reserve" 10 "Reserve" 11 "Reserve" 12 "Reserve" ;
VAL_ 837 FCAM_OBJ15_ClosestSurface 0 "Init" 1 "Center Point" 2 "Rear" 3 "Left" 4 "Right" 5 "Front" 6 "Reserve" 7 "Reserve" ;
VAL_ 837 FCAM_OBJ15_TurnSignal 0 "Off" 1 "Left" 2 "Right" 3 "Both/Hazard" ;
VAL_ 837 FCAM_OBJ15_BrakeLight 0 "No brake" 1 "Braking" ;
VAL_ 837 FCAM_OBJ16_Class 0 "No type" 1 "Sedan car" 2 "Truck" 3 "Motorcycle" 4 "Bicycle" 5 "Pedestrian" 6 "Bus" 7 "SUV car" 8 "Traffic Cones" 9 "Reserve" 10 "Reserve" 11 "Reserve" 12 "Reserve" ;
VAL_ 837 FCAM_OBJ16_ClosestSurface 0 "Init" 1 "Center Point" 2 "Rear" 3 "Left" 4 "Right" 5 "Front" 6 "Reserve" 7 "Reserve" ;
VAL_ 837 FCAM_OBJ16_TurnSignal 0 "Off" 1 "Left" 2 "Right" 3 "Both/Hazard" ;
VAL_ 837 FCAM_OBJ16_BrakeLight 0 "No brake" 1 "Braking" ;
VAL_ 837 FCAM_OBJ17_Class 0 "No type" 1 "Sedan car" 2 "Truck" 3 "Motorcycle" 4 "Bicycle" 5 "Pedestrian" 6 "Bus" 7 "SUV car" 8 "Traffic Cones" 9 "Reserve" 10 "Reserve" 11 "Reserve" 12 "Reserve" ;
VAL_ 837 FCAM_OBJ17_ClosestSurface 0 "Init" 1 "Center Point" 2 "Rear" 3 "Left" 4 "Right" 5 "Front" 6 "Reserve" 7 "Reserve" ;
VAL_ 837 FCAM_OBJ17_TurnSignal 0 "Off" 1 "Left" 2 "Right" 3 "Both/Hazard" ;
VAL_ 837 FCAM_OBJ17_BrakeLight 0 "No brake" 1 "Braking" ;
VAL_ 837 FCAM_OBJ18_Class 0 "No type" 1 "Sedan car" 2 "Truck" 3 "Motorcycle" 4 "Bicycle" 5 "Pedestrian" 6 "Bus" 7 "SUV car" 8 "Traffic Cones" 9 "Reserve" 10 "Reserve" 11 "Reserve" 12 "Reserve" ;
VAL_ 837 FCAM_OBJ18_ClosestSurface 0 "Init" 1 "Center Point" 2 "Rear" 3 "Left" 4 "Right" 5 "Front" 6 "Reserve" 7 "Reserve" ;
VAL_ 837 FCAM_OBJ18_TurnSignal 0 "Off" 1 "Left" 2 "Right" 3 "Both/Hazard" ;
VAL_ 837 FCAM_OBJ18_BrakeLight 0 "No brake" 1 "Braking" ;
VAL_ 837 FCAM_OBJ19_Class 0 "No type" 1 "Sedan car" 2 "Truck" 3 "Motorcycle" 4 "Bicycle" 5 "Pedestrian" 6 "Bus" 7 "SUV car" 8 "Traffic Cones" 9 "Reserve" 10 "Reserve" 11 "Reserve" 12 "Reserve" ;
VAL_ 837 FCAM_OBJ19_ClosestSurface 0 "Init" 1 "Center Point" 2 "Rear" 3 "Left" 4 "Right" 5 "Front" 6 "Reserve" 7 "Reserve" ;
VAL_ 837 FCAM_OBJ19_TurnSignal 0 "Off" 1 "Left" 2 "Right" 3 "Both/Hazard" ;
VAL_ 837 FCAM_OBJ19_BrakeLight 0 "No brake" 1 "Braking" ;
VAL_ 837 FCAM_OBJ20_Class 0 "No type" 1 "Sedan car" 2 "Truck" 3 "Motorcycle" 4 "Bicycle" 5 "Pedestrian" 6 "Bus" 7 "SUV car" 8 "Traffic Cones" 9 "Reserve" 10 "Reserve" 11 "Reserve" 12 "Reserve" ;
VAL_ 837 FCAM_OBJ20_ClosestSurface 0 "Init" 1 "Center Point" 2 "Rear" 3 "Left" 4 "Right" 5 "Front" 6 "Reserve" 7 "Reserve" ;
VAL_ 837 FCAM_OBJ20_TurnSignal 0 "Off" 1 "Left" 2 "Right" 3 "Both/Hazard" ;
VAL_ 837 FCAM_OBJ20_BrakeLight 0 "No brake" 1 "Braking" ;
VAL_ 839 FCAM_OBJ21_Class 0 "No type" 1 "Sedan car" 2 "Truck" 3 "Motorcycle" 4 "Bicycle" 5 "Pedestrian" 6 "Bus" 7 "SUV car" 8 "Traffic Cones" 9 "Reserve" 10 "Reserve" 11 "Reserve" 12 "Reserve" ;
VAL_ 839 FCAM_OBJ21_ClosestSurface 0 "Init" 1 "Center Point" 2 "Rear" 3 "Left" 4 "Right" 5 "Front" 6 "Reserve" 7 "Reserve" ;
VAL_ 839 FCAM_OBJ21_TurnSignal 0 "Off" 1 "Left" 2 "Right" 3 "Both/Hazard" ;
VAL_ 839 FCAM_OBJ21_BrakeLight 0 "No brake" 1 "Braking" ;
VAL_ 839 FCAM_OBJ22_Class 0 "No type" 1 "Sedan car" 2 "Truck" 3 "Motorcycle" 4 "Bicycle" 5 "Pedestrian" 6 "Bus" 7 "SUV car" 8 "Traffic Cones" 9 "Reserve" 10 "Reserve" 11 "Reserve" 12 "Reserve" ;
VAL_ 839 FCAM_OBJ22_ClosestSurface 0 "Init" 1 "Center Point" 2 "Rear" 3 "Left" 4 "Right" 5 "Front" 6 "Reserve" 7 "Reserve" ;
VAL_ 839 FCAM_OBJ22_TurnSignal 0 "Off" 1 "Left" 2 "Right" 3 "Both/Hazard" ;
VAL_ 839 FCAM_OBJ22_BrakeLight 0 "No brake" 1 "Braking" ;
VAL_ 839 FCAM_OBJ23_Class 0 "No type" 1 "Sedan car" 2 "Truck" 3 "Motorcycle" 4 "Bicycle" 5 "Pedestrian" 6 "Bus" 7 "SUV car" 8 "Traffic Cones" 9 "Reserve" 10 "Reserve" 11 "Reserve" 12 "Reserve" ;
VAL_ 839 FCAM_OBJ23_ClosestSurface 0 "Init" 1 "Center Point" 2 "Rear" 3 "Left" 4 "Right" 5 "Front" 6 "Reserve" 7 "Reserve" ;
VAL_ 839 FCAM_OBJ23_TurnSignal 0 "Off" 1 "Left" 2 "Right" 3 "Both/Hazard" ;
VAL_ 839 FCAM_OBJ23_BrakeLight 0 "No brake" 1 "Braking" ;
VAL_ 839 FCAM_OBJ24_Class 0 "No type" 1 "Sedan car" 2 "Truck" 3 "Motorcycle" 4 "Bicycle" 5 "Pedestrian" 6 "Bus" 7 "SUV car" 8 "Traffic Cones" 9 "Reserve" 10 "Reserve" 11 "Reserve" 12 "Reserve" ;
VAL_ 839 FCAM_OBJ24_ClosestSurface 0 "Init" 1 "Center Point" 2 "Rear" 3 "Left" 4 "Right" 5 "Front" 6 "Reserve" 7 "Reserve" ;
VAL_ 839 FCAM_OBJ24_TurnSignal 0 "Off" 1 "Left" 2 "Right" 3 "Both/Hazard" ;
VAL_ 839 FCAM_OBJ24_BrakeLight 0 "No brake" 1 "Braking" ;
VAL_ 839 FCAM_OBJ25_Class 0 "No type" 1 "Sedan car" 2 "Truck" 3 "Motorcycle" 4 "Bicycle" 5 "Pedestrian" 6 "Bus" 7 "SUV car" 8 "Traffic Cones" 9 "Reserve" 10 "Reserve" 11 "Reserve" 12 "Reserve" ;
VAL_ 839 FCAM_OBJ25_ClosestSurface 0 "Init" 1 "Center Point" 2 "Rear" 3 "Left" 4 "Right" 5 "Front" 6 "Reserve" 7 "Reserve" ;
VAL_ 839 FCAM_OBJ25_TurnSignal 0 "Off" 1 "Left" 2 "Right" 3 "Both/Hazard" ;
VAL_ 839 FCAM_OBJ25_BrakeLight 0 "No brake" 1 "Braking" ;
VAL_ 839 FCAM_OBJ26_Class 0 "No type" 1 "Sedan car" 2 "Truck" 3 "Motorcycle" 4 "Bicycle" 5 "Pedestrian" 6 "Bus" 7 "SUV car" 8 "Traffic Cones" 9 "Reserve" 10 "Reserve" 11 "Reserve" 12 "Reserve" ;
VAL_ 839 FCAM_OBJ26_ClosestSurface 0 "Init" 1 "Center Point" 2 "Rear" 3 "Left" 4 "Right" 5 "Front" 6 "Reserve" 7 "Reserve" ;
VAL_ 839 FCAM_OBJ26_TurnSignal 0 "Off" 1 "Left" 2 "Right" 3 "Both/Hazard" ;
VAL_ 839 FCAM_OBJ26_BrakeLight 0 "No brake" 1 "Braking" ;
VAL_ 840 FCAM_OBJ27_Class 0 "No type" 1 "Sedan car" 2 "Truck" 3 "Motorcycle" 4 "Bicycle" 5 "Pedestrian" 6 "Bus" 7 "SUV car" 8 "Traffic Cones" 9 "Reserve" 10 "Reserve" 11 "Reserve" 12 "Reserve" ;
VAL_ 840 FCAM_OBJ27_ClosestSurface 0 "Init" 1 "Center Point" 2 "Rear" 3 "Left" 4 "Right" 5 "Front" 6 "Reserve" 7 "Reserve" ;
VAL_ 840 FCAM_OBJ27_TurnSignal 0 "Off" 1 "Left" 2 "Right" 3 "Both/Hazard" ;
VAL_ 840 FCAM_OBJ27_BrakeLight 0 "No brake" 1 "Braking" ;
VAL_ 840 FCAM_OBJ28_Class 0 "No type" 1 "Sedan car" 2 "Truck" 3 "Motorcycle" 4 "Bicycle" 5 "Pedestrian" 6 "Bus" 7 "SUV car" 8 "Traffic Cones" 9 "Reserve" 10 "Reserve" 11 "Reserve" 12 "Reserve" ;
VAL_ 840 FCAM_OBJ28_ClosestSurface 0 "Init" 1 "Center Point" 2 "Rear" 3 "Left" 4 "Right" 5 "Front" 6 "Reserve" 7 "Reserve" ;
VAL_ 840 FCAM_OBJ28_TurnSignal 0 "Off" 1 "Left" 2 "Right" 3 "Both/Hazard" ;
VAL_ 840 FCAM_OBJ28_BrakeLight 0 "No brake" 1 "Braking" ;
VAL_ 840 FCAM_OBJ29_Class 0 "No type" 1 "Sedan car" 2 "Truck" 3 "Motorcycle" 4 "Bicycle" 5 "Pedestrian" 6 "Bus" 7 "SUV car" 8 "Traffic Cones" 9 "Reserve" 10 "Reserve" 11 "Reserve" 12 "Reserve" ;
VAL_ 840 FCAM_OBJ29_ClosestSurface 0 "Init" 1 "Center Point" 2 "Rear" 3 "Left" 4 "Right" 5 "Front" 6 "Reserve" 7 "Reserve" ;
VAL_ 840 FCAM_OBJ29_TurnSignal 0 "Off" 1 "Left" 2 "Right" 3 "Both/Hazard" ;
VAL_ 840 FCAM_OBJ29_BrakeLight 0 "No brake" 1 "Braking" ;
VAL_ 840 FCAM_OBJ30_Class 0 "No type" 1 "Sedan car" 2 "Truck" 3 "Motorcycle" 4 "Bicycle" 5 "Pedestrian" 6 "Bus" 7 "SUV car" 8 "Traffic Cones" 9 "Reserve" 10 "Reserve" 11 "Reserve" 12 "Reserve" ;
VAL_ 840 FCAM_OBJ30_ClosestSurface 0 "Init" 1 "Center Point" 2 "Rear" 3 "Left" 4 "Right" 5 "Front" 6 "Reserve" 7 "Reserve" ;
VAL_ 840 FCAM_OBJ30_TurnSignal 0 "Off" 1 "Left" 2 "Right" 3 "Both/Hazard" ;
VAL_ 840 FCAM_OBJ30_BrakeLight 0 "No brake" 1 "Braking" ;
VAL_ 840 FCAM_OBJ31_Class 0 "No type" 1 "Sedan car" 2 "Truck" 3 "Motorcycle" 4 "Bicycle" 5 "Pedestrian" 6 "Bus" 7 "SUV car" 8 "Traffic Cones" 9 "Reserve" 10 "Reserve" 11 "Reserve" 12 "Reserve" ;
VAL_ 840 FCAM_OBJ31_ClosestSurface 0 "Init" 1 "Center Point" 2 "Rear" 3 "Left" 4 "Right" 5 "Front" 6 "Reserve" 7 "Reserve" ;
VAL_ 840 FCAM_OBJ31_TurnSignal 0 "Off" 1 "Left" 2 "Right" 3 "Both/Hazard" ;
VAL_ 840 FCAM_OBJ31_BrakeLight 0 "No brake" 1 "Braking" ;
VAL_ 840 FCAM_OBJ32_Class 0 "No type" 1 "Sedan car" 2 "Truck" 3 "Motorcycle" 4 "Bicycle" 5 "Pedestrian" 6 "Bus" 7 "SUV car" 8 "Traffic Cones" 9 "Reserve" 10 "Reserve" 11 "Reserve" 12 "Reserve" ;
VAL_ 840 FCAM_OBJ32_ClosestSurface 0 "Init" 1 "Center Point" 2 "Rear" 3 "Left" 4 "Right" 5 "Front" 6 "Reserve" 7 "Reserve" ;
VAL_ 840 FCAM_OBJ32_TurnSignal 0 "Off" 1 "Left" 2 "Right" 3 "Both/Hazard" ;
VAL_ 840 FCAM_OBJ32_BrakeLight 0 "No brake" 1 "Braking" ;
VAL_ 850 FCAM_AHB_sens_Feed 0 "Early" 1 "Normal" 2 "Late" 3 "reserved" ;
VAL_ 850 FCAM_AHB_Mode_Feed 0 "Off" 1 "On" ;
VAL_ 850 FCAM_AHB_check 0 "Available" 1 "Temporarily not available" 2 "Permanently not available" ;
VAL_ 850 FCAM_AHB_state 0 "OFF State" 1 "HighBeam Passive" 2 "HighBeam Ready" 3 "HighBeam Active" 4 "Fault" ;
VAL_ 850 FCAM_AHB_RBPos 0 "Off or low beam" 1 "high beam" 2 "Reserved" 3 "Reserved" 4 "Reserved" 5 "Reserved" 6 "Reserved" 7 "SNA" ;
VAL_ 850 FCAM_AHB_LBPos 0 "Off or low beam" 1 "high beam" 2 "Reserved" 3 "Reserved" 4 "Reserved" 5 "Reserved" 6 "Reserved" 7 "SNA" ;
VAL_ 850 FCAM_DashCam_Status 0 "Off" 1 "On" 2 "Standby" 3 "TransferMode" 4 "TransferAborted" 5 "Failure" 6 "Reserved" 7 "Reserved" ;
VAL_ 850 FCAM_Body_HeadlightReq 0 "No request" 1 "Request turn on" ;
VAL_ 850 FCAM_Body_FoldMirrorReq 0 "No request" 1 "Fold in" 2 "Fold out" 3 "Reserved" ;
VAL_ 850 FCAM_Body_Status 0 "Off" 1 "Standby" 2 "Enable" 3 "Active" 4 "Finished" 5 "Suspend" 6 "Abort" 7 "Failed" ;
VAL_ 850 FCAM_Body_IndicatorlightReq 0 "No request" 1 "Left" 2 "Right" 3 "Hazard" 4 "Turn Indicator Off" ;
VAL_ 851 FCAM_ACC_ObjDetec 0 "Lead Object Not detected" 1 "Lead Object detected" ;
VAL_ 851 FCAM_ISA_check 0 "Available" 1 "Temporarily not available" 2 "Permanently not available" ;
VAL_ 851 FCAM_ISA_Mode_SW_Feed 0 "OFF" 1 "ON" 2 "Auto" 3 "Reserved" ;
VAL_ 851 FCAM_TagSpeed_ICON_Feed 0 "Off" 1 "Gray ICON" 2 "Green ICON" 3 "White ICON" 4 "Yellow ICON" 5 "Red ICON" ;
VAL_ 851 FCAM_ISA_PopUp_Feed 0 "-" 1 "Accelerating to match speed limit" 2 "Decelerating to match speed limit" 3 "Press steering wheel button to match speed limit" 4 "Intelligent Speed Assist Unavailable" 5 "Reserved" 6 "Reserved" 7 "Reserved" 8 "Reserved" 9 "Reserved" 10 "Reserved" 11 "Reserved" 12 "Reserved" 13 "Reserved" 14 "Reserved" 15 "Invalid" ;
VAL_ 851 FCAM_ISA_Btn_Feed 0 "Off" 1 "On" ;
VAL_ 851 FCAM_ACC_DistSet_upper_Feed 0 "-" 1 "Up_Feed" ;
VAL_ 851 FCAM_ACC_TimeGapSet 0 "No time gap" 1 "1st level distance" 2 "2nd level distance" 3 "3rd level distance" 4 "4th level distance" 5 "Reserved" 6 "Reserved" ;
VAL_ 851 FCAM_ACC_State 0 "Passive" 1 "Stand by state" 2 "Active" 3 "Override" 4 "Brake Only" 5 "Standstill Active" 6 "Standstill Wait" 7 "Fault" 8 "OFF State" ;
VAL_ 851 FCAM_ACC_PopUp_Feed 0 "-" 1 "None (Feature On)" 2 "None (Feature Off)" 3 "Press gas pedal to re-engage the function" 4 "Speed Assist is unavailable Conditions not met" 5 "Resume not available Please activate Speed Assist button" 6 "Speed Assist is unavailable See Fault Details for more ingo" 7 "Speed Assist will off below 20kph. Issue with vehicle sensors" 8 "Take over driving now!" 9 "Take over driving now!Speed Assist Off" 10 "Take Over Driving , ACC Overspeed Occur!" 11 "Take over driving! Curvature max reached" 12 "Reserved" 13 "Reserved" 14 "Reserved" 15 "Reserved" ;
VAL_ 851 FCAM_ACC_check 0 "Available" 1 "Temporarily not available" 2 "Permanently not available" ;
VAL_ 851 FCAM_ISA_ICON_Feed 0 "Off" 1 "Gray ICON" 2 "Green ICON" 3 "White ICON" 4 "Yellow ICON" 5 "Red ICON" ;
VAL_ 851 FCAM_ACC_DistSet_lower_Feed 0 "-" 1 "Down_Feed" ;
VAL_ 851 FCAM_ACC_SpdSet_upper_Feed 0 "-" 1 "Up_Feed" ;
VAL_ 851 FCAM_ACC_SpdSet_lower_Feed 0 "-" 1 "Down_Feed" ;
VAL_ 851 FCAM_ACC_On_Feed 0 "Off" 1 "On" ;
VAL_ 851 FCAM_ACC_Set_Feed 0 "-" 1 "Set_Feed" ;
VAL_ 851 FCAM_ACC_CnlBtn_Feed 0 "-" 1 "Cancel_Feed" ;
VAL_ 851 FCAM_ACC_Res_Feed 0 "-" 1 "Res_Feed" ;
VAL_ 851 FCAM_ACC_ICON_Feed 0 "Off" 1 "Gray ICON" 2 "Green ICON" 3 "White ICON" 4 "Yellow ICON" 5 "Red ICON" ;
VAL_ 851 FCAM_ISA_Status 0 "OFF State" 1 "Passive" 2 "Standby" 3 "Active" 4 "Fault" ;
VAL_ 851 FCAM_ACC_DriveOff 0 "No request" 1 "DriveOff Request" ;
VAL_ 1115 FCAM_HOD_state_requesting 0 "Sleep_mode_requesting" 1 "Reserved" 2 "Normal_mode_requesting" 3 "Invalid value" ;
